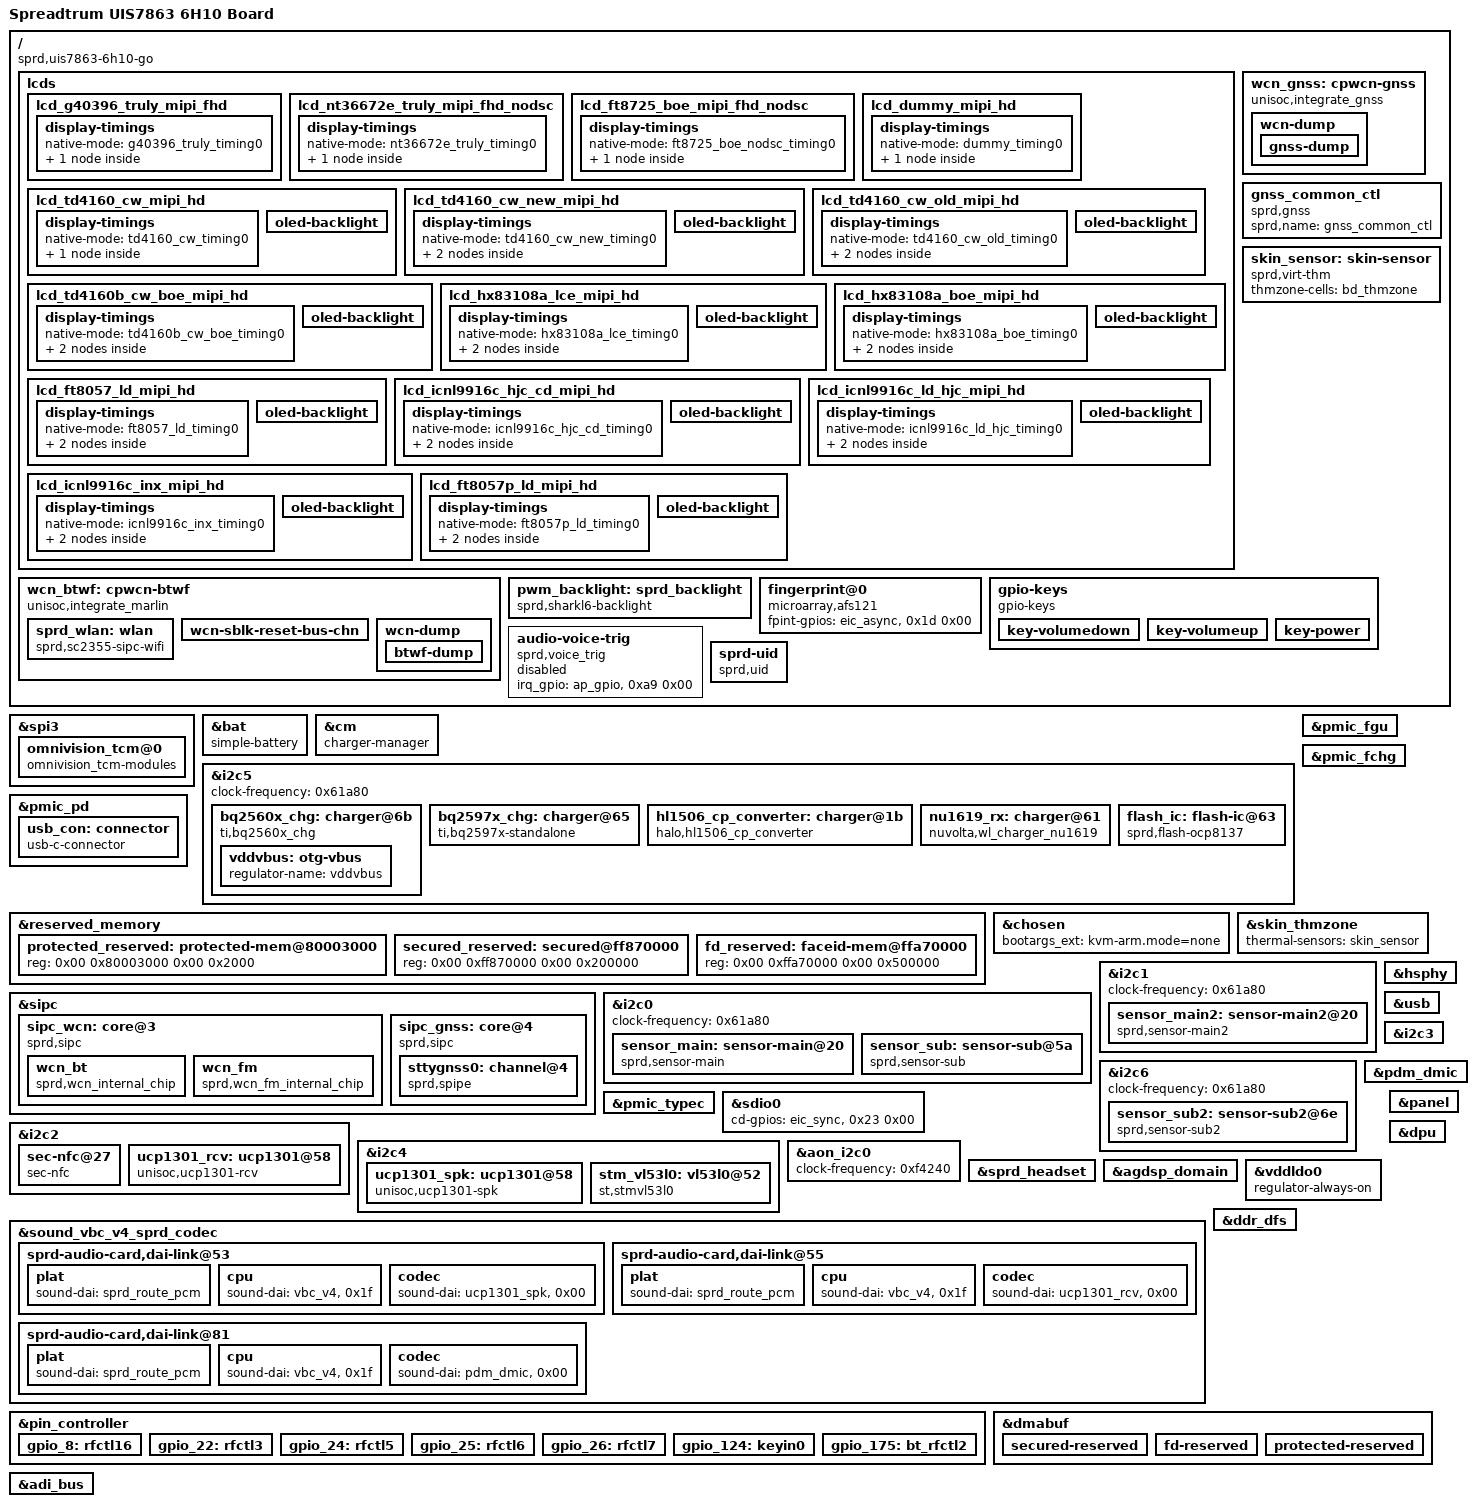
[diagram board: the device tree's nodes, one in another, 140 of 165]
/dts-v1/;
/plugin/;

/ {
	model = "Spreadtrum UIS7863 6H10 Board";
	compatible = "sprd,uis7863-6h10-go";
	sprd,sc-id = "uis7863 6h10 go";
	sprd,board_id = <0x690200>;

	fragment {
		target-path = "/";

		__overlay__ {
			#address-cells = <0x02>;
			#size-cells = <0x02>;

			lcds {

				lcd_g40396_truly_mipi_fhd: lcd_g40396_truly_mipi_fhd {
					sprd,dsi-work-mode = <0x01>;
					sprd,dsi-lane-number = <0x04>;
					sprd,dsi-color-format = "rgb888";
					sprd,phy-bit-clock = <0x104be0>;
					sprd,phy-escape-clock = <0x4e20>;
					sprd,power-gpio-delay = <0x14>;
					sprd,dpi-clk-div = <0x06>;
					sprd,video-lp-cmd-enable = <0x01>;
					sprd,hporch-lp-disable = <0x01>;
					sprd,width-mm = <0x44>;
					sprd,height-mm = <0x98>;
					sprd,slice-width = <0x21c>;
					sprd,slice-height = <0x960>;
					sprd,output-bpc = <0x08>;
					sprd,dsc-enable = <0x00>;
					sprd,dual-dsi-enable = <0x00>;
					sprd,esd-check-enable = <0x01>;
					sprd,esd-check-mode = <0x00>;
					sprd,esd-check-period = <0x7d0>;
					sprd,esd-check-regs = <0x0a>;
					sprd,esd-return-code = <0x9c>;
					sprd,reset-on-sequence = <0x01 0x05 0x00 0x05 0x01 0x14>;
					sprd,reset-off-sequence = <0x00 0x05>;
					sprd,use-dcs-write;
					sprd,initial-command = [29 00 00 02 00 00 29 00 00 04 ff 87 56 01 29 00 00 02 00 80 29 00 00 03 ff 87 56 29 00 00 02 00 a1 29 00 00 07 b3 04 38 09 60 00 fc 29 00 00 02 00 80 29 00 00 07 c0 00 8c 00 20 00 08 29 00 00 02 00 90 29 00 00 07 c0 00 8c 00 20 00 08 29 00 00 02 00 a0 29 00 00 07 c0 01 19 00 20 00 08 29 00 00 02 00 b0 29 00 00 06 c0 00 8c 00 20 08 29 00 00 02 00 c1 29 00 00 09 c0 00 d0 00 9f 00 8b 00 ee 29 00 00 02 00 d7 29 00 00 07 c0 00 8b 00 20 00 08 29 00 00 02 00 a3 29 00 00 07 c1 00 3e 00 3e 00 02 29 00 00 02 00 80 29 00 00 11 ce 01 81 09 13 00 d0 00 e8 00 82 00 9a 00 68 00 74 29 00 00 02 00 90 29 00 00 10 ce 00 8e 0c df 00 8e 80 09 13 00 04 00 08 08 08 29 00 00 02 00 a0 29 00 00 04 ce 00 00 00 29 00 00 02 00 b0 29 00 00 04 ce 22 00 00 29 00 00 02 00 d1 29 00 00 08 ce 00 00 01 00 00 00 00 29 00 00 02 00 e1 29 00 00 0c ce 08 02 4d 02 4d 02 4d 00 00 00 00 29 00 00 02 00 f1 29 00 00 0a ce 13 09 0d 00 f6 01 96 00 c2 29 00 00 02 00 b0 29 00 00 05 cf 00 00 68 6c 29 00 00 02 00 b5 29 00 00 05 cf 04 04 e4 e8 29 00 00 02 00 c0 29 00 00 05 cf 09 09 2c 30 29 00 00 02 00 c5 29 00 00 05 cf 00 00 08 0c 29 00 00 02 00 e8 29 00 00 02 c0 40 29 00 00 02 00 80 29 00 00 05 c2 84 01 3f 3f 29 00 00 02 00 90 29 00 00 05 c2 02 01 00 00 29 00 00 02 00 a0 29 00 00 10 c2 84 04 00 00 8a 83 04 00 00 8a 82 04 00 00 8a 29 00 00 02 00 b0 29 00 00 06 c2 81 04 00 00 8a 29 00 00 02 00 e0 29 00 00 0f c2 33 33 33 33 33 33 00 00 12 00 05 02 00 00 29 00 00 02 00 c0 29 00 00 05 c3 99 99 99 99 29 00 00 02 00 d0 29 00 00 0d c3 45 00 00 05 45 00 00 05 45 00 00 05 29 00 00 02 00 80 29 00 00 11 cb c1 c1 00 c1 c1 00 00 c1 fe 01 c1 00 fd c1 00 c0 29 00 00 02 00 90 29 00 00 11 cb c0 00 00 00 00 00 00 00 ff 00 00 00 00 00 00 00 29 00 00 02 00 a0 29 00 00 05 cb 00 00 00 00 29 00 00 02 00 b0 29 00 00 05 cb 55 55 95 55 29 00 00 02 00 c0 29 00 00 05 cb 10 51 94 50 29 00 00 02 00 80 29 00 00 11 cc 00 00 00 25 25 29 16 17 18 19 1a 1b 22 24 06 06 29 00 00 02 00 90 29 00 00 09 cc 08 08 24 02 12 01 29 29 29 00 00 02 00 80 29 00 00 11 cd 00 00 00 25 25 29 16 17 18 19 1a 1b 22 24 07 07 29 00 00 02 00 90 29 00 00 09 cd 09 09 24 02 12 01 29 29 29 00 00 02 00 a0 29 00 00 11 cc 00 00 00 25 25 29 16 17 18 19 1a 1b 24 23 09 09 29 00 00 02 00 b0 29 00 00 09 cc 07 07 24 12 02 01 29 29 29 00 00 02 00 a0 29 00 00 11 cd 00 00 00 25 25 29 16 17 18 19 1a 1b 24 23 08 08 29 00 00 02 00 b0 29 00 00 09 cd 06 06 24 12 02 01 29 29 29 00 00 02 00 80 29 00 00 02 a7 10 29 00 00 02 00 82 29 00 00 03 a7 33 02 29 00 00 02 00 85 29 00 00 02 a7 10 29 00 00 02 00 85 29 00 00 02 c4 1c 29 00 00 02 00 97 29 00 00 02 c4 01 29 00 00 02 00 a0 29 00 00 04 c4 2d d2 2d 29 00 00 02 00 93 29 00 00 02 c5 29 29 00 00 02 00 97 29 00 00 02 c5 29 29 00 00 02 00 9a 29 00 00 02 c5 23 29 00 00 02 00 9c 29 00 00 02 c5 23 29 00 00 02 00 b6 29 00 00 03 c5 1f 1f 29 00 00 02 00 b8 29 00 00 03 c5 19 19 29 00 00 02 00 9b 29 00 00 02 f5 4b 29 00 00 02 00 93 29 00 00 03 f5 00 00 29 00 00 02 00 9d 29 00 00 02 f5 49 29 00 00 02 00 82 29 00 00 03 f5 00 00 29 00 00 02 00 8c 29 00 00 04 c3 00 00 00 29 00 00 02 00 84 29 00 00 03 c5 28 28 29 00 00 02 00 a4 29 00 00 02 d7 00 29 00 00 02 00 80 29 00 00 03 f5 59 59 29 00 00 02 00 84 29 00 00 04 f5 59 59 59 29 00 00 02 00 96 29 00 00 02 f5 59 29 00 00 02 00 a6 29 00 00 02 f5 59 29 00 00 02 00 ca 29 00 00 02 c0 80 29 00 00 02 00 b1 29 00 00 02 f5 1f 29 00 00 02 00 00 29 00 00 03 d8 2f 2f 29 00 00 02 00 00 29 00 00 03 d9 23 23 29 00 00 02 00 86 29 00 00 07 c0 01 04 01 04 0e 03 29 00 00 02 00 96 29 00 00 07 c0 01 04 01 04 0d 03 29 00 00 02 00 a6 29 00 00 07 c0 01 04 01 04 18 03 29 00 00 02 00 e9 29 00 00 07 c0 01 04 01 04 0d 03 29 00 00 02 00 a3 29 00 00 07 ce 01 04 01 04 0d 03 29 00 00 02 00 b3 29 00 00 07 ce 01 04 01 04 0d 03 29 00 00 02 00 a0 29 00 00 02 d7 04 29 00 00 02 00 00 29 00 00 29 e1 00 04 08 0f 1a 1a 22 28 33 5c 3b 42 48 4d 1b 53 5b 63 6a 2b 72 79 81 8a 3a 95 9b a1 a9 0a b2 bd cb d4 6b e0 ee fa ff 17 29 00 00 02 00 00 29 00 00 29 e2 00 04 08 0f 1a 1a 22 28 33 5c 3b 42 48 4e 18 53 5b 63 6b 28 72 79 81 8a 2a 94 9b a1 a9 ca b2 bd cb d5 68 e0 ee fa ff 67 29 00 00 02 00 00 29 00 00 29 e3 00 03 07 0e 3f 19 21 27 31 46 39 40 47 4c b2 51 5a 61 69 8d 70 77 7f 88 68 92 97 9d a5 2c ad b7 c3 cb 58 d4 df e6 ea 7b 29 00 00 02 00 00 29 00 00 29 e4 00 03 07 0e 3f 19 21 27 31 45 39 40 47 4c b1 51 59 61 69 bd 70 77 7f 87 67 91 97 9d a5 ec ad b7 c3 cb 49 d4 e0 e6 ea 4b 29 00 00 02 00 00 29 00 00 29 e5 00 03 08 0e 33 19 20 27 31 31 39 41 47 4c 87 51 5a 62 69 d6 70 77 7f 88 b8 92 97 9e a5 32 ae b8 c5 ce 2c d8 e6 f0 f5 f6 29 00 00 02 00 00 29 00 00 29 e6 00 03 08 0e 33 19 20 27 31 31 39 41 47 4c 87 51 5a 62 69 d2 70 77 7f 88 b8 92 97 9e a5 32 ae b8 c5 ce 2d d9 e7 f0 f5 06 29 00 00 02 00 cc 29 00 00 02 c0 10 29 00 00 02 00 00 29 00 00 04 ff ff ff ff 15 00 00 02 35 00 15 00 00 02 51 ff 15 00 00 02 53 24 15 00 00 02 55 00 05 b4 00 01 11 05 64 00 01 29];
					sprd,sleep-in-command = <0x15000002 0x3900 0x4ff87 0x56011500 0x20080 0x39000003 0xff875605 0x128 0x5780001 0x10150000 0x2000039 0x5f7 0x5aa59527>;
					sprd,sleep-out-command = [05 78 00 01 11 05 00 00 01 29];
					sprd,sr-width = <0x2d0>;
					sprd,sr-height = <0x640>;
					phandle = <0x2a>;

					display-timings {
						native-mode = <&g40396_truly_timing0>;

						g40396_truly_timing0: timing0 {
							clock-frequency = <0xa9c1080>;
							hactive = <0x438>;
							vactive = <0x960>;
							hback-porch = <0x20>;
							hfront-porch = <0x30>;
							vback-porch = <0x20>;
							vfront-porch = <0x5b>;
							hsync-len = <0x10>;
							vsync-len = <0x04>;
							phandle = <0x01>;
						};
					};
				};

				lcd_nt36672e_truly_mipi_fhd_nodsc: lcd_nt36672e_truly_mipi_fhd_nodsc {
					sprd,dsi-work-mode = <0x01>;
					sprd,dsi-lane-number = <0x04>;
					sprd,dsi-color-format = "rgb888";
					sprd,phy-bit-clock = <0x104be0>;
					sprd,phy-escape-clock = <0x4e20>;
					sprd,dpi-clk-div = <0x06>;
					sprd,video-lp-cmd-enable = <0x01>;
					sprd,hporch-lp-disable = <0x01>;
					sprd,width-mm = <0x44>;
					sprd,height-mm = <0x98>;
					sprd,slice-width = <0x21c>;
					sprd,slice-height = <0x08>;
					sprd,output-bpc = <0x08>;
					sprd,dsc-enable = <0x00>;
					sprd,dual-dsi-enable = <0x00>;
					sprd,esd-check-enable = <0x00>;
					sprd,esd-check-mode = <0x00>;
					sprd,esd-check-period = <0x3e8>;
					sprd,esd-check-register = <0x0a>;
					sprd,esd-check-value = <0x9c>;
					sprd,reset-on-sequence = <0x01 0x0f 0x00 0x0f 0x01 0x0f>;
					sprd,reset-off-sequence = <0x00 0x05>;
					sprd,use-gen-write;
					sprd,initial-command = [15 00 00 02 ff 10 15 00 00 02 fb 01 15 00 00 02 b0 00 15 00 00 02 c0 00 29 00 00 11 c1 89 28 00 08 00 aa 02 0e 00 2b 00 07 0d b7 0c b7 29 00 00 03 c2 1b a0 15 00 00 02 ff 20 15 00 00 02 fb 01 15 00 00 02 01 66 15 00 00 02 06 40 15 00 00 02 07 38 15 00 00 02 2f 83 15 00 00 02 69 91 15 00 00 02 95 d1 15 00 00 02 96 d1 15 00 00 02 f2 64 15 00 00 02 f3 54 15 00 00 02 f4 64 15 00 00 02 f5 54 15 00 00 02 f6 64 15 00 00 02 f7 54 15 00 00 02 f8 64 15 00 00 02 f9 54 15 00 00 02 ff 24 15 00 00 02 fb 01 15 00 00 02 01 0f 15 00 00 02 03 0c 15 00 00 02 05 1d 15 00 00 02 08 2f 15 00 00 02 09 2e 15 00 00 02 0a 2d 15 00 00 02 0b 2c 15 00 00 02 11 17 15 00 00 02 12 13 15 00 00 02 13 15 15 00 00 02 15 14 15 00 00 02 16 16 15 00 00 02 17 18 15 00 00 02 1b 01 15 00 00 02 1d 1d 15 00 00 02 20 2f 15 00 00 02 21 2e 15 00 00 02 22 2d 15 00 00 02 23 2c 15 00 00 02 29 17 15 00 00 02 2a 13 15 00 00 02 2b 15 15 00 00 02 2f 14 15 00 00 02 30 16 15 00 00 02 31 18 15 00 00 02 32 04 15 00 00 02 34 10 15 00 00 02 35 1f 15 00 00 02 36 1f 15 00 00 02 4d 14 15 00 00 02 4e 36 15 00 00 02 4f 36 15 00 00 02 53 36 15 00 00 02 71 30 15 00 00 02 79 11 15 00 00 02 7a 82 15 00 00 02 7b 8f 15 00 00 02 7d 04 15 00 00 02 80 04 15 00 00 02 81 04 15 00 00 02 82 13 15 00 00 02 84 31 15 00 00 02 85 00 15 00 00 02 86 00 15 00 00 02 87 00 15 00 00 02 90 13 15 00 00 02 92 31 15 00 00 02 93 00 15 00 00 02 94 00 15 00 00 02 95 00 15 00 00 02 9c f4 15 00 00 02 9d 01 15 00 00 02 a0 0f 15 00 00 02 a2 0f 15 00 00 02 a3 02 15 00 00 02 a4 04 15 00 00 02 a5 04 15 00 00 02 c6 c0 15 00 00 02 c9 00 15 00 00 02 d9 80 15 00 00 02 e9 02 15 00 00 02 ff 25 15 00 00 02 fb 01 15 00 00 02 18 22 15 00 00 02 19 e4 15 00 00 02 21 40 15 00 00 02 66 d8 15 00 00 02 68 50 15 00 00 02 69 10 15 00 00 02 6b 00 15 00 00 02 6d 0d 15 00 00 02 6e 48 15 00 00 02 72 41 15 00 00 02 73 4a 15 00 00 02 74 d0 15 00 00 02 77 62 15 00 00 02 79 7e 15 00 00 02 7d 03 15 00 00 02 84 4d 15 00 00 02 cf 80 15 00 00 02 d6 80 15 00 00 02 d7 80 15 00 00 02 ef 20 15 00 00 02 f0 84 15 00 00 02 ff 26 15 00 00 02 fb 01 15 00 00 02 81 0f 15 00 00 02 83 01 15 00 00 02 84 03 15 00 00 02 85 01 15 00 00 02 86 03 15 00 00 02 87 01 15 00 00 02 88 05 15 00 00 02 8a 1a 15 00 00 02 8b 11 15 00 00 02 8c 24 15 00 00 02 8e 42 15 00 00 02 8f 11 15 00 00 02 90 11 15 00 00 02 91 11 15 00 00 02 9a 80 15 00 00 02 9b 04 15 00 00 02 9c 00 15 00 00 02 9d 00 15 00 00 02 9e 00 15 00 00 02 ff 27 15 00 00 02 fb 01 15 00 00 02 01 68 15 00 00 02 20 81 15 00 00 02 21 6a 15 00 00 02 25 81 15 00 00 02 26 94 15 00 00 02 6e 00 15 00 00 02 6f 00 15 00 00 02 70 00 15 00 00 02 71 00 15 00 00 02 72 00 15 00 00 02 75 00 15 00 00 02 76 00 15 00 00 02 77 00 15 00 00 02 7d 09 15 00 00 02 7e 67 15 00 00 02 80 23 15 00 00 02 82 09 15 00 00 02 83 67 15 00 00 02 88 01 15 00 00 02 89 10 15 00 00 02 a5 10 15 00 00 02 a6 23 15 00 00 02 a7 01 15 00 00 02 b6 40 15 00 00 02 e5 02 15 00 00 02 e6 d3 15 00 00 02 eb 03 15 00 00 02 ec 28 15 00 00 02 ff 2a 15 00 00 02 fb 01 15 00 00 02 00 91 15 00 00 02 03 20 15 00 00 02 07 50 15 00 00 02 0a 70 15 00 00 02 0c 04 15 00 00 02 0d 40 15 00 00 02 0f 01 15 00 00 02 11 e0 15 00 00 02 15 0f 15 00 00 02 16 a4 15 00 00 02 19 0f 15 00 00 02 1a 78 15 00 00 02 1b 23 15 00 00 02 1d 36 15 00 00 02 1e 3e 15 00 00 02 1f 3e 15 00 00 02 20 3e 15 00 00 02 28 fd 15 00 00 02 29 12 15 00 00 02 2a e1 15 00 00 02 2d 0a 15 00 00 02 30 49 15 00 00 02 33 96 15 00 00 02 34 ff 15 00 00 02 35 40 15 00 00 02 36 de 15 00 00 02 37 f9 15 00 00 02 38 45 15 00 00 02 39 d9 15 00 00 02 3a 49 15 00 00 02 4a f0 15 00 00 02 7a 09 15 00 00 02 7b 40 15 00 00 02 7f f0 15 00 00 02 83 0f 15 00 00 02 84 a4 15 00 00 02 87 0f 15 00 00 02 88 78 15 00 00 02 89 23 15 00 00 02 8b 36 15 00 00 02 8c 7d 15 00 00 02 8d 7d 15 00 00 02 8e 7d 15 00 00 02 ff 2c 15 00 00 02 fb 01 15 00 00 02 61 1f 15 00 00 02 62 1f 15 00 00 02 7e 03 15 00 00 02 6a 14 15 00 00 02 6b 36 15 00 00 02 6c 36 15 00 00 02 6d 36 15 00 00 02 53 04 15 00 00 02 54 04 15 00 00 02 55 04 15 00 00 02 56 0f 15 00 00 02 58 0f 15 00 00 02 59 0f 15 00 00 02 ff 20 15 00 00 02 fb 01 39 00 00 11 b0 00 e2 00 e9 00 f6 01 01 01 0c 01 15 01 20 01 28 39 00 00 11 b1 01 33 01 51 01 6e 01 9a 01 c0 01 fd 02 34 02 35 39 00 00 11 b2 02 6b 02 a9 02 d1 03 04 03 25 03 51 03 5f 03 6d 39 00 00 0f b3 03 7d 03 90 03 a7 03 bb 03 d4 03 d8 00 00 39 00 00 11 b4 00 aa 00 b3 00 c4 00 d4 00 e2 00 f0 00 fc 01 08 39 00 00 11 b5 01 12 01 39 01 58 01 8c 01 b5 01 f7 02 30 02 31 39 00 00 11 b6 02 68 02 a6 02 ce 03 01 03 23 03 4e 03 5c 03 6a 39 00 00 0f b7 03 7b 03 8e 03 a5 03 bb 03 d4 03 d8 00 00 39 00 00 11 b8 00 00 00 20 00 47 00 65 00 85 00 99 00 ad 00 c0 39 00 00 11 b9 00 d2 01 06 01 30 01 70 01 9f 01 e8 02 25 02 26 39 00 00 11 ba 02 5f 02 9f 02 c7 03 fd 03 20 03 52 03 63 03 67 39 00 00 0f bb 03 78 03 8b 03 a3 03 b9 03 d4 03 d8 00 00 15 00 00 02 ff 21 15 00 00 02 fb 01 39 00 00 11 b0 00 e2 00 e9 00 f6 01 01 01 0c 01 15 01 20 01 28 39 00 00 11 b1 01 33 01 51 01 6e 01 9a 01 c0 01 fd 02 34 02 35 39 00 00 11 b2 02 6b 02 a9 02 d1 03 04 03 25 03 51 03 5f 03 6d 39 00 00 0f b3 03 7d 03 90 03 a7 03 bb 03 d4 03 d8 00 00 39 00 00 11 b4 00 aa 00 b3 00 c4 00 d4 00 e2 00 f0 00 fc 01 08 39 00 00 11 b5 01 12 01 39 01 58 01 8c 01 b5 01 f7 02 30 02 31 39 00 00 11 b6 02 68 02 a6 02 ce 03 01 03 23 03 4e 03 5c 03 6a 39 00 00 0f b7 03 7b 03 8e 03 a5 03 bb 03 d4 03 d8 00 00 39 00 00 11 b8 00 00 00 20 00 47 00 65 00 85 00 99 00 ad 00 c0 39 00 00 11 b9 00 d2 01 06 01 30 01 70 01 9f 01 e8 02 25 02 26 39 00 00 11 ba 02 5f 02 9f 02 c7 02 fd 03 20 03 52 03 63 03 67 39 00 00 0f bb 03 78 03 8b 03 a3 03 b9 03 d4 03 d8 00 00 15 00 00 02 ff f0 15 00 00 02 fb 01 15 00 00 02 5a 00 15 00 00 02 ff 10 05 c8 00 01 11 05 32 00 01 29];
					sprd,sleep-in-command = [13 0a 00 01 28 13 78 00 01 10];
					sprd,sleep-out-command = [13 78 00 01 11 13 32 00 01 29];
					sprd,sr-width = <0x2d0>;
					sprd,sr-height = <0x640>;
					phandle = <0x2b>;

					display-timings {
						native-mode = <&nt36672e_truly_timing0>;

						nt36672e_truly_timing0: timing0 {
							clock-frequency = <0xa9c1080>;
							hactive = <0x438>;
							vactive = <0x968>;
							hback-porch = <0x23>;
							hfront-porch = <0x46>;
							vback-porch = <0x20>;
							vfront-porch = <0x20>;
							hsync-len = <0x0a>;
							vsync-len = <0x02>;
							phandle = <0x02>;
						};
					};
				};

				lcd_ft8725_boe_mipi_fhd_nodsc: lcd_ft8725_boe_mipi_fhd_nodsc {
					sprd,dsi-work-mode = <0x01>;
					sprd,dsi-lane-number = <0x04>;
					sprd,dsi-color-format = "rgb888";
					sprd,phy-bit-clock = <0xf9060>;
					sprd,phy-escape-clock = <0x4e20>;
					sprd,dpi-clk-div = <0x06>;
					sprd,video-lp-cmd-enable = <0x01>;
					sprd,hporch-lp-disable = <0x01>;
					sprd,width-mm = <0x44>;
					sprd,height-mm = <0x98>;
					sprd,esd-check-enable = <0x01>;
					sprd,esd-check-mode = <0x00>;
					sprd,esd-check-period = <0x3e8>;
					sprd,esd-check-register = <0x0a>;
					sprd,esd-check-value = <0x9c>;
					sprd,reset-on-sequence = <0x01 0x0f 0x00 0x0f 0x01 0x0f>;
					sprd,reset-off-sequence = <0x01 0x05>;
					sprd,use-gen-write;
					sprd,initial-command = [15 00 00 02 00 00 39 00 00 04 ff 87 25 01 15 00 00 02 00 80 39 00 00 03 ff 87 25 15 00 00 02 00 a3 39 00 00 05 b3 09 60 00 18 15 00 00 02 00 80 39 00 00 07 c0 00 4a 00 32 00 14 15 00 00 02 00 90 39 00 00 07 c0 00 4a 00 32 00 14 15 00 00 02 00 a0 39 00 00 07 c0 00 96 00 32 00 14 15 00 00 02 00 b0 39 00 00 06 c0 00 bb 00 32 14 15 00 00 02 00 c1 39 00 00 09 c0 00 94 00 75 00 63 00 b0 15 00 00 02 00 70 39 00 00 07 c0 00 9e 00 32 00 14 15 00 00 02 00 a3 39 00 00 07 c1 00 5c 00 3a 00 02 15 00 00 02 00 b7 39 00 00 03 c1 00 48 15 00 00 02 00 7b 39 00 00 03 ce ff ff 15 00 00 02 00 80 39 00 00 11 ce 01 81 ff ff 00 c0 00 c8 00 c0 00 c8 00 d0 00 d0 15 00 00 02 00 90 39 00 00 10 ce 00 a7 10 43 00 a7 80 ff ff 00 09 c4 10 0f 11 15 00 00 02 00 a0 39 00 00 04 ce 10 00 00 15 00 00 02 00 b0 39 00 00 04 ce 22 00 00 15 00 00 02 00 d1 39 00 00 08 ce 00 00 01 00 00 00 00 15 00 00 02 00 e1 39 00 00 0c ce 05 01 a1 02 b6 02 b6 00 00 00 00 15 00 00 02 00 f1 39 00 00 0a ce 2a 16 15 00 e8 00 ea 00 ec 15 00 00 02 00 b0 39 00 00 05 cf 00 00 b8 bc 15 00 00 02 00 b5 39 00 00 05 cf 05 05 68 6c 15 00 00 02 00 c0 39 00 00 05 cf 09 09 5b 5f 15 00 00 02 00 c5 39 00 00 05 cf 09 09 61 65 15 00 00 02 00 60 39 00 00 09 cf 00 00 cc d0 05 05 44 48 15 00 00 02 00 70 39 00 00 09 cf 00 00 bc c0 05 05 6c 70 15 00 00 02 00 d1 39 00 00 0d c1 0b 60 0f dc 1b 15 05 af 07 e5 0d 81 15 00 00 02 00 e1 39 00 00 03 c1 0f dc 15 00 00 02 00 e4 39 00 00 0d cf 09 f6 09 f5 09 f5 09 f5 09 f5 09 f5 15 00 00 02 00 80 39 00 00 03 c1 00 00 15 00 00 02 00 90 15 00 00 02 c1 03 15 00 00 02 00 f5 15 00 00 02 cf 00 15 00 00 02 00 f6 15 00 00 02 cf 78 15 00 00 02 00 f1 15 00 00 02 cf 78 15 00 00 02 00 93 15 00 00 02 c1 82 15 00 00 02 00 cc 15 00 00 02 c1 18 15 00 00 02 00 91 15 00 00 02 c4 08 15 00 00 02 00 80 39 00 00 03 c5 87 59 15 00 00 02 00 9e 15 00 00 02 c5 87 15 00 00 02 00 87 39 00 00 03 c4 08 08 15 00 00 02 00 80 39 00 00 09 c2 83 01 06 88 82 01 06 88 15 00 00 02 00 a0 39 00 00 10 c2 8a 07 00 06 88 89 08 00 06 88 88 09 00 06 88 15 00 00 02 00 b0 39 00 00 06 c2 87 0a 00 06 88 15 00 00 02 00 e0 39 00 00 05 c2 33 33 00 00 15 00 00 02 00 e8 39 00 00 09 c2 12 00 0a 0a 03 88 00 00 15 00 00 02 00 d0 39 00 00 11 c3 35 0a 00 00 35 0a 00 00 35 0a 00 00 35 0a 00 00 15 00 00 02 00 e0 39 00 00 11 c3 35 0a 00 00 35 0a 00 00 35 0a 00 00 35 0a 00 00 15 00 00 02 00 80 39 00 00 11 cb cd cd cc 00 cd cc 00 cd ce fe cd 00 cc cc 00 00 15 00 00 02 00 90 39 00 00 11 cb 0c 00 00 00 0c 0c 00 00 0c 00 00 00 00 00 00 00 15 00 00 02 00 a0 39 00 00 09 cb 00 00 00 00 00 00 00 00 15 00 00 02 00 b0 39 00 00 05 cb 50 41 a4 00 15 00 00 02 00 c0 39 00 00 05 cb 50 41 a4 00 15 00 00 02 00 d5 39 00 00 0c cb 83 00 83 83 00 83 83 00 83 83 00 15 00 00 02 00 e0 39 00 00 0e cb 83 83 00 83 83 00 83 83 00 83 83 00 83 15 00 00 02 00 80 39 00 00 11 cc 18 17 16 2c 07 06 09 08 2c 25 25 26 26 2c 24 2c 15 00 00 02 00 90 39 00 00 09 cc 22 23 23 01 03 02 26 26 15 00 00 02 00 a0 39 00 00 11 cc 18 17 16 2c 08 09 06 07 2c 25 25 22 22 2c 24 2c 15 00 00 02 00 b0 39 00 00 09 cc 26 23 23 01 02 03 26 26 15 00 00 02 00 80 39 00 00 11 cd 18 17 16 2c 07 06 09 08 2c 25 25 26 26 2c 24 2c 15 00 00 02 00 90 39 00 00 09 cd 22 23 23 01 03 02 26 26 15 00 00 02 00 a0 39 00 00 11 cd 18 17 16 2c 08 09 06 07 2c 25 25 22 22 2c 24 2c 15 00 00 02 00 b0 39 00 00 09 cd 26 23 23 01 02 03 26 26 15 00 00 02 00 86 39 00 00 09 c0 01 02 01 02 13 13 13 03 15 00 00 02 00 96 39 00 00 09 c0 01 02 01 01 13 13 13 04 15 00 00 02 00 a6 39 00 00 09 c0 01 02 01 01 28 28 28 04 15 00 00 02 00 a3 39 00 00 07 ce 01 02 01 05 28 02 15 00 00 02 00 b3 39 00 00 07 ce 01 02 01 05 28 02 15 00 00 02 00 76 39 00 00 09 c0 01 02 01 05 28 28 28 02 15 00 00 02 00 82 39 00 00 03 a7 20 00 15 00 00 02 00 8d 15 00 00 02 a7 02 15 00 00 02 00 8f 15 00 00 02 a7 01 15 00 00 02 00 93 15 00 00 02 c5 37 15 00 00 02 00 97 15 00 00 02 c5 37 15 00 00 02 00 9a 15 00 00 02 c5 23 15 00 00 02 00 9c 15 00 00 02 c5 23 15 00 00 02 00 b6 39 00 00 05 c5 2d 2d 19 19 15 00 00 02 00 00 39 00 00 03 d8 2f 27 15 00 00 02 00 00 39 00 00 05 d9 23 23 23 23 15 00 00 02 00 06 39 00 00 04 d9 23 23 23 15 00 00 02 00 88 15 00 00 02 c4 08 15 00 00 02 00 80 15 00 00 02 a7 10 15 00 00 02 00 a0 39 00 00 11 c3 00 01 23 45 21 03 45 00 00 00 21 03 45 01 23 45 15 00 00 02 00 b1 15 00 00 02 f5 1f 15 00 00 02 00 cb 15 00 00 02 c0 01 15 00 00 02 00 88 15 00 00 02 c4 08 15 00 00 02 00 94 15 00 00 02 e9 00 15 00 00 02 00 9a 15 00 00 02 c4 11 15 00 00 02 00 95 15 00 00 02 e9 10 15 00 00 02 00 82 15 00 00 02 f5 00 15 00 00 02 00 93 15 00 00 02 f5 00 15 00 00 02 00 99 15 00 00 02 cf 50 15 00 00 02 00 9c 15 00 00 02 f5 00 15 00 00 02 00 9e 15 00 00 02 f5 00 15 00 00 02 00 b0 39 00 00 07 c5 10 4a 01 1f 4a 00 15 00 00 02 00 a0 39 00 00 08 b0 00 00 00 00 00 1d 01 15 00 00 02 00 93 39 00 00 04 e9 ff ff b0 15 00 00 02 00 9b 15 00 00 02 c4 08 15 00 00 02 00 87 15 00 00 02 f5 00 15 00 00 02 00 80 15 00 00 02 a4 c9 15 00 00 02 00 87 39 00 00 03 c5 08 08 15 00 00 02 00 be 39 00 00 03 c5 c0 c0 15 00 00 02 00 e8 15 00 00 02 c0 40 15 00 00 02 00 00 39 00 00 29 e1 00 02 07 0f 3f 1b 24 2a 35 ce 3e 45 4b 50 06 55 5d 65 6c 7b 74 7b 83 8c 14 96 9c a2 aa 49 b3 bd cb d4 34 df ee f8 ff dc 15 00 00 02 00 30 39 00 00 29 e1 00 02 07 0f 3f 1b 24 2a 35 ce 3e 45 4b 50 06 55 5d 65 6c 7b 74 7b 83 8c 14 96 9c a2 aa 49 b3 bd cb d4 34 df ee f8 ff dc 15 00 00 02 00 60 39 00 00 29 e1 00 02 07 0f 3f 1b 24 2a 35 ce 3e 45 4b 50 06 55 5d 65 6c 7b 74 7b 83 8c 14 96 9c a2 aa 49 b3 bd cb d4 34 df ee f8 ff dc 15 00 00 02 00 90 39 00 00 29 e1 00 02 07 0f 3f 1b 24 2a 35 ce 3e 45 4b 50 06 55 5d 65 6c 7b 74 7b 83 8c 14 96 9c a2 aa 49 b3 bd cb d4 34 df ee f8 ff dc 15 00 00 02 00 c0 39 00 00 29 e1 00 02 07 0f 3f 1b 24 2a 35 ce 3e 45 4b 50 06 55 5d 65 6c 7b 74 7b 83 8c 14 96 9c a2 aa 49 b3 bd cb d4 34 df ee f8 ff dc 15 00 00 02 00 f0 39 00 00 11 e1 00 02 07 0f 3f 1b 24 2a 35 ce 3e 45 4b 50 06 55 15 00 00 02 00 00 39 00 00 19 e2 5d 65 6c 7b 74 7b 83 8c 14 96 9c a2 aa 49 b3 bd cb d4 34 df ee f8 ff dc 15 00 00 02 00 e0 15 00 00 02 cf 34 15 00 00 02 00 85 15 00 00 02 a7 00 15 00 00 02 00 80 15 00 00 02 b3 22 15 00 00 02 00 b0 15 00 00 02 b3 00 15 00 00 02 00 81 39 00 00 03 a4 23 23 15 00 00 02 00 90 15 00 00 02 e9 50 15 00 00 02 1c 02 05 78 00 01 11 05 14 00 01 29];
					sprd,sleep-in-command = [13 32 00 01 28 13 78 00 01 10];
					sprd,sleep-out-command = [13 78 00 01 11 13 32 00 01 29];
					phandle = <0x2c>;

					display-timings {
						native-mode = <&ft8725_boe_nodsc_timing0>;

						ft8725_boe_nodsc_timing0: timing0 {
							clock-frequency = <0xa21fe80>;
							hactive = <0x438>;
							vactive = <0x960>;
							hback-porch = <0x18>;
							hfront-porch = <0x18>;
							vback-porch = <0x1e>;
							vfront-porch = <0x2e>;
							hsync-len = <0x0c>;
							vsync-len = <0x0a>;
							phandle = <0x03>;
						};
					};
				};

				lcd_dummy_mipi_hd: lcd_dummy_mipi_hd {
					sprd,dsi-work-mode = <0x01>;
					sprd,dsi-lane-number = <0x04>;
					sprd,dsi-color-format = "rgb888";
					sprd,initial-command = [13 78 00 01 11 13 64 00 01 29];
					sprd,sleep-in-command = [13 0a 00 01 28 13 78 00 01 10];
					sprd,sleep-out-command = [13 78 00 01 11 13 64 00 01 29];
					phandle = <0x2d>;

					display-timings {
						native-mode = <&dummy_timing0>;

						dummy_timing0: timing0 {
							clock-frequency = <0x493e000>;
							hactive = <0x2d0>;
							vactive = <0x500>;
							hback-porch = <0x3c>;
							hfront-porch = <0x50>;
							vback-porch = <0x0c>;
							vfront-porch = <0x26>;
							hsync-len = <0x3c>;
							vsync-len = <0x04>;
							phandle = <0x04>;
						};
					};
				};

				lcd_td4160_cw_mipi_hd: lcd_td4160_cw_mipi_hd {
					sprd,dsi-work-mode = <0x01>;
					sprd,dsi-lane-number = <0x04>;
					sprd,dsi-color-format = "rgb888";
					sprd,phy-bit-clock = <0xa8b38>;
					sprd,phy-escape-clock = <0x4e20>;
					sprd,width-mm = <0x44>;
					sprd,height-mm = <0x97>;
					sprd,esd-check-enable = <0x00>;
					sprd,esd-check-mode = <0x01>;
					sprd,esd-check-period = <0x7d0>;
					sprd,reset-on-sequence = <0x00 0x05 0x01 0x1e>;
					sprd,reset-off-sequence = <0x00 0x05>;
					sprd,use-dcs-write;
					sprd,initial-command = [29 00 00 02 b0 00 29 00 00 02 d6 00 29 00 00 07 b6 30 62 00 86 c3 03 29 00 00 05 b7 31 00 00 00 29 00 00 07 b8 02 4a 06 00 04 5a 29 00 00 07 b9 02 4a 18 00 09 b4 29 00 00 07 ba 20 00 00 00 00 00 29 00 00 04 bb 00 b4 a0 29 00 00 04 bc 00 b4 a0 29 00 00 04 bd 00 b4 a0 29 00 00 0e be 07 00 00 00 00 00 00 00 00 00 00 00 00 29 00 00 19 c0 00 80 18 06 4c 00 16 08 68 00 70 00 00 00 00 00 00 00 00 00 00 00 00 00 29 00 00 28 c1 30 41 50 fa 01 00 00 10 00 00 00 00 40 0f 00 00 00 00 00 00 00 00 00 00 00 00 00 00 00 00 00 00 00 00 00 00 00 00 00 29 00 00 f5 c2 00 00 50 14 06 10 0e 00 00 00 00 50 12 06 10 0a 00 00 00 00 50 12 06 06 69 00 00 00 00 00 00 00 00 00 00 00 00 00 00 00 00 00 05 d0 56 0c 0c 06 00 c1 00 b0 01 03 00 41 00 00 00 00 00 11 00 00 00 00 00 00 00 00 00 00 00 00 00 00 00 00 00 00 00 00 00 00 00 00 00 00 00 00 00 00 00 11 00 00 00 00 00 00 00 00 00 00 00 00 00 00 00 00 00 00 00 00 00 00 00 00 00 00 00 00 00 00 00 11 00 00 00 00 00 00 00 00 00 00 00 00 00 00 00 00 00 00 00 00 00 00 00 00 00 00 00 00 00 00 00 11 00 00 00 00 00 00 00 00 00 00 00 00 00 00 00 00 00 00 00 00 00 00 00 00 00 00 00 00 00 00 00 00 00 00 00 00 00 00 00 10 00 00 00 00 00 00 00 00 00 00 00 00 00 00 00 02 00 00 00 00 00 00 00 00 00 00 02 00 00 00 00 00 00 00 00 00 00 00 00 00 00 00 00 00 00 00 29 00 00 6a c3 00 00 50 01 67 10 05 00 00 00 20 00 04 e0 00 41 64 c0 02 00 00 00 20 00 00 00 00 00 00 00 00 00 00 00 20 00 00 00 00 00 00 00 00 00 00 00 20 00 00 00 00 08 00 00 00 00 00 00 00 00 00 00 00 00 00 00 00 00 00 00 00 00 00 00 00 00 00 00 00 00 00 00 00 00 00 00 00 00 00 00 00 00 00 00 00 00 00 00 00 00 00 00 00 00 00 29 00 00 55 c4 00 5f 5f 0c 5d 04 06 08 01 14 14 16 16 18 18 1a 1a 1c 1c 1e 1e 5f 00 00 5f 1d 1d 1b 1b 19 19 17 17 15 15 13 13 01 07 05 03 5d 0b 5f 5f 00 00 00 00 00 00 00 ff 0f ff 0f 00 00 00 00 00 00 00 00 00 00 00 00 00 33 33 00 00 55 55 55 55 55 41 55 55 55 55 55 29 00 00 06 c5 08 00 00 00 00 29 00 00 4d c6 00 00 00 00 01 22 04 22 01 00 53 00 00 00 01 00 53 00 01 05 01 0b 01 35 ff 8f 06 15 01 c0 07 00 00 00 00 00 00 00 00 00 00 00 00 00 00 00 00 00 00 00 00 00 00 20 20 00 00 00 c0 11 00 00 00 10 10 00 00 00 01 00 50 00 33 03 00 00 29 00 00 1f cb 02 d0 01 80 00 00 00 00 00 00 00 00 00 00 00 00 00 00 00 00 00 00 40 70 00 00 00 00 00 ff 29 00 00 19 ce 16 40 60 78 87 94 9e ab b8 c4 cd d6 de e5 ec f3 ff 07 0f 00 00 00 04 8c 29 00 00 02 cf 00 29 00 00 15 d0 c1 50 81 66 09 90 00 cc 92 9f 11 1e 06 7e 09 08 cc 1b f0 06 29 00 00 26 d1 d0 d0 1b 33 33 17 07 bb 22 52 22 52 00 3b 77 07 3b 30 06 72 33 13 00 d7 0c 22 02 00 18 70 18 77 11 11 11 20 20 29 00 00 04 d2 00 00 00 29 00 00 9a d3 00 00 00 00 00 00 00 00 00 ff f7 ff ff f7 ff ff f7 ff ff f7 ff ff f7 ff ff f7 ff ff f7 ff ff f7 ff ff f7 ff ff f7 ff ff f7 ff ff f7 ff ff f7 ff ff f7 ff ff f7 ff ff f7 ff ff f7 ff ff f7 ff ff f7 ff ff f7 ff ff f7 ff ff f7 ff ff f7 ff ff f7 ff ff f7 ff ff f7 ff ff f7 ff ff f7 ff ff f7 ff ff f7 ff ff f7 ff ff f7 ff ff f7 ff ff f7 ff ff f7 ff ff f7 ff ff f7 ff ff f7 ff ff f7 ff ff f7 ff ff f7 ff ff f7 ff ff f7 ff ff f7 ff ff f7 ff ff f7 ff ff f7 ff ff f7 ff 29 00 00 18 d4 00 00 00 00 00 00 00 00 00 20 00 00 00 00 20 00 00 00 00 00 00 00 00 29 00 00 2f d7 01 00 12 12 00 54 01 04 00 54 01 04 03 83 80 85 85 85 87 84 45 86 87 80 88 86 89 83 83 87 84 88 8a 0c 0b 0a 0a 0a 07 07 06 06 00 08 0a 0a 29 00 00 17 d8 40 99 26 ed 16 6c 16 6c 16 6c 00 14 00 14 00 14 01 0c 00 00 01 00 29 00 00 29 d9 00 02 7f 00 00 00 00 00 00 00 00 00 00 00 00 c0 00 00 00 00 00 00 00 00 00 00 00 00 00 00 00 00 00 00 00 00 00 00 00 00 29 00 00 05 dd 30 06 23 65 29 00 00 0f de 00 00 00 0f ff 00 00 00 00 10 00 00 00 00 29 00 00 09 e6 00 00 00 00 00 00 00 00 29 00 00 24 ea 02 0e 0e 06 80 07 40 74 00 00 00 03 33 07 07 00 54 00 54 00 54 01 28 01 28 00 54 00 54 00 54 00 08 02 00 29 00 00 09 eb 08 30 83 0b 41 01 08 00 29 00 00 18 ec 05 f0 01 70 6b 07 40 74 00 00 00 02 2a 00 00 00 00 00 00 00 00 00 00 29 00 00 22 ed 01 02 00 00 00 00 00 00 67 c6 fe 00 00 00 00 00 00 00 00 00 00 00 02 b0 00 00 00 00 00 00 c0 10 00 29 00 00 7a ee 05 00 01 00 c0 57 00 c0 57 00 c0 57 00 00 03 00 c0 57 00 00 00 00 00 00 03 00 00 00 00 00 00 03 00 00 00 00 00 00 03 00 00 00 00 00 00 03 00 c0 57 00 00 00 00 00 c0 0f 00 00 00 00 00 00 57 00 00 00 00 00 00 03 00 00 00 00 00 00 03 00 00 03 00 00 03 00 00 03 00 00 03 00 00 03 00 00 03 00 00 00 00 00 00 00 00 00 00 00 00 00 00 00 00 00 00 00 00 00 00 00 00 00 02 29 00 00 0c f9 20 3f e0 00 00 07 ff 00 00 07 ff 29 00 00 4d c7 00 00 00 55 00 c2 01 0f 01 82 01 b5 01 b5 01 ba 01 b2 01 b1 01 ad 01 a7 01 a3 01 8c 01 99 02 2c 02 6f 02 9d 02 ff 00 00 00 55 00 c2 01 0f 01 82 01 b5 01 b5 01 ba 01 b2 01 b1 01 ad 01 a7 01 a3 01 8c 01 99 02 2c 02 6f 02 9d 02 ff 29 00 00 03 51 03 ff 29 00 00 02 53 2c 29 00 00 02 55 00 29 00 00 02 b0 03 05 60 00 01 11 05 20 00 01 29];
					sprd,sleep-in-command = [05 14 00 01 28 05 78 00 01 10];
					sprd,sleep-out-command = [05 14 00 01 11 05 78 00 01 29];
					sprd,cabc-off-command = [23 00 00 02 55 00];
					sprd,cabc-ui-command = [23 00 00 02 55 01];
					sprd,cabc-still-command = [23 00 00 02 55 02];
					sprd,cabc-moving-command = [23 00 00 02 55 03];
					phandle = <0x12>;

					display-timings {
						native-mode = <&td4160_cw_timing0>;

						td4160_cw_timing0: timing0 {
							clock-frequency = <0x5b8d800>;
							hactive = <0x2d0>;
							vactive = <0x64c>;
							hback-porch = <0x18>;
							hfront-porch = <0x38>;
							vback-porch = <0x1e>;
							vfront-porch = <0xac>;
							hsync-len = <0x04>;
							vsync-len = <0x04>;
							phandle = <0x05>;
						};
					};

					oled-backlight {
						default-brightness = <0x51a>;
						sprd,max-level = <0xfff>;
						brightness-levels = [39 00 00 03 51 00 04];
					};
				};

				lcd_td4160_cw_new_mipi_hd: lcd_td4160_cw_new_mipi_hd {
					sprd,dsi-work-mode = <0x01>;
					sprd,dsi-lane-number = <0x04>;
					sprd,dsi-color-format = "rgb888";
					sprd,phy-bit-clock = <0xf6180>;
					sprd,phy-escape-clock = <0x4e20>;
					sprd,dpi-clk-div = <0x06>;
					sprd,video-lp-cmd-enable = <0x01>;
					sprd,hporch-lp-disable = <0x01>;
					sprd,width-mm = <0x47>;
					sprd,height-mm = <0x9c>;
					sprd,esd-check-enable = <0x01>;
					sprd,esd-check-mode = <0x00>;
					sprd,esd-check-period = <0x7d0>;
					sprd,esd-check-register = <0x0a>;
					sprd,esd-check-value = <0x9c>;
					sprd,fixed-brightness = <0x01>;
					sprd,power-i2c-bus = <0x04>;
					sprd,power-i2c-addr = <0x3e>;
					sprd,power-i2c-reg = [00 01 03];
					sprd,power-i2c-val = [14 14 43];
					sprd,reset-on-sequence = <0x01 0x05 0x00 0x05 0x01 0x1e>;
					sprd,reset-off-sequence = <0x00 0x05>;
					sprd,video-lp-en-mode = <0x02>;
					sprd,use-dcs-write;
					sprd,initial-command = [39 00 00 02 b0 04 39 00 00 02 d6 00 39 00 00 07 b6 30 6a 00 86 c3 03 39 00 00 05 b7 31 00 00 00 39 00 00 07 b8 02 50 09 00 04 40 39 00 00 07 b9 02 09 18 00 09 46 39 00 00 07 ba 02 90 00 00 00 00 39 00 00 04 bb 00 b4 a0 39 00 00 04 bc 00 b4 a0 39 00 00 04 bd 00 b4 a0 39 00 00 0e be 07 00 00 00 00 00 00 00 00 00 00 00 00 39 00 00 19 c0 00 60 24 06 40 00 16 06 98 00 70 00 00 00 00 00 00 00 00 00 00 00 00 00 39 00 00 28 c1 30 81 50 fa 01 00 00 10 00 00 00 00 40 0f 00 00 00 00 00 00 00 00 00 00 00 00 00 00 00 00 00 00 f0 07 08 07 d0 0a be 39 00 00 65 c2 01 20 50 14 04 10 0b 10 00 00 00 00 00 00 00 00 00 00 00 00 00 00 00 00 00 00 00 00 00 00 00 00 00 00 00 00 00 00 00 00 00 00 05 f0 54 08 08 05 05 c5 00 80 00 00 00 00 08 00 00 00 00 11 00 80 00 08 00 00 00 00 00 00 00 00 00 00 00 00 00 00 00 00 00 00 00 00 00 00 00 00 00 00 00 11 00 00 00 00 00 00 39 00 00 65 c3 01 00 55 01 01 86 68 00 00 00 20 01 01 00 55 01 01 86 68 00 00 00 20 02 01 00 55 01 01 86 68 00 00 00 20 00 01 00 55 01 01 86 68 00 00 00 20 00 00 00 00 08 00 00 00 00 00 00 00 00 00 00 00 00 00 00 00 00 00 00 00 00 00 00 00 00 00 00 00 00 00 00 00 00 00 00 00 00 00 00 00 00 00 00 00 00 00 00 00 00 39 00 00 55 c4 00 00 5e 64 00 03 05 13 15 17 19 5d 5f 00 00 00 00 00 00 00 00 00 00 00 00 00 00 00 00 00 00 00 00 5f 5d 1a 18 16 14 06 04 00 64 5e 00 00 00 00 00 00 00 c0 03 00 00 3c 00 00 00 00 00 00 00 00 00 00 00 00 00 57 57 00 00 57 55 55 ff ff ff ff ff 55 55 d5 39 00 00 06 c5 08 00 00 00 00 39 00 00 4d c6 00 00 00 00 01 22 04 22 01 00 61 00 00 00 01 00 61 00 01 05 01 0b 01 35 ff 8f 06 c5 02 c0 0f 00 00 00 00 00 00 00 00 00 00 00 00 00 00 00 00 00 00 00 00 00 00 20 20 00 00 00 c0 11 00 00 00 10 10 00 00 00 01 00 50 00 33 03 00 00 39 00 00 1f cb 02 d0 01 80 00 00 00 00 00 00 00 00 00 00 00 00 00 00 00 00 00 00 40 70 00 00 00 00 00 ff 39 00 00 19 ce 16 56 66 88 9b aa bb c0 c8 cd d2 d8 e1 e7 ec f0 f3 07 0f 00 00 00 04 8c 39 00 00 02 cf 00 39 00 00 15 d0 c1 46 81 66 09 90 00 cc f2 ff 11 46 06 7e 09 08 cc 1b f0 06 39 00 00 26 d1 ce d8 1b 33 33 17 07 bb 22 52 22 52 00 3b 77 07 3b 30 06 72 33 13 00 d7 0c 22 02 00 18 70 18 77 11 11 11 20 20 39 00 00 04 d2 00 00 00 39 00 00 65 d3 00 00 00 00 00 00 00 00 00 ff f7 ff ff f7 ff ff f7 ff ff f7 ff ff f7 ff ff f7 ff ff f7 ff ff f7 ff ff f7 ff ff f7 ff ff f7 ff ff f7 ff ff f7 ff ff f7 ff ff f7 ff ff f7 ff ff f7 ff ff f7 ff ff f7 ff ff f7 ff ff f7 ff ff f7 ff ff f7 ff ff f7 ff ff f7 ff ff f7 ff ff f7 ff ff f7 ff ff f7 ff ff f7 ff ff 39 00 00 18 d4 00 00 00 00 00 00 00 00 00 20 00 00 00 00 20 00 00 00 00 00 00 00 00 39 00 00 02 d6 00 39 00 00 2f d7 01 00 12 12 00 62 00 16 00 62 00 16 03 83 80 85 85 85 87 84 45 86 87 80 88 86 89 83 83 87 84 88 8a 0c 0b 0a 0a 0a 07 07 06 06 00 08 0a 0a 39 00 00 17 d8 40 99 26 ed 16 6c 16 6c 16 6c 00 14 00 14 00 14 01 0c 00 00 01 00 39 00 00 29 d9 00 02 7f 00 00 00 00 00 00 00 00 00 00 00 00 c0 00 00 00 00 00 00 00 00 00 00 00 00 00 00 00 00 00 00 00 00 00 00 00 00 39 00 00 05 dd 30 06 23 65 39 00 00 0f de 00 00 00 0f ff 00 00 00 00 10 00 00 00 00 39 00 00 05 e5 03 00 00 00 39 00 00 09 e6 00 00 00 00 00 0e 00 00 39 00 00 24 ea 02 07 07 04 80 10 01 00 00 00 00 03 23 00 07 00 ed 00 ed 00 ed 01 28 01 28 00 62 00 62 00 62 01 0f 01 00 39 00 00 09 eb 06 e0 6e 07 61 01 01 00 39 00 00 18 ec 02 d0 01 70 73 10 01 00 00 00 00 02 2a 00 00 00 00 00 00 00 00 00 00 39 00 00 22 ed 01 02 00 00 00 00 00 00 67 a6 f0 00 00 00 00 00 00 00 00 00 00 00 00 f0 01 00 00 00 00 00 41 10 01 39 00 00 65 ee 05 00 05 00 c0 0b 00 00 03 00 00 03 00 00 03 00 c0 03 00 00 00 00 00 00 03 00 00 00 00 00 00 03 00 00 00 00 00 00 03 00 00 00 00 00 00 03 00 40 03 04 65 40 00 00 55 17 04 65 40 00 00 55 03 04 65 40 00 00 40 17 04 65 40 00 00 00 03 00 00 03 00 00 03 00 00 03 00 00 03 00 00 03 00 00 03 00 40 15 00 00 39 00 00 0c f9 20 3f e0 00 00 07 ff 00 00 07 ff 39 00 00 02 35 00 39 00 00 4d c7 00 00 00 77 00 ca 00 e7 01 00 01 0b 01 1a 01 1d 01 3d 01 0f 01 67 01 2d 01 78 01 2b 01 9b 01 a6 02 2f 02 96 02 a0 00 00 00 77 00 ca 00 e7 01 00 01 0b 01 1a 01 1d 01 3d 01 0f 01 67 01 2d 01 78 01 2b 01 9b 01 a6 02 2f 02 96 02 a0 39 00 00 02 53 24 39 00 00 02 55 00 39 00 00 02 b0 03 05 60 00 01 11 05 20 00 01 29];
					sprd,sleep-in-command = [05 14 00 01 28 05 78 00 01 10];
					sprd,sleep-out-command = [05 14 00 01 11 05 78 00 01 29];
					sprd,cabc-off-command = [39 00 00 02 55 03];
					sprd,cabc-ui-command = [39 00 00 02 55 01];
					sprd,cabc-still-command = [39 00 00 02 55 02];
					sprd,cabc-moving-command = [39 00 00 02 55 03];
					phandle = <0x11>;

					display-timings {
						native-mode = <&td4160_cw_new_timing0>;

						td4160_cw_new_timing0: timing0 {
							clock-frequency = <0xa037a00>;
							hactive = <0x2d0>;
							vactive = <0x640>;
							hback-porch = <0x68>;
							hfront-porch = <0xe0>;
							vback-porch = <0x20>;
							vfront-porch = <0x3fe>;
							hsync-len = <0x04>;
							vsync-len = <0x04>;
							phandle = <0x06>;
						};

						td4160_cw_new_timing1: timing1 {
							clock-frequency = <0xa037a00>;
							hactive = <0x2d0>;
							vactive = <0x640>;
							hback-porch = <0x64>;
							hfront-porch = <0xe0>;
							vback-porch = <0x20>;
							vfront-porch = <0x90>;
							hsync-len = <0x04>;
							vsync-len = <0x04>;
							phandle = <0x2e>;
						};
					};

					oled-backlight {
						default-brightness = <0x51a>;
						sprd,max-level = <0xfff>;
						brightness-levels = [39 00 00 03 51 00 00];
					};
				};

				lcd_td4160_cw_old_mipi_hd: lcd_td4160_cw_old_mipi_hd {
					sprd,dsi-work-mode = <0x01>;
					sprd,dsi-lane-number = <0x04>;
					sprd,dsi-color-format = "rgb888";
					sprd,phy-bit-clock = <0xf6180>;
					sprd,phy-escape-clock = <0x4e20>;
					sprd,dpi-clk-div = <0x06>;
					sprd,video-lp-cmd-enable = <0x01>;
					sprd,hporch-lp-disable = <0x01>;
					sprd,width-mm = <0x47>;
					sprd,height-mm = <0x9c>;
					sprd,esd-check-enable = <0x01>;
					sprd,esd-check-mode = <0x00>;
					sprd,esd-check-period = <0x7d0>;
					sprd,esd-check-register = <0x0a>;
					sprd,esd-check-value = <0x9c>;
					sprd,fixed-brightness = <0x01>;
					sprd,power-i2c-bus = <0x04>;
					sprd,power-i2c-addr = <0x3e>;
					sprd,power-i2c-reg = [00 01 03];
					sprd,power-i2c-val = [14 14 43];
					sprd,reset-on-sequence = <0x01 0x05 0x00 0x05 0x01 0x1e>;
					sprd,reset-off-sequence = <0x00 0x05>;
					sprd,video-lp-en-mode = <0x02>;
					sprd,use-dcs-write;
					sprd,initial-command = [39 00 00 02 b0 04 39 00 00 02 d6 00 39 00 00 07 b6 30 6a 00 86 c3 03 39 00 00 05 b7 31 00 00 00 39 00 00 07 b8 02 50 09 00 04 40 39 00 00 07 b9 02 09 18 00 09 46 39 00 00 07 ba 02 90 00 00 00 00 39 00 00 04 bb 00 b4 a0 39 00 00 04 bc 00 b4 a0 39 00 00 04 bd 00 b4 a0 39 00 00 0e be 07 00 00 00 00 00 00 00 00 00 00 00 00 39 00 00 19 c0 00 60 24 06 40 00 16 06 98 00 70 00 00 00 00 00 00 00 00 00 00 00 00 00 39 00 00 28 c1 30 81 50 fa 01 00 00 10 00 00 00 00 40 0f 00 00 00 00 00 00 00 00 00 00 00 00 00 00 00 00 00 00 f0 07 08 07 d0 0a be 39 00 00 65 c2 01 20 50 14 04 10 0b 10 00 00 00 00 00 00 00 00 00 00 00 00 00 00 00 00 00 00 00 00 00 00 00 00 00 00 00 00 00 00 00 00 00 00 05 f0 54 08 08 05 05 c5 00 80 00 00 00 00 08 00 00 00 00 11 00 80 00 08 00 00 00 00 00 00 00 00 00 00 00 00 00 00 00 00 00 00 00 00 00 00 00 00 00 00 00 11 00 00 00 00 00 00 39 00 00 65 c3 01 00 55 01 01 86 68 00 00 00 20 01 01 00 55 01 01 86 68 00 00 00 20 02 01 00 55 01 01 86 68 00 00 00 20 00 01 00 55 01 01 86 68 00 00 00 20 00 00 00 00 08 00 00 00 00 00 00 00 00 00 00 00 00 00 00 00 00 00 00 00 00 00 00 00 00 00 00 00 00 00 00 00 00 00 00 00 00 00 00 00 00 00 00 00 00 00 00 00 00 39 00 00 55 c4 00 00 5e 64 00 03 05 13 15 17 19 5d 5f 00 00 00 00 00 00 00 00 00 00 00 00 00 00 00 00 00 00 00 00 5f 5d 1a 18 16 14 06 04 00 64 5e 00 00 00 00 00 00 00 c0 03 00 00 3c 00 00 00 00 00 00 00 00 00 00 00 00 00 57 57 00 00 57 55 55 ff ff ff ff ff 55 55 d5 39 00 00 06 c5 08 00 00 00 00 39 00 00 4d c6 00 00 00 00 01 22 04 22 01 00 61 00 00 00 01 00 61 00 01 05 01 0b 01 35 ff 8f 06 c5 02 c0 0f 00 00 00 00 00 00 00 00 00 00 00 00 00 00 00 00 00 00 00 00 00 00 20 20 00 00 00 c0 11 00 00 00 10 10 00 00 00 01 00 50 00 33 03 00 00 39 00 00 1f cb 02 d0 01 80 00 00 00 00 00 00 00 00 00 00 00 00 00 00 00 00 00 00 40 70 00 00 00 00 00 ff 39 00 00 19 ce 16 56 66 88 9b aa bb c0 c8 cd d2 d8 e1 e7 ec f0 f3 07 0f 00 00 00 04 8c 39 00 00 02 cf 00 39 00 00 15 d0 c1 46 81 66 09 90 00 cc f2 ff 11 46 06 7e 09 08 cc 1b f0 06 39 00 00 26 d1 ce d8 1b 33 33 17 07 bb 22 52 22 52 00 3b 77 07 3b 30 06 72 33 13 00 d7 0c 22 02 00 18 70 18 77 11 11 11 20 20 39 00 00 04 d2 00 00 00 39 00 00 65 d3 00 00 00 00 00 00 00 00 00 ff f7 ff ff f7 ff ff f7 ff ff f7 ff ff f7 ff ff f7 ff ff f7 ff ff f7 ff ff f7 ff ff f7 ff ff f7 ff ff f7 ff ff f7 ff ff f7 ff ff f7 ff ff f7 ff ff f7 ff ff f7 ff ff f7 ff ff f7 ff ff f7 ff ff f7 ff ff f7 ff ff f7 ff ff f7 ff ff f7 ff ff f7 ff ff f7 ff ff f7 ff ff f7 ff ff 39 00 00 18 d4 00 00 00 00 00 00 00 00 00 20 00 00 00 00 20 00 00 00 00 00 00 00 00 39 00 00 02 d6 00 39 00 00 2f d7 01 00 12 12 00 62 00 16 00 62 00 16 03 83 80 85 85 85 87 84 45 86 87 80 88 86 89 83 83 87 84 88 8a 0c 0b 0a 0a 0a 07 07 06 06 00 08 0a 0a 39 00 00 17 d8 40 99 26 ed 16 6c 16 6c 16 6c 00 14 00 14 00 14 01 0c 00 00 01 00 39 00 00 29 d9 00 02 7f 00 00 00 00 00 00 00 00 00 00 00 00 c0 00 00 00 00 00 00 00 00 00 00 00 00 00 00 00 00 00 00 00 00 00 00 00 00 39 00 00 05 dd 30 06 23 65 39 00 00 0f de 00 00 00 0f ff 00 00 00 00 10 00 00 00 00 39 00 00 05 e5 03 00 00 00 39 00 00 09 e6 00 00 00 00 00 0e 00 00 39 00 00 24 ea 02 07 07 04 80 10 01 00 00 00 00 03 23 00 07 00 ed 00 ed 00 ed 01 28 01 28 00 62 00 62 00 62 01 0f 01 00 39 00 00 09 eb 06 e0 6e 07 61 01 01 00 39 00 00 18 ec 02 d0 01 70 73 10 01 00 00 00 00 02 2a 00 00 00 00 00 00 00 00 00 00 39 00 00 22 ed 01 02 00 00 00 00 00 00 67 a6 f0 00 00 00 00 00 00 00 00 00 00 00 00 f0 01 00 00 00 00 00 41 10 01 39 00 00 65 ee 05 00 05 00 c0 0b 00 00 03 00 00 03 00 00 03 00 c0 03 00 00 00 00 00 00 03 00 00 00 00 00 00 03 00 00 00 00 00 00 03 00 00 00 00 00 00 03 00 40 03 04 65 40 00 00 55 17 04 65 40 00 00 55 03 04 65 40 00 00 40 17 04 65 40 00 00 00 03 00 00 03 00 00 03 00 00 03 00 00 03 00 00 03 00 00 03 00 40 15 00 00 39 00 00 0c f9 20 3f e0 00 00 07 ff 00 00 07 ff 39 00 00 02 35 00 39 00 00 4d c7 00 00 00 72 00 b9 00 d4 00 ed 00 f8 01 08 01 0c 01 2c 00 fe 01 57 01 1d 01 63 01 22 01 92 01 9e 02 27 02 92 02 a0 00 00 00 72 00 b9 00 d4 00 ed 00 f8 01 08 01 0c 01 2c 00 fe 01 57 01 1d 01 63 01 22 01 92 01 9e 02 27 02 92 02 a0 39 00 00 02 53 24 39 00 00 02 55 00 39 00 00 02 b0 03 05 60 00 01 11 05 20 00 01 29];
					sprd,sleep-in-command = [05 14 00 01 28 05 78 00 01 10];
					sprd,sleep-out-command = [05 14 00 01 11 05 78 00 01 29];
					sprd,cabc-off-command = [39 00 00 02 55 03];
					sprd,cabc-ui-command = [39 00 00 02 55 01];
					sprd,cabc-still-command = [39 00 00 02 55 02];
					sprd,cabc-moving-command = [39 00 00 02 55 03];
					phandle = <0x10>;

					display-timings {
						native-mode = <&td4160_cw_old_timing0>;

						td4160_cw_old_timing0: timing0 {
							clock-frequency = <0xa037a00>;
							hactive = <0x2d0>;
							vactive = <0x640>;
							hback-porch = <0x68>;
							hfront-porch = <0xe0>;
							vback-porch = <0x20>;
							vfront-porch = <0x3fe>;
							hsync-len = <0x04>;
							vsync-len = <0x04>;
							phandle = <0x07>;
						};

						td4160_cw_old_timing1: timing1 {
							clock-frequency = <0xa037a00>;
							hactive = <0x2d0>;
							vactive = <0x640>;
							hback-porch = <0x64>;
							hfront-porch = <0xe0>;
							vback-porch = <0x20>;
							vfront-porch = <0x90>;
							hsync-len = <0x04>;
							vsync-len = <0x04>;
							phandle = <0x2f>;
						};
					};

					oled-backlight {
						default-brightness = <0x51a>;
						sprd,max-level = <0xfff>;
						brightness-levels = [39 00 00 03 51 00 00];
					};
				};

				lcd_td4160b_cw_boe_mipi_hd: lcd_td4160b_cw_boe_mipi_hd {
					sprd,dsi-work-mode = <0x01>;
					sprd,dsi-lane-number = <0x04>;
					sprd,dsi-color-format = "rgb888";
					sprd,phy-bit-clock = <0xdbba0>;
					sprd,phy-escape-clock = <0x4e20>;
					sprd,dpi-clk-div = <0x06>;
					sprd,video-lp-cmd-enable = <0x01>;
					sprd,hporch-lp-disable = <0x01>;
					sprd,width-mm = <0x47>;
					sprd,height-mm = <0x9c>;
					sprd,esd-check-enable = <0x01>;
					sprd,esd-check-mode = <0x00>;
					sprd,esd-check-period = <0x7d0>;
					sprd,esd-check-register = <0x0a>;
					sprd,esd-check-value = <0x9c>;
					sprd,reset-on-sequence = <0x01 0x05 0x00 0x05 0x01 0x1e>;
					sprd,reset-off-sequence = <0x00 0x05>;
					sprd,use-dcs-write;
					sprd,initial-command = [39 00 00 02 b0 04 39 00 00 02 d6 00 39 00 00 07 b6 30 6a 00 86 c3 03 39 00 00 05 b7 31 00 00 00 39 00 00 07 b8 02 50 09 00 04 40 39 00 00 07 b9 02 09 18 00 09 46 39 00 00 07 ba 06 90 00 00 00 00 39 00 00 04 bb 00 b4 a0 39 00 00 04 bc 00 b4 a0 39 00 00 04 bd 00 b4 a0 39 00 00 0e be 07 00 00 00 00 00 00 00 00 00 00 00 00 39 00 00 19 c0 00 60 24 06 40 00 16 06 98 00 70 00 00 00 00 00 00 00 00 00 00 00 00 00 39 00 00 28 c1 30 81 50 fa 01 00 00 10 00 00 00 00 40 0f 00 00 00 00 00 00 00 00 00 00 00 00 00 00 00 00 00 00 f0 07 08 07 d0 0a be 39 00 00 65 c2 01 20 50 14 04 10 0b 10 00 00 00 00 00 00 00 00 00 00 00 00 00 00 00 00 00 00 00 00 00 00 00 00 00 00 00 00 00 00 00 00 00 00 05 f0 54 08 08 05 05 c5 00 80 00 00 00 00 08 00 00 00 00 11 00 80 00 08 00 00 00 00 00 00 00 00 00 00 00 00 00 00 00 00 00 00 00 00 00 00 00 00 00 00 00 11 00 00 00 00 00 00 39 00 00 65 c3 01 00 55 01 01 86 68 00 00 00 20 01 01 00 55 01 01 86 68 00 00 00 20 02 01 00 55 01 01 86 68 00 00 00 20 00 01 00 55 01 01 86 68 00 00 00 20 00 00 00 00 08 00 00 00 00 00 00 00 00 00 00 00 00 00 00 00 00 00 00 00 00 00 00 00 00 00 00 00 00 00 00 00 00 00 00 00 00 00 00 00 00 00 00 00 00 00 00 00 00 39 00 00 55 c4 00 00 5e 64 00 03 05 13 15 17 19 5d 5f 00 00 00 00 00 00 00 00 00 00 00 00 00 00 00 00 00 00 00 00 5f 5d 1a 18 16 14 06 04 00 64 5e 00 00 00 00 00 00 00 c0 03 00 00 3c 00 00 00 00 00 00 00 00 00 00 00 00 00 57 57 00 00 57 55 55 ff ff ff ff ff 55 55 d5 39 00 00 06 c5 08 00 00 00 00 39 00 00 4d c6 00 00 00 00 01 22 04 22 01 00 61 00 00 00 01 00 61 00 01 05 01 0b 01 35 ff 8f 06 c5 02 c0 0f 00 00 00 00 00 00 00 00 00 00 00 00 00 00 00 00 00 00 00 00 00 00 20 20 00 00 00 c0 11 00 00 00 10 10 00 00 00 01 00 50 00 33 03 00 00 39 00 00 1f cb 02 d0 01 80 00 00 00 00 00 00 00 00 00 00 00 00 00 00 00 00 00 00 40 70 00 00 00 00 00 ff 39 00 00 19 ce 16 56 66 88 9b aa bb c0 c8 cd d2 d8 e1 e7 ec f0 f3 07 0f 00 00 00 04 8c 39 00 00 02 cf 00 39 00 00 15 d0 c1 46 81 66 09 90 00 cc f2 ff 11 46 06 7e 09 08 cc 1b f0 06 39 00 00 26 d1 ce d8 1b 33 33 17 07 bb 22 52 22 52 00 3b 77 07 3b 30 06 72 33 13 00 d7 0c 22 02 00 18 70 18 77 11 11 11 20 20 39 00 00 04 d2 00 00 00 39 00 00 65 d3 00 00 00 00 00 00 00 00 00 ff f7 ff ff f7 ff ff f7 ff ff f7 ff ff f7 ff ff f7 ff ff f7 ff ff f7 ff ff f7 ff ff f7 ff ff f7 ff ff f7 ff ff f7 ff ff f7 ff ff f7 ff ff f7 ff ff f7 ff ff f7 ff ff f7 ff ff f7 ff ff f7 ff ff f7 ff ff f7 ff ff f7 ff ff f7 ff ff f7 ff ff f7 ff ff f7 ff ff f7 ff ff f7 ff ff 39 00 00 18 d4 00 00 00 00 00 00 00 00 00 20 00 00 00 00 20 00 00 00 00 00 00 00 00 39 00 00 02 d6 00 39 00 00 2f d7 01 00 12 12 00 62 00 16 00 62 00 16 03 83 80 85 85 85 87 84 45 86 87 80 88 86 89 83 83 87 84 88 8a 0c 0b 0a 0a 0a 07 07 06 06 00 08 0a 0a 39 00 00 17 d8 40 99 26 ed 16 6c 16 6c 16 6c 00 14 00 14 00 14 01 0c 00 00 01 00 39 00 00 29 d9 00 02 7f 00 00 00 00 00 00 00 00 00 00 00 00 c0 00 00 00 00 00 00 00 00 00 00 00 00 00 00 00 00 00 00 00 00 00 00 00 00 39 00 00 05 dd 30 06 23 65 39 00 00 0f de 00 00 00 0f ff 00 00 00 00 10 00 00 00 00 39 00 00 05 e5 03 00 00 00 39 00 00 09 e6 00 00 00 00 00 0e 00 00 39 00 00 24 ea 02 07 07 04 80 10 01 00 00 00 00 03 23 00 07 00 ed 00 ed 00 ed 01 28 01 28 00 62 00 62 00 62 01 0f 01 00 39 00 00 09 eb 06 e0 6e 07 61 01 01 00 39 00 00 18 ec 02 d0 01 70 73 10 01 00 00 00 00 02 2a 00 00 00 00 00 00 00 00 00 00 39 00 00 22 ed 01 02 00 00 00 00 00 00 67 a6 f0 00 00 00 00 00 00 00 00 00 00 00 00 f0 01 00 00 00 00 00 41 10 01 39 00 00 65 ee 05 00 05 00 c0 0b 00 00 03 00 00 03 00 00 03 00 c0 03 00 00 00 00 00 00 03 00 00 00 00 00 00 03 00 00 00 00 00 00 03 00 00 00 00 00 00 03 00 40 03 04 65 40 00 00 55 17 04 65 40 00 00 55 03 04 65 40 00 00 40 17 04 65 40 00 00 00 03 00 00 03 00 00 03 00 00 03 00 00 03 00 00 03 00 00 03 00 40 15 00 00 39 00 00 0c f9 20 3f e0 00 00 07 ff 00 00 07 ff 39 00 00 02 35 00 39 00 00 4d c7 00 00 00 6d 00 af 00 cc 00 e1 00 ee 00 ff 01 00 01 1e 00 f1 01 4b 01 12 01 59 01 17 01 85 01 97 02 1e 02 94 02 a0 00 00 00 6d 00 af 00 cc 00 e1 00 ee 00 ff 01 00 01 1e 00 f1 01 4b 01 12 01 59 01 17 01 85 01 97 02 1e 02 94 02 a0 39 00 00 02 53 24 39 00 00 02 55 00 39 00 00 02 b0 03 05 60 00 01 11 05 20 00 01 29];
					sprd,sleep-in-command = [05 14 00 01 28 05 78 00 01 10];
					sprd,sleep-out-command = [05 14 00 01 11 05 78 00 01 29];
					sprd,cabc-off-command = [39 00 00 02 55 00];
					sprd,cabc-ui-command = [39 00 00 02 55 01];
					sprd,cabc-still-command = [39 00 00 02 55 02];
					sprd,cabc-moving-command = [39 00 00 02 55 03];
					phandle = <0x19>;

					display-timings {
						native-mode = <&td4160b_cw_boe_timing0>;

						td4160b_cw_boe_timing0: timing0 {
							clock-frequency = <0x8f0d180>;
							hactive = <0x2d0>;
							vactive = <0x640>;
							hback-porch = <0x68>;
							hfront-porch = <0x70>;
							vback-porch = <0x20>;
							vfront-porch = <0x3fc>;
							hsync-len = <0x04>;
							vsync-len = <0x04>;
							phandle = <0x08>;
						};

						td4160b_cw_boe_timing1: timing1 {
							clock-frequency = <0x8f0d180>;
							hactive = <0x2d0>;
							vactive = <0x640>;
							hback-porch = <0x68>;
							hfront-porch = <0x70>;
							vback-porch = <0x20>;
							vfront-porch = <0x87>;
							hsync-len = <0x04>;
							vsync-len = <0x04>;
							phandle = <0x30>;
						};
					};

					oled-backlight {
						default-brightness = <0x51a>;
						sprd,max-level = <0xfff>;
						brightness-levels = [39 00 00 03 51 00 00];
					};
				};

				lcd_hx83108a_lce_mipi_hd: lcd_hx83108a_lce_mipi_hd {
					sprd,dsi-work-mode = <0x01>;
					sprd,dsi-lane-number = <0x04>;
					sprd,dsi-color-format = "rgb888";
					sprd,phy-bit-clock = <0xf6180>;
					sprd,phy-escape-clock = <0x4e20>;
					sprd,dpi-clk-div = <0x06>;
					sprd,video-lp-cmd-enable = <0x01>;
					sprd,hporch-lp-disable = <0x01>;
					sprd,width-mm = <0x47>;
					sprd,height-mm = <0x9c>;
					sprd,esd-check-enable = <0x01>;
					sprd,esd-check-mode = <0x00>;
					sprd,esd-check-period = <0x7d0>;
					sprd,esd-check-register = <0x0a>;
					sprd,esd-check-value = <0x9d>;
					sprd,power-i2c-bus = <0x04>;
					sprd,power-i2c-addr = <0x3e>;
					sprd,power-i2c-reg = [00 01 03];
					sprd,power-i2c-val = [12 12 43];
					sprd,reset-on-sequence = <0x01 0x05 0x00 0x03 0x01 0x32 0x00 0x03 0x01 0x14>;
					sprd,reset-off-sequence = <0x01 0x05>;
					sprd,himax-sequence = <0x01>;
					sprd,reset-off-avdd-sequence = <0x00 0x14>;
					sprd,use-dcs-write;
					sprd,initial-command = [39 00 00 04 b9 83 10 8a 39 00 00 02 bd 00 39 00 00 13 b1 2c 32 32 2f 2f 20 61 39 18 18 0c 98 21 11 46 77 0c 04 39 00 00 11 b2 00 26 d0 40 00 e2 3a 20 62 11 00 00 00 14 22 df 39 00 00 0f b4 5a 5a 5a 5a 5a 5a 5a 49 5a 49 02 4e 01 02 39 00 00 05 ba 73 03 a8 96 39 00 00 03 bf fc 40 39 00 00 07 c0 62 62 11 22 b3 df 39 00 00 02 e9 cd 39 00 00 02 c0 85 39 00 00 02 e9 3f 39 00 00 02 e9 c5 39 00 00 09 c7 88 ca 08 14 02 04 04 00 39 00 00 02 e9 3f 39 00 00 02 e9 c6 39 00 00 04 c8 87 13 ff 39 00 00 02 e9 3f 39 00 00 02 cc 02 39 00 00 06 cb 13 08 e0 09 57 39 00 00 03 d1 27 02 39 00 00 05 d2 07 0f 07 0f 39 00 00 20 d3 c0 00 0c 0c 00 00 5b 5b 66 6b da da da da 32 10 d6 00 d6 32 10 da 00 da 32 10 0f 00 0f 00 00 39 00 00 2d d5 18 18 18 18 3e 3e 3e 3e 18 18 18 18 be be 18 18 18 18 18 18 be be 01 00 03 02 05 04 07 06 09 08 0b 0a 25 24 23 22 21 20 18 18 18 18 39 00 00 2d d6 18 18 18 18 3e 3e 3e 3e 18 18 18 18 be be 18 18 18 18 18 18 be be 01 00 03 02 05 04 07 06 09 08 0b 0a 25 24 23 22 21 20 18 18 18 18 39 00 00 25 d8 aa ae ae aa aa a0 aa ae ae aa aa a0 00 00 00 00 00 00 00 00 00 00 00 00 00 00 00 00 00 00 00 00 00 00 00 00 39 00 00 14 e7 d3 14 14 01 0f 84 00 3c 3c 32 32 00 00 00 00 e9 10 01 02 39 00 00 02 e9 dd 39 00 00 02 e7 32 39 00 00 02 e9 3f 39 00 00 02 e9 e0 39 00 00 02 e7 08 39 00 00 02 e9 3f 39 00 00 2f e0 00 02 0b 10 17 23 38 40 47 43 5e 66 6e 80 80 8a 94 a7 a5 51 59 64 73 00 02 0b 10 17 23 38 40 47 43 5e 66 6e 80 80 8a 94 a7 a5 51 59 64 73 39 00 00 02 bd 01 39 00 00 03 b1 01 1b 39 00 00 02 bf 0e 39 00 00 02 e9 c6 39 00 00 03 d2 d4 ec 39 00 00 02 e9 3f 39 00 00 02 e9 c8 39 00 00 02 d3 81 39 00 00 02 e9 3f 39 00 00 05 cb 00 34 02 01 39 00 00 25 d8 aa aa aa aa aa a0 aa aa aa aa aa a0 00 00 00 00 00 00 00 00 00 00 00 00 00 00 00 00 00 00 00 00 00 00 00 00 39 00 00 0e e7 01 00 20 01 00 00 2d 02 33 06 1b 00 00 39 00 00 02 bd 02 39 00 00 0d d8 ff ff ff ff ff f0 ff ff ff ff ff f0 39 00 00 02 e9 e0 39 00 00 02 e7 d1 39 00 00 02 e9 3f 39 00 00 02 bd 03 39 00 00 19 d8 aa ae ae aa aa a0 aa ae ae aa aa a0 aa ae ae aa aa a0 aa ae ae aa aa a0 39 00 00 02 bd 00 39 00 00 02 35 00 05 7a 00 01 11 39 00 00 02 e9 ff 39 00 00 02 bf 02 39 00 00 02 e9 3f 39 00 00 06 c9 00 1e 07 18 01 39 00 00 04 b9 00 00 00 39 00 00 02 53 24 05 01 00 01 29];
					sprd,sleep-in-command = [05 14 00 01 28 05 78 00 01 10];
					sprd,sleep-in-command-gesture-off = [05 14 00 01 28 05 78 00 01 10 39 00 00 04 b9 83 10 8a 15 00 00 02 bd 00 15 14 00 02 b1 2d];
					sprd,sleep-out-command = [05 14 00 01 11 05 78 00 01 29];
					sprd,cabc-off-command = [23 00 00 02 55 00];
					sprd,cabc-ui-command = [23 00 00 02 55 01];
					sprd,cabc-still-command = [23 00 00 02 55 02];
					sprd,cabc-moving-command = [23 00 00 02 55 03];
					phandle = <0x13>;

					display-timings {
						native-mode = <&hx83108a_lce_timing0>;

						hx83108a_lce_timing0: timing0 {
							clock-frequency = <0xa037a00>;
							hactive = <0x2d0>;
							vactive = <0x640>;
							hback-porch = <0x78>;
							hfront-porch = <0x78>;
							vback-porch = <0xdc>;
							vfront-porch = <0x3ec>;
							hsync-len = <0x1c>;
							vsync-len = <0x08>;
							phandle = <0x09>;
						};

						hx83108a_lce_timing1: timing1 {
							clock-frequency = <0xa037a00>;
							hactive = <0x2d0>;
							vactive = <0x640>;
							hback-porch = <0x78>;
							hfront-porch = <0x78>;
							vback-porch = <0xdc>;
							vfront-porch = <0x3c>;
							hsync-len = <0x1c>;
							vsync-len = <0x08>;
							phandle = <0x31>;
						};
					};

					oled-backlight {
						default-brightness = <0x51a>;
						sprd,max-level = <0xfff>;
						brightness-levels = [39 00 00 03 51 00 00];
					};
				};

				lcd_hx83108a_boe_mipi_hd: lcd_hx83108a_boe_mipi_hd {
					sprd,dsi-work-mode = <0x01>;
					sprd,dsi-lane-number = <0x04>;
					sprd,dsi-color-format = "rgb888";
					sprd,phy-bit-clock = <0xf6180>;
					sprd,phy-escape-clock = <0x4e20>;
					sprd,dpi-clk-div = <0x06>;
					sprd,video-lp-cmd-enable = <0x01>;
					sprd,hporch-lp-disable = <0x01>;
					sprd,width-mm = <0x47>;
					sprd,height-mm = <0x9c>;
					sprd,esd-check-enable = <0x01>;
					sprd,esd-check-mode = <0x00>;
					sprd,esd-check-period = <0x7d0>;
					sprd,esd-check-register = <0x0a>;
					sprd,esd-check-value = <0x9d>;
					sprd,fixed-brightness = <0x01>;
					sprd,power-i2c-bus = <0x04>;
					sprd,power-i2c-addr = <0x3e>;
					sprd,power-i2c-reg = [00 01 03];
					sprd,power-i2c-val = [14 14 43];
					sprd,reset-on-sequence = <0x01 0x05 0x00 0x03 0x01 0x32 0x00 0x03 0x01 0x14>;
					sprd,reset-off-sequence = <0x01 0x05>;
					sprd,himax-sequence = <0x01>;
					sprd,reset-off-avdd-sequence = <0x00 0x14>;
					sprd,himax-vsn-recovery = <0x01>;
					sprd,video-lp-en-mode = <0x02>;
					sprd,use-dcs-write;
					sprd,initial-command = [39 00 00 04 b9 83 10 8a 39 00 00 02 bd 00 39 00 00 12 b1 2c 37 37 35 35 22 43 57 18 18 0c 98 21 11 46 34 ff 39 00 00 11 b2 00 26 d0 40 00 e2 3a 20 5e 11 00 00 00 55 22 df 39 00 00 0f b4 14 14 14 14 14 14 14 50 14 50 02 52 01 02 39 00 00 05 ba 73 03 a8 96 39 00 00 03 bf fc 40 39 00 00 07 c0 62 62 11 22 b3 cf 39 00 00 02 e9 c5 39 00 00 09 c7 88 ca 08 14 02 04 04 00 39 00 00 02 e9 3f 39 00 00 02 e9 c6 39 00 00 04 c8 87 13 ff 39 00 00 02 e9 3f 39 00 00 02 cc 02 39 00 00 06 cb 13 08 e0 09 57 39 00 00 03 d1 27 02 39 00 00 05 d2 07 0f 07 0f 39 00 00 20 d3 c0 00 08 08 00 00 37 37 44 43 dd dd dd dd 32 10 d9 00 d9 32 10 08 00 08 32 10 08 00 08 00 00 39 00 00 2d d5 18 18 18 18 be be 18 18 20 21 22 23 04 05 06 07 00 01 02 03 3e 3e 3e 3e 18 18 18 18 18 18 18 18 18 18 18 18 18 18 18 18 18 18 18 18 39 00 00 2d d6 18 18 3e 3e be be 18 18 23 22 21 20 03 02 01 00 07 06 05 04 18 18 3e 3e 18 18 18 18 18 18 18 18 18 18 18 18 18 18 18 18 18 18 18 18 39 00 00 25 d8 2e aa ab 00 00 00 2e aa ab 00 00 00 00 00 00 00 00 00 00 00 00 00 00 00 00 00 00 00 00 00 00 00 00 00 00 00 39 00 00 14 e7 d2 14 14 01 0f 84 00 3c 3c 32 32 00 00 00 00 e9 10 01 02 39 00 00 02 e9 dd 39 00 00 02 e7 32 39 00 00 02 e9 3f 39 00 00 02 e9 e0 39 00 00 02 e7 08 39 00 00 02 e9 3f 39 00 00 2f e0 0d 09 10 14 1a 29 3e 43 4a 46 61 68 70 81 80 8a 93 a6 a6 52 5a 65 73 00 09 10 14 1a 29 3e 43 4a 46 61 68 70 81 80 8a 93 a6 a6 52 5a 65 73 39 00 00 02 bd 01 39 00 00 03 b1 01 1b 39 00 00 02 bf 0e 39 00 00 02 e9 c6 39 00 00 03 d2 d4 ec 39 00 00 02 e9 3f 39 00 00 02 e9 c8 39 00 00 02 d3 81 39 00 00 02 e9 3f 39 00 00 05 cb 00 34 02 01 39 00 00 25 d8 ff ff ff 00 00 00 ff ff ff 00 00 00 00 00 00 00 00 00 00 00 00 00 00 00 00 00 00 00 00 00 00 00 00 00 00 00 39 00 00 0e e7 01 00 20 01 00 00 29 02 33 04 1b 00 00 39 00 00 02 bd 02 39 00 00 0d d8 ff ff ff ff ff f0 ff ff ff ff ff f0 39 00 00 02 e9 e0 39 00 00 02 e7 d1 39 00 00 02 e9 3f 39 00 00 02 bd 03 39 00 00 19 d8 ae aa aa aa aa a0 ae aa aa aa aa a0 ae aa aa aa aa a0 ae aa aa aa aa a0 39 00 00 25 e4 13 3c 46 51 84 85 86 87 e5 ff ff 03 65 7f a3 ad b7 c1 c6 7a 7c aa ea 03 65 7f a3 ad b7 c1 c6 7a 7c aa ea 03 39 00 00 02 bd 01 39 00 00 28 e4 e1 e1 e1 e1 e1 e1 e1 e1 c5 b0 9e 8e 7f 73 67 5b 4f 45 39 34 2b 25 22 1d 17 13 0e 0a 08 05 01 54 55 55 55 55 55 55 55 39 00 00 02 bd 00 39 00 00 02 35 00 05 7a 00 01 11 39 00 00 02 e9 ff 39 00 00 02 bf 02 39 00 00 02 e9 3f 39 00 00 06 c9 00 1e 07 18 01 39 00 00 04 b9 00 00 00 39 00 00 02 53 24 05 01 00 01 29];
					sprd,sleep-in-command = [05 14 00 01 28 05 78 00 01 10];
					sprd,sleep-in-command-gesture-off = [05 14 00 01 28 05 78 00 01 10 39 00 00 04 b9 83 10 8a 15 00 00 02 bd 00 15 14 00 02 b1 2d];
					sprd,sleep-out-command = [05 64 00 01 11 05 14 00 01 29];
					sprd,cabc-off-command = [23 00 00 02 55 00];
					sprd,cabc-ui-command = [23 00 00 02 55 01];
					sprd,cabc-still-command = [23 00 00 02 55 02];
					sprd,cabc-moving-command = [23 00 00 02 55 03];
					phandle = <0x14>;

					display-timings {
						native-mode = <&hx83108a_boe_timing0>;

						hx83108a_boe_timing0: timing0 {
							clock-frequency = <0xa037a00>;
							hactive = <0x2d0>;
							vactive = <0x640>;
							hback-porch = <0x78>;
							hfront-porch = <0x78>;
							vback-porch = <0xdc>;
							vfront-porch = <0x3ec>;
							hsync-len = <0x1c>;
							vsync-len = <0x08>;
							phandle = <0x0a>;
						};

						hx83108a_boe_timing1: timing1 {
							clock-frequency = <0xa037a00>;
							hactive = <0x2d0>;
							vactive = <0x640>;
							hback-porch = <0x78>;
							hfront-porch = <0x78>;
							vback-porch = <0xdc>;
							vfront-porch = <0x3c>;
							hsync-len = <0x1c>;
							vsync-len = <0x08>;
							phandle = <0x32>;
						};
					};

					oled-backlight {
						default-brightness = <0x51a>;
						sprd,max-level = <0xfff>;
						brightness-levels = [39 00 00 03 51 00 00];
					};
				};

				lcd_ft8057_ld_mipi_hd: lcd_ft8057_ld_mipi_hd {
					sprd,dsi-work-mode = <0x01>;
					sprd,dsi-lane-number = <0x04>;
					sprd,dsi-color-format = "rgb888";
					sprd,phy-bit-clock = <0x10dc68>;
					sprd,phy-escape-clock = <0x4e20>;
					sprd,width-mm = <0x47>;
					sprd,height-mm = <0x9c>;
					sprd,esd-check-enable = <0x00>;
					sprd,esd-check-mode = <0x01>;
					sprd,esd-check-period = <0x7d0>;
					sprd,reset-on-sequence = <0x01 0x05 0x00 0x05 0x01 0x1e>;
					sprd,reset-off-sequence = <0x00 0x05>;
					sprd,initial-command = [29 00 00 02 00 00 29 00 00 04 ff 80 57 01 29 00 00 02 00 80 29 00 00 03 ff 80 57 29 00 00 02 00 86 29 00 00 02 a4 b6 29 00 00 02 00 a3 29 00 00 02 a5 04 29 00 00 02 00 a5 29 00 00 02 b0 1d 29 00 00 02 00 a3 29 00 00 05 b3 06 40 00 18 29 00 00 02 00 86 29 00 00 02 b7 80 29 00 00 02 00 70 29 00 00 07 c0 00 9f 01 14 00 1c 29 00 00 02 00 ca 29 00 00 03 c0 90 00 29 00 00 02 00 a1 29 00 00 07 c1 cc 3c 00 3b 00 ec 29 00 00 02 00 68 29 00 00 25 c2 8a 09 68 b6 89 09 68 b6 86 09 68 b6 85 09 68 b6 06 04 68 b6 07 04 68 b6 08 04 68 b6 09 04 68 b6 0d 09 68 b6 29 00 00 02 00 8c 29 00 00 59 c2 82 02 03 68 b6 81 03 03 68 b6 80 04 03 68 b6 01 05 03 68 b6 02 06 03 68 b6 03 07 03 68 b6 04 08 03 68 b6 05 09 03 68 b6 06 86 03 68 b6 07 85 03 68 b6 08 84 03 68 b6 09 83 03 68 b6 0a 82 03 68 b6 0b 81 03 68 b6 0c 00 03 68 b6 0d 01 03 68 b6 ff ff ff ff ff ff ff ff 29 00 00 02 00 e4 29 00 00 05 c2 0e 09 68 b6 29 00 00 02 00 90 29 00 00 02 c3 00 29 00 00 02 00 85 29 00 00 15 c4 80 00 00 00 00 00 00 00 00 00 00 88 02 00 00 ff 80 cc 00 08 29 00 00 02 00 82 29 00 00 03 c5 55 07 29 00 00 02 00 90 29 00 00 11 c5 84 03 01 6b 15 04 41 6b 25 01 41 51 41 25 55 56 29 00 00 02 00 b0 29 00 00 11 c5 00 0a 0d 00 0a 02 57 57 37 37 f0 f0 00 00 00 00 29 00 00 02 00 b0 29 00 00 07 ca 00 00 0c 00 00 06 29 00 00 02 00 80 29 00 00 45 cb c1 c1 c1 c1 c1 c1 c1 c1 c1 c1 c1 c1 c1 c1 c1 c1 00 00 00 00 00 00 00 00 00 00 00 00 00 00 00 00 00 00 00 00 00 00 00 00 00 00 00 00 00 00 00 00 00 00 00 00 00 00 00 00 00 00 00 00 00 00 00 00 00 00 00 00 29 00 00 02 00 d2 29 00 00 1f cb 83 00 83 83 00 83 83 00 83 83 00 00 00 00 83 83 00 83 83 00 83 83 00 83 83 00 83 c1 00 00 29 00 00 02 00 fa 29 00 00 03 cb 83 00 29 00 00 02 00 80 29 00 00 19 cc 00 16 18 00 00 00 00 00 1f 1e 26 1a 14 12 10 0e 0c 0a 08 06 04 02 00 00 29 00 00 02 00 80 29 00 00 19 cd 00 17 19 00 00 00 00 00 1f 1e 26 1b 15 13 11 0f 0d 0b 09 07 05 03 00 00 29 00 00 02 00 80 29 00 00 02 ce 00 29 00 00 02 00 d0 29 00 00 1d ce 01 00 1e 01 01 00 f1 01 00 00 0f ff 00 00 0f 00 00 08 03 39 04 4c 03 39 00 f1 00 f1 29 00 00 02 00 99 29 00 00 02 cf 56 29 00 00 02 00 00 29 00 00 03 d8 2b 2b 29 00 00 02 00 00 29 00 00 19 e1 2d 31 3c 48 50 58 65 71 6f 7a 7a 8b 7b 6a 6d 61 5a 4f 3f 35 2d 1c 10 0f 29 00 00 02 00 00 29 00 00 19 e2 2d 31 3c 48 50 58 65 71 6f 7a 7a 8b 7b 6a 6d 61 5a 4f 3f 35 2d 1c 10 0f 29 00 00 02 00 91 29 00 00 05 e9 ff ff ff 00 29 00 00 02 00 83 29 00 00 15 f5 11 19 19 0d 46 0c 0f c0 00 00 00 00 00 0a ac 4b 01 11 49 0d 29 00 00 02 00 b1 29 00 00 13 f5 1b 16 16 16 c8 18 1d c1 d9 c1 00 00 00 00 00 00 00 42 29 00 00 02 00 00 29 00 00 04 ff 00 00 00 29 00 00 02 00 80 29 00 00 03 ff 00 00 29 00 00 03 51 ff 0f 29 00 00 02 53 2c 29 00 00 02 55 00 05 78 00 01 11 05 00 00 01 29 29 1e 00 02 35 00];
					sprd,sleep-in-command = [05 14 00 01 28 05 78 00 01 10];
					sprd,sleep-out-command = [05 14 00 01 11 05 78 00 01 29];
					sprd,cabc-off-command = [23 00 00 02 55 00];
					sprd,cabc-ui-command = [23 00 00 02 55 01];
					sprd,cabc-still-command = [23 00 00 02 55 02];
					sprd,cabc-moving-command = [23 00 00 02 55 03];
					phandle = <0x15>;

					display-timings {
						native-mode = <&ft8057_ld_timing0>;

						ft8057_ld_timing0: timing0 {
							clock-frequency = <0x927c000>;
							hactive = <0x2d0>;
							vactive = <0x640>;
							hback-porch = <0x26>;
							hfront-porch = <0x80>;
							vback-porch = <0xf0>;
							vfront-porch = <0x3f3>;
							hsync-len = <0x08>;
							vsync-len = <0x08>;
							phandle = <0x0b>;
						};

						ft8057_ld_timing1: timing1 {
							clock-frequency = <0x927c000>;
							hactive = <0x2d0>;
							vactive = <0x640>;
							hback-porch = <0x26>;
							hfront-porch = <0x80>;
							vback-porch = <0xf0>;
							vfront-porch = <0x39>;
							hsync-len = <0x08>;
							vsync-len = <0x08>;
							phandle = <0x33>;
						};
					};

					oled-backlight {
						default-brightness = <0x51a>;
						sprd,max-level = <0xfff>;
						brightness-levels = [39 00 00 03 51 00 ff];
					};
				};

				lcd_icnl9916c_hjc_cd_mipi_hd: lcd_icnl9916c_hjc_cd_mipi_hd {
					sprd,dsi-work-mode = <0x01>;
					sprd,dsi-lane-number = <0x04>;
					sprd,dsi-color-format = "rgb888";
					sprd,phy-bit-clock = <0xf6180>;
					sprd,phy-escape-clock = <0x4e20>;
					sprd,dpi-clk-div = <0x06>;
					sprd,video-lp-cmd-enable = <0x01>;
					sprd,hporch-lp-disable = <0x01>;
					sprd,width-mm = <0x47>;
					sprd,height-mm = <0x9c>;
					sprd,esd-check-enable = <0x01>;
					sprd,esd-check-mode = <0x01>;
					sprd,esd-check-period = <0x7d0>;
					sprd,power-i2c-bus = <0x04>;
					sprd,power-i2c-addr = <0x3e>;
					sprd,power-i2c-reg = [00 01 03];
					sprd,power-i2c-val = [0f 0f 43];
					sprd,reset-on-sequence = <0x01 0x0f 0x00 0x05 0x01 0x1e>;
					sprd,reset-off-sequence = <0x01 0x05>;
					sprd,video-lp-en-mode = <0x02>;
					sprd,use-dcs-write;
					sprd,initial-command = [39 00 00 04 f0 99 16 0c 39 00 00 15 c1 00 f8 20 44 04 b0 48 04 40 06 22 70 35 30 07 11 84 4c 00 93 39 00 00 07 c3 06 00 ff 00 ff 5c 39 00 00 0d c4 04 31 b8 40 00 bc 00 00 00 00 00 f0 39 00 00 18 c5 03 21 96 c8 3e 00 04 01 14 04 19 0b c6 03 64 ff 01 04 18 22 45 14 38 39 00 00 0e c6 89 24 17 2b 2b 28 3f 03 16 a5 00 00 00 39 00 00 1e b2 03 02 97 98 99 99 8b 01 49 78 7e 78 7e 78 7e 78 7e 78 7e 78 7e 00 00 00 55 55 00 00 00 39 00 00 1a b3 f3 01 02 09 81 78 12 03 73 08 80 00 73 78 73 f3 01 01 01 01 00 00 00 00 00 39 00 00 21 b5 00 04 06 00 00 00 00 00 00 c1 00 2a 1a 18 16 14 12 10 0e 0c 0a 28 60 ff fc 00 00 00 00 00 00 00 39 00 00 21 b6 00 05 07 00 00 00 00 00 00 c1 00 2b 1b 19 17 15 13 11 0f 0d 0b 29 60 ff fc 00 00 00 00 00 00 00 39 00 00 17 b7 0a 0a 0a 0a 0a 0a 0a 0a 0a 0a 0a 0a 0a 0a 0a 0a 0a 0a 0a 0a 0a 0a 39 00 00 14 bc 00 00 00 00 04 00 ff f0 0b 13 5c 5b 33 33 00 50 3c 4a 36 39 00 00 0a bf 0c 19 0c 19 00 11 04 18 50 39 00 00 15 c0 40 93 ff ff ff 3f ff 00 ff 00 cc b1 23 45 67 89 ad ff ff f0 39 00 00 21 c7 76 54 32 22 34 56 77 77 30 76 54 32 22 34 56 77 77 30 31 00 01 ff ff 40 6e 6e 40 00 00 00 00 00 39 00 00 21 80 ff f8 ee e6 e0 da d6 d2 ce c2 b9 b2 ab a5 9f 94 8b 81 77 76 6d 63 59 4e 40 31 27 1a 17 12 0e 0c 39 00 00 21 81 ff f8 ee e6 e0 da d6 d2 ce c2 b9 b2 ab a5 9f 94 8b 81 77 76 6d 63 59 4e 40 31 27 1a 17 12 0e 0c 39 00 00 21 82 ff f8 ee e6 e0 da d6 d2 ce c2 b9 b2 ab a5 9f 94 8b 81 77 76 6d 63 59 4e 40 31 27 1a 17 12 0e 0c 39 00 00 1a 83 01 08 05 00 00 08 05 00 00 08 05 00 00 0a 06 02 00 0a 06 02 00 0a 06 02 00 39 00 00 1c 84 16 75 bf c3 07 78 3f 2c cc 16 75 bf c3 07 78 3f 2c cc 16 75 bf c3 07 78 3f 2c cc 15 00 00 02 c2 00 39 00 00 1f ca 25 40 00 19 46 94 41 8f 44 44 4a 54 40 40 50 5a 40 40 33 00 01 01 0f 0b 02 02 05 00 00 04 39 00 00 21 e0 0c 00 b0 10 00 07 b7 29 00 21 02 00 00 00 00 24 12 08 11 48 47 00 00 ff 00 00 00 00 00 00 00 00 39 00 00 05 bd a1 0a 52 a6 39 00 00 03 35 00 00 39 00 00 03 51 00 00 39 00 00 03 53 24 00 39 00 00 03 55 00 00 39 78 00 03 11 00 00 39 14 00 03 29 00 00 39 02 00 03 6d 02 00 39 02 00 05 bd a1 0a 52 ae 39 05 00 04 f0 00 00 00];
					sprd,sleep-in-command = [39 00 00 03 6d 25 00 39 14 00 03 28 00 00 39 78 00 03 10 00 00];
					sprd,sleep-out-command = [05 14 00 01 11 05 78 00 01 29];
					sprd,cabc-off-command = [39 00 00 03 55 00 00];
					sprd,cabc-ui-command = <0x39000004 0xf099160c 0x39000003 0x55010039 0x20e1 0xf1f2f3f 0x4f5f6f7f 0x90a0b0c0 0xd0e0eaf6 0xf6f6f6f6 0xf2f7f7f5 0xf6f6f3f4 0xf6f6ff39 0x21e2 0x32f8396b 0x396b396b 0x3b803b80 0x396b396f 0x396b396b 0x396b3851 0x396b396b 0x396b3e70 0x39000004 0xf0000000>;
					sprd,cabc-still-command = <0x39000004 0xf099160c 0x39000003 0x55020039 0x20e1 0xf1f2f3f 0x4f5f6f7f 0x90a0b0c0 0xd0e0f2d0 0xd0d0dde1 0xe0e1e1e0 0xe0e1e3e3 0xe3e3e339 0x21e2 0x26f82d00 0x2d002d00 0x2e802d00 0x2d002d00 0x2d002d00 0x2d003100 0x2e903200 0x36003970 0x39000004 0xf0000000>;
					sprd,cabc-moving-command = [39 00 00 03 55 00 00];
					phandle = <0x18>;

					display-timings {
						native-mode = <&icnl9916c_hjc_cd_timing0>;

						icnl9916c_hjc_cd_timing0: timing0 {
							clock-frequency = <0xa037a00>;
							hactive = <0x2d0>;
							vactive = <0x640>;
							hback-porch = <0xb0>;
							hfront-porch = <0x48>;
							vback-porch = <0xf8>;
							vfront-porch = <0x3fc>;
							hsync-len = <0x04>;
							vsync-len = <0x04>;
							phandle = <0x0c>;
						};

						icnl9916c_hjc_cd_timing1: timing1 {
							clock-frequency = <0xa037a00>;
							hactive = <0x2d0>;
							vactive = <0x640>;
							hback-porch = <0xb0>;
							hfront-porch = <0x48>;
							vback-porch = <0xf8>;
							vfront-porch = <0x44>;
							hsync-len = <0x04>;
							vsync-len = <0x04>;
							phandle = <0x34>;
						};
					};

					oled-backlight {
						default-brightness = <0x51a>;
						sprd,max-level = <0xfff>;
						brightness-levels = [39 00 00 03 51 00 00];
					};
				};

				lcd_icnl9916c_ld_hjc_mipi_hd: lcd_icnl9916c_ld_hjc_mipi_hd {
					sprd,dsi-work-mode = <0x01>;
					sprd,dsi-lane-number = <0x04>;
					sprd,dsi-color-format = "rgb888";
					sprd,phy-bit-clock = <0xf6180>;
					sprd,phy-escape-clock = <0x4e20>;
					sprd,dpi-clk-div = <0x06>;
					sprd,video-lp-cmd-enable = <0x01>;
					sprd,hporch-lp-disable = <0x01>;
					sprd,width-mm = <0x47>;
					sprd,height-mm = <0x9c>;
					sprd,esd-check-enable = <0x01>;
					sprd,esd-check-mode = <0x01>;
					sprd,esd-check-period = <0x7d0>;
					sprd,fixed-brightness = <0x01>;
					sprd,power-i2c-bus = <0x04>;
					sprd,power-i2c-addr = <0x3e>;
					sprd,power-i2c-reg = [00 01 03];
					sprd,power-i2c-val = [0f 0f 43];
					sprd,reset-on-sequence = <0x01 0x0f 0x00 0x05 0x01 0x1e>;
					sprd,reset-off-sequence = <0x01 0x05>;
					sprd,video-lp-en-mode = <0x02>;
					sprd,use-dcs-write;
					sprd,initial-command = [39 00 00 04 f0 99 16 0c 39 00 00 15 c1 00 f8 20 44 04 b0 48 04 40 06 22 70 35 30 07 11 84 4c 00 93 39 00 00 07 c3 06 00 ff 00 ff 5c 39 00 00 0d c4 04 31 b8 40 00 bc 00 00 00 00 00 f0 39 00 00 18 c5 03 21 96 c8 3e 00 04 01 14 04 19 0b c6 03 64 ff 01 04 18 22 45 14 38 39 00 00 0e c6 89 24 17 2b 2b 28 3f 03 16 a5 00 00 00 39 00 00 1e b2 03 02 97 98 99 99 8b 01 49 78 7e 78 7e 78 7e 78 7e 78 7e 78 7e 00 00 00 55 55 00 00 00 39 00 00 1a b3 f3 01 02 09 81 78 12 03 73 08 80 00 73 78 73 f3 01 01 01 01 00 00 00 00 00 39 00 00 21 b5 00 04 06 00 00 00 00 00 00 c1 00 2a 1a 18 16 14 12 10 0e 0c 0a 28 60 ff fc 00 00 00 00 00 00 00 39 00 00 21 b6 00 05 07 00 00 00 00 00 00 c1 00 2b 1b 19 17 15 13 11 0f 0d 0b 29 60 ff fc 00 00 00 00 00 00 00 39 00 00 17 b7 0a 0a 0a 0a 0a 0a 0a 0a 0a 0a 0a 0a 0a 0a 0a 0a 0a 0a 0a 0a 0a 0a 39 00 00 14 bc 00 00 00 00 04 00 ff f0 0b 13 5c 5b 33 33 00 50 3c 4a 36 39 00 00 0a bf 0c 19 0c 19 00 11 04 18 50 39 00 00 15 c0 40 93 ff ff ff 3f ff 00 ff 00 cc b1 23 45 67 89 ad ff ff f0 39 00 00 21 c7 76 54 32 22 34 56 77 77 30 76 54 32 22 34 56 77 77 30 31 00 01 ff ff 40 6e 6e 40 00 00 00 00 00 39 00 00 21 80 ff f8 ee e6 e0 da d6 d2 ce c2 b9 b2 ab a5 9f 94 8b 81 77 76 6d 63 59 4e 40 31 27 1a 17 12 0e 0c 39 00 00 21 81 ff f8 ee e6 e0 da d6 d2 ce c2 b9 b2 ab a5 9f 94 8b 81 77 76 6d 63 59 4e 40 31 27 1a 17 12 0e 0c 39 00 00 21 82 ff f8 ee e6 e0 da d6 d2 ce c2 b9 b2 ab a5 9f 94 8b 81 77 76 6d 63 59 4e 40 31 27 1a 17 12 0e 0c 39 00 00 1a 83 01 08 05 00 00 08 05 00 00 08 05 00 00 0a 06 02 00 0a 06 02 00 0a 06 02 00 39 00 00 1c 84 16 75 bf c3 07 78 3f 2c cc 16 75 bf c3 07 78 3f 2c cc 16 75 bf c3 07 78 3f 2c cc 15 00 00 02 c2 00 39 00 00 1f ca 25 40 00 19 46 94 41 8f 44 44 4a 54 40 40 50 5a 40 40 33 00 01 01 0f 0b 02 02 05 00 00 04 39 00 00 21 e0 0c 00 b0 10 00 07 b7 29 00 21 02 00 00 00 00 24 12 08 11 48 47 00 00 ff 00 00 00 00 00 00 00 00 39 00 00 05 bd a1 0a 52 a6 39 00 00 03 35 00 00 39 00 00 03 51 00 00 39 00 00 03 53 24 00 39 00 00 03 55 00 00 39 78 00 03 11 00 00 39 14 00 03 29 00 00 39 02 00 03 6d 02 00 39 02 00 05 bd a1 0a 52 ae 39 05 00 04 f0 00 00 00];
					sprd,sleep-in-command = [39 00 00 03 6d 25 00 39 14 00 03 28 00 00 39 78 00 03 10 00 00];
					sprd,sleep-out-command = [05 14 00 01 11 05 78 00 01 29];
					sprd,cabc-off-command = [39 00 00 03 55 00 00];
					sprd,cabc-ui-command = <0x39000004 0xf099160c 0x39000003 0x55010039 0x20e1 0xf1f2f3f 0x4f5f6f7f 0x90a0b0c0 0xd0e0eaf6 0xf6f6f6f6 0xf2f7f7f5 0xf6f6f3f4 0xf6f6ff39 0x21e2 0x32f8396b 0x396b396b 0x3b803b80 0x396b396f 0x396b396b 0x396b3851 0x396b396b 0x396b3e70 0x39000004 0xf0000000>;
					sprd,cabc-still-command = <0x39000004 0xf099160c 0x39000003 0x55020039 0x20e1 0xf1f2f3f 0x4f5f6f7f 0x90a0b0c0 0xd0e0f2d0 0xd0d0dde1 0xe0e1e1e0 0xe0e1e3e3 0xe3e3e339 0x21e2 0x26f82d00 0x2d002d00 0x2e802d00 0x2d002d00 0x2d002d00 0x2d003100 0x2e903200 0x36003970 0x39000004 0xf0000000>;
					sprd,cabc-moving-command = [39 00 00 03 55 00 00];
					phandle = <0x16>;

					display-timings {
						native-mode = <&icnl9916c_ld_hjc_timing0>;

						icnl9916c_ld_hjc_timing0: timing0 {
							clock-frequency = <0xa037a00>;
							hactive = <0x2d0>;
							vactive = <0x640>;
							hback-porch = <0xb0>;
							hfront-porch = <0x48>;
							vback-porch = <0xf8>;
							vfront-porch = <0x3fc>;
							hsync-len = <0x04>;
							vsync-len = <0x04>;
							phandle = <0x0d>;
						};

						icnl9916c_ld_hjc_timing1: timing1 {
							clock-frequency = <0xa037a00>;
							hactive = <0x2d0>;
							vactive = <0x640>;
							hback-porch = <0xb0>;
							hfront-porch = <0x48>;
							vback-porch = <0xf8>;
							vfront-porch = <0x44>;
							hsync-len = <0x04>;
							vsync-len = <0x04>;
							phandle = <0x35>;
						};
					};

					oled-backlight {
						default-brightness = <0x51a>;
						sprd,max-level = <0xfff>;
						brightness-levels = [39 00 00 03 51 00 00];
					};
				};

				lcd_icnl9916c_inx_mipi_hd: lcd_icnl9916c_inx_mipi_hd {
					sprd,dsi-work-mode = <0x01>;
					sprd,dsi-lane-number = <0x04>;
					sprd,dsi-color-format = "rgb888";
					sprd,phy-bit-clock = <0xf6180>;
					sprd,phy-escape-clock = <0x4e20>;
					sprd,dpi-clk-div = <0x06>;
					sprd,video-lp-cmd-enable = <0x01>;
					sprd,hporch-lp-disable = <0x01>;
					sprd,width-mm = <0x47>;
					sprd,height-mm = <0x9c>;
					sprd,esd-check-enable = <0x01>;
					sprd,esd-check-mode = <0x01>;
					sprd,esd-check-period = <0x7d0>;
					sprd,fixed-brightness = <0x01>;
					sprd,power-i2c-bus = <0x04>;
					sprd,power-i2c-addr = <0x3e>;
					sprd,power-i2c-reg = [00 01 03];
					sprd,power-i2c-val = [14 14 43];
					sprd,reset-on-sequence = <0x01 0x0f 0x00 0x05 0x01 0x1e>;
					sprd,reset-off-sequence = <0x01 0x05>;
					sprd,video-lp-en-mode = <0x02>;
					sprd,use-dcs-write;
					sprd,initial-command = [39 00 00 04 f0 99 16 0c 39 00 00 15 c0 40 93 ff ff ff 3f ff 00 ff 00 cc b1 23 45 67 89 ad ff ff f0 39 00 00 21 c1 00 f8 20 54 04 ac 48 04 40 06 22 70 30 30 07 11 84 4c 00 93 13 63 00 00 00 00 00 00 00 00 00 00 39 00 00 06 c2 11 05 01 10 80 39 00 00 09 c3 06 00 ff 00 ff 5c 10 01 39 00 00 0d c4 04 31 b8 40 00 bc 00 00 00 00 00 f0 39 00 00 18 c5 03 21 96 c8 3e 00 09 01 14 04 0f 18 c6 03 64 ff 01 04 18 22 45 14 38 39 00 00 0d c6 72 24 13 2b 2b 28 3f 02 16 96 00 01 15 00 00 02 ca 00 39 00 00 19 b2 70 11 09 10 96 36 0b 07 44 10 10 10 10 10 10 10 10 52 6e 52 6e 00 00 00 39 00 00 0c b3 b4 07 02 0f 81 65 00 00 64 08 00 39 00 00 16 b4 00 10 15 10 15 26 26 91 a2 33 44 00 26 00 55 3c 02 08 20 30 00 39 00 00 21 b5 00 00 32 32 00 00 33 00 00 00 33 0d 0f 11 13 15 17 09 07 05 00 00 ff ff fc 32 20 00 00 00 00 00 39 00 00 21 b6 00 00 32 32 00 00 33 00 00 00 33 0c 0e 10 12 14 16 08 06 04 00 00 ff ff fc 32 20 00 00 00 00 00 39 00 00 17 b7 5a 5a 5a 5a 5a 5a 5a 5a 5a 5a 5a 5a 5a 5a 5a 5a 5a 5a 5a 5a 5a 5a 39 00 00 09 bb 01 02 03 0a 04 13 14 00 39 00 00 14 bc 00 00 00 00 04 00 ff f0 0b 33 54 5b 33 33 00 5a 46 52 3e 39 00 00 1f ca 25 40 04 19 46 94 41 8f 22 33 52 64 3e 34 5a 6e 46 3c 11 00 01 01 08 01 06 00 05 00 00 04 39 00 00 0e bd a1 0a 52 ae 8f 04 c7 c1 06 03 2e 15 01 39 00 00 0a bf 0c 19 0c 19 00 11 04 18 50 39 00 00 1c c7 76 54 32 22 34 56 77 77 30 76 54 32 22 34 56 77 77 10 31 00 01 ff ff 00 82 91 40 39 00 00 21 80 ff fb f4 ed e8 e4 e0 dc d8 cd c4 bc b6 b0 a9 9e 94 8a 7e 7d 72 68 5d 50 40 2e 29 1a 16 13 0e 0b 39 00 00 21 81 ff fb f4 ed e8 e4 e0 dc d8 cd c4 bc b6 b0 a9 9e 94 8a 7e 7d 72 68 5d 50 40 2e 29 1a 16 13 0e 0b 39 00 00 21 82 ff fb f4 ed e8 e4 e0 dc d8 cd c4 bc b6 b0 a9 9e 94 8a 7e 7d 72 68 5d 50 40 2e 29 1a 16 13 0e 0b 39 00 00 1a 83 03 08 05 02 02 08 05 02 02 08 05 02 02 06 03 01 00 06 03 01 01 06 03 01 01 39 00 00 1c 84 11 d2 e2 59 2e 44 24 cd ee 11 d2 e2 59 2e 44 24 cd ee 11 d2 e2 59 2e 44 24 cd ee 39 00 00 21 85 fb f7 ef e8 e4 df db d7 d4 c8 bf b7 b0 a9 a2 97 8b 80 74 73 67 5d 52 44 37 2b 1b 10 0f 0d 0b 08 39 00 00 21 86 fb f7 ef e8 e4 df db d7 d4 c8 bf b7 b0 a9 a2 97 8b 80 74 73 67 5d 52 44 37 2b 1b 10 0f 0d 0b 08 39 00 00 21 87 fb f7 ef e8 e4 df db d7 d4 c8 bf b7 b0 a9 a2 97 8b 80 74 73 67 5d 52 44 37 2b 1b 10 0f 0d 0b 08 39 00 00 1c 8b 1f 7b 21 e8 55 d7 67 06 64 1f 7b 21 e8 55 d7 67 06 64 1f 7b 21 e8 55 d7 67 06 64 39 00 00 05 c8 46 00 88 98 39 00 00 21 e0 0c 00 b0 10 00 07 b7 29 00 21 02 00 00 00 00 24 12 08 11 48 47 00 00 ff 00 00 00 00 00 00 00 00 39 00 00 05 bd a1 0a 52 a6 39 00 00 03 35 00 00 39 00 00 03 51 00 00 39 00 00 03 53 24 00 39 00 00 03 55 00 00 39 78 00 03 11 00 00 39 0a 00 03 29 00 00 39 00 00 03 6d 02 00 39 00 00 05 bd a1 0a 52 ae 39 05 00 04 f0 00 00 00];
					sprd,sleep-in-command = [39 00 00 03 6d 25 00 39 14 00 03 28 00 00 39 78 00 03 10 00 00];
					sprd,sleep-out-command = [05 14 00 01 11 05 78 00 01 29];
					sprd,cabc-off-command = [39 00 00 03 55 00 00];
					sprd,cabc-ui-command = <0x39000004 0xf099160c 0x39000003 0x55010039 0x20e1 0xf1f2f3f 0x4f5f6f7f 0x90a0b0c0 0xd0e0eaf6 0xf6f6f6f6 0xf2f7f7f5 0xf6f6f3f4 0xf6f6ff39 0x21e2 0x32f8396b 0x396b396b 0x3b803b80 0x396b396f 0x396b396b 0x396b3851 0x396b396b 0x396b3e70 0x39000004 0xf0000000>;
					sprd,cabc-still-command = <0x39000004 0xf099160c 0x39000003 0x55020039 0x20e1 0xf1f2f3f 0x4f5f6f7f 0x9099b7c0 0xd0e0f2d0 0xd0d0dde1 0xdfe1e1e0 0xe0e3ebe3 0xe3e3e339 0x21e2 0x26f82d00 0x2d002d00 0x2e802d00 0x2d002d00 0x2d002d00 0x2dd02e80 0x2d003200 0x36003970 0x39000004 0xf0000000>;
					sprd,cabc-moving-command = [39 00 00 03 55 00 00];
					phandle = <0x17>;

					display-timings {
						native-mode = <&icnl9916c_inx_timing0>;

						icnl9916c_inx_timing0: timing0 {
							clock-frequency = <0xa037a00>;
							hactive = <0x2d0>;
							vactive = <0x640>;
							hback-porch = <0xb0>;
							hfront-porch = <0x48>;
							vback-porch = <0xf8>;
							vfront-porch = <0x3fc>;
							hsync-len = <0x04>;
							vsync-len = <0x04>;
							phandle = <0x0e>;
						};

						icnl9916c_inx_timing1: timing1 {
							clock-frequency = <0xa037a00>;
							hactive = <0x2d0>;
							vactive = <0x640>;
							hback-porch = <0xac>;
							hfront-porch = <0x48>;
							vback-porch = <0xf8>;
							vfront-porch = <0x54>;
							hsync-len = <0x04>;
							vsync-len = <0x04>;
							phandle = <0x36>;
						};
					};

					oled-backlight {
						default-brightness = <0x51a>;
						sprd,max-level = <0xfff>;
						brightness-levels = [39 00 00 03 51 00 00];
					};
				};

				lcd_ft8057p_ld_mipi_hd: lcd_ft8057p_ld_mipi_hd {
					sprd,dsi-work-mode = <0x01>;
					sprd,dsi-lane-number = <0x04>;
					sprd,dsi-color-format = "rgb888";
					sprd,phy-bit-clock = <0xf6180>;
					sprd,phy-escape-clock = <0x4e20>;
					sprd,dpi-clk-div = <0x06>;
					sprd,video-lp-cmd-enable = <0x01>;
					sprd,hporch-lp-disable = <0x01>;
					sprd,power-i2c-val = [12 12 43];
					sprd,width-mm = <0x47>;
					sprd,height-mm = <0x9c>;
					sprd,esd-check-enable = <0x01>;
					sprd,esd-check-mode = <0x01>;
					sprd,esd-check-period = <0x7d0>;
					sprd,ft8057-sequence = <0x01>;
					sprd,reset-on-sequence = <0x01 0x05 0x00 0x05 0x01 0x1e>;
					sprd,reset-off-sequence = <0x01 0x05>;
					sprd,use-high-bit-mode = <0x01>;
					sprd,video-lp-en-mode = <0x02>;
					sprd,initial-command = <0x29000002 0x2900 0x4ff80 0x57012900 0x20080 0x29000003 0xff805729 0x200 0x290000 0x52a0000 0x2cf2900 0x20000 0x29000005 0x2b000006 0x3f290000 0x200a329 0x5b3 0x6400018 0x29000002 0x932900 0x2c557 0x29000002 0x972900 0x2c557 0x29000002 0x9a2900 0x2c5cb 0x29000002 0x9c2900 0x2c5cb 0x29000002 0xb62900 0x3c543 0x43290000 0x200b829 0x3c5 0x41412900 0x20000 0x29000003 0xd8333329 0x200 0x82290000 0x2c55529 0x200 0x83290000 0x2c50729 0x200 0x96290000 0x2f51929 0x200 0x86290000 0x2f51929 0x200 0x94290000 0x2c51529 0x200 0x9b290000 0x2c55129 0x200 0xa3290000 0x2a50429 0x200 0x99290000 0x2cf5629 0x200 0x86290000 0x2b78029 0x200 0xa5290000 0x2b01d29 0x200 0x90290000 0x2ff0029 0x200 0x290000 0x11e10d1a 0x1c2c3640 0x5160616f 0x73897864 0x645a2900 0x20010 0x29000009 0xe1514638 0x2e261814 0xf290000 0x2000029 0x11e2 0xd1a1c2c 0x36405160 0x616f7389 0x7864645a 0x29000002 0x102900 0x9e251 0x46382e26 0x18140f29 0x200 0x80290000 0x7c000d2 0x3a0010 0x29000002 0x902900 0x7c000 0x9f003a00 0x10290000 0x200a029 0x7c0 0xd2003a 0x102900 0x200b0 0x29000006 0xc0011100 0x3a102900 0x200c1 0x29000009 0xc0013301 0xa00cd01 0x90290000 0x2007029 0x7c0 0x9f003a 0x102900 0x200a3 0x29000007 0xc1003300 0x3c000229 0x200 0xb7290000 0x3c10033 0x29000002 0x732900 0x3ce09 0x9290000 0x2008029 0x11ce 0x1810909 0x780096 0x780096 0x780096 0x29000002 0x902900 0x10ce00 0xa5168f00 0xa5800909 0x7d016 0x16272900 0x200a0 0x29000004 0xce200000 0x29000002 0xb02900 0x4ce87 0x2900 0x200d1 0x29000008 0xce000001 0x00 0x29000002 0xe12900 0xcce08 0x3c303c3 0x2b00000 0x2900 0x200f1 0x2900000a 0xce14141e 0x1450145 0x12b2900 0x200b0 0x29000005 0xcf00006d 0x71290000 0x200b529 0x5cf 0x3035b5f 0x29000002 0xc02900 0x5cf06 0x63b3f29 0x200 0xc5290000 0x5cf0607 0x494a2900 0x20060 0x29000009 0xcf00006d 0x7103035b 0x5f290000 0x2007029 0x9cf 0x696d 0x303575b 0x29000002 0xaa2900 0x5cf80 0x80100c29 0x200 0xd1290000 0xdc103aa 0x5220959 0x5870823 0xfac2900 0x200e1 0x29000003 0xc1052229 0x200 0xe2290000 0xdcf06de 0x6dd06dd 0x6dd06dd 0x6dd2900 0x20080 0x29000003 0xc1000029 0x200 0x90290000 0x2c10129 0x200 0xf5290000 0x2cf0129 0x200 0xf6290000 0x2cf5a29 0x200 0xf1290000 0x2cf5a29 0x200 0xf7290000 0x2cf1129 0x200 0x290000 0x31f5a5a 0x29000002 0xd12900 0x8ce00 0x15010100 0xfd012900 0x200e8 0x29000005 0xce00fd00 0xfd290000 0x2008029 0x11cc 0x26261c1c 0x26261d26 0x26260107 0x90b0d0f 0x29000002 0x902900 0x9cc11 0x23050300 0x29 0x200 0x80290000 0x11cd2626 0x1c1c2626 0x1d262626 0x106080a 0xc0e2900 0x20090 0x29000009 0xcd102204 0x2000000 0x290000 0x200a029 0x11cc 0x26262626 0x1c1c1d26 0x2626010c 0xa080610 0x29000002 0xb02900 0x9cc0e 0x22020400 0x29 0x200 0xa0290000 0x11cd2626 0x26261c1c 0x1d262626 0x10d0b09 0x7112900 0x200b0 0x29000009 0xcd0f2303 0x5000000 0x290000 0x2008029 0x11cb 0xc1c1c1c1 0xc1c1c1c1 0xc1c1c1c1 0xc1c1c1c1 0x29000002 0xed2900 0x2cbc1 0x29000002 0x902900 0x11cbff 0x00 0x00 0xff00 0x29 0x200 0xee290000 0x2cb0029 0x200 0x90290000 0x2c30029 0x200 0xa0290000 0x9cb0000 0xc000 0x3002900 0x200b0 0x29000005 0xcb555555 0x55290000 0x200c029 0x5cb 0x55555555 0x29000002 0xd22900 0xccb01 0x10100 0x1010001 0x1002900 0x200e0 0x2900000e 0xcb010100 0x1010001 0x1000101 0x12900 0x200fa 0x29000003 0xcb010029 0x200 0xef290000 0x2cb0029 0x200 0x68290000 0x5c28c03 0x2900 0x2006c 0x29000005 0xc28b0300 0x290000 0x2007029 0x5c2 0x8a030000 0x29000002 0x742900 0x5c289 0x3000029 0x200 0xea290000 0x9c21200 0xc140000 0x2900 0x2008c 0x29000006 0xc28a0515 0x7aab2900 0x20091 0x29000006 0xc2890615 0x7aab2900 0x20096 0x29000006 0xc2880715 0x7aab2900 0x2009b 0x29000006 0xc2870815 0x7aab2900 0x200a0 0x29000006 0xc2860915 0x7aab2900 0x200a5 0x29000006 0xc2850a15 0x7aab2900 0x200aa 0x29000006 0xc2840b15 0x7aab2900 0x200af 0x29000006 0xc2830c15 0x7aab2900 0x200b4 0x29000006 0xc2820d15 0x7aab2900 0x200b9 0x29000006 0xc2810e15 0x7aab2900 0x200be 0x29000006 0xc2800f15 0x7aab2900 0x200c3 0x29000006 0xc2011015 0x7aab2900 0x200dc 0x29000009 0xc2bbbbbb 0xbbbbbb00 0x290000 0x200e829 0x5c3 0x00 0x29000002 0xec2900 0x5c300 0x29 0x200 0xf9290000 0x2cb2029 0x200 0xfe290000 0x2cb0829 0x200 0xf8290000 0x4cd8833 0x87290000 0x200fc29 0x3cb 0x8402900 0x200fb 0x29000005 0xc38d138d 0x13290000 0x2009829 0x2c4 0x8290000 0x2009029 0x6e9 0x10ffffff 0x290000 0x2008529 0x2c4 0x80290000 0x2008129 0x2a4 0x73290000 0x2008629 0x2a4 0xb6290000 0x2009529 0x2c4 0x80290000 0x2009329 0x2c4 0x8f290000 0x2008029 0x2b3 0x17290000 0x200a529 0x2b0 0x1d290000 0x200ca29 0x3c0 0x90112900 0x200b7 0x29000002 0xf51d2900 0x20090 0x29000002 0xc3002900 0x200b1 0x29000002 0xf5112900 0x200b0 0x29000002 0xc5002900 0x200b3 0x29000002 0xc5002900 0x200b2 0x29000002 0xc50d2900 0x200b5 0x29000002 0xc5022900 0x200c2 0x29000002 0xf5422900 0x20080 0x29000002 0xce002900 0x200d0 0x29000002 0xce012900 0x200e0 0x29000002 0xce002900 0x200a1 0x29000002 0xc1cc2900 0x200a6 0x29000002 0xc1102900 0x20071 0x29000006 0xc0970165 0x222900 0x200ad 0x29000003 0xc1a0a029 0x200 0x84290000 0x2c56629 0x200 0x80290000 0x2a41629 0x200 0x8a290000 0x2c50629 0x200 0x94290000 0x2c51329 0x200 0x9b290000 0x2c53129 0x200 0xa8290000 0x2c10129 0x200 0xbc290000 0x2c00129 0x21c 0x3290000 0x200b029 0x7ca 0xc00 0x32900 0x200c5 0x29000005 0xcf060640 0x44290000 0x2008029 0xdca 0xd2d2c1b4 0xaaa19a93 0x8e898480 0x29000002 0x902900 0xacafe 0xff66e93c 0xc1e73c09 0x29000002 0xa02900 0x4ca06 0x6062900 0x20096 0x29000002 0xf5002900 0x20000 0x29000004 0xff000000 0x29000002 0x802900 0x3ff00 0x290000 0x3510000 0x29000002 0x532c2900 0x25500 0x29000002 0x3500055a 0x11105 0x1000129>;
					sprd,sleep-in-command = [05 14 00 01 28 05 78 00 01 10 29 00 00 02 00 00 29 03 00 05 f7 5a a5 95 27];
					sprd,sleep-out-command = [05 5a 00 01 11 05 01 00 01 29];
					sprd,cabc-off-command = [23 00 00 02 55 00];
					sprd,cabc-ui-command = [23 00 00 02 55 01];
					sprd,cabc-still-command = [23 00 00 02 55 02];
					sprd,cabc-moving-command = [23 00 00 02 55 03];
					phandle = <0x1a>;

					display-timings {
						native-mode = <&ft8057p_ld_timing0>;

						ft8057p_ld_timing0: timing0 {
							clock-frequency = <0xa037a00>;
							hactive = <0x2d0>;
							vactive = <0x640>;
							hback-porch = <0x20>;
							hfront-porch = <0xac>;
							vback-porch = <0x22>;
							vfront-porch = <0x550>;
							hsync-len = <0x08>;
							vsync-len = <0x0a>;
							phandle = <0x0f>;
						};

						ft8057p_ld_timing1: timing1 {
							clock-frequency = <0xa037a00>;
							hactive = <0x2d0>;
							vactive = <0x640>;
							hback-porch = <0x20>;
							hfront-porch = <0xac>;
							vback-porch = <0x22>;
							vfront-porch = <0x166>;
							hsync-len = <0x08>;
							vsync-len = <0x0a>;
							phandle = <0x37>;
						};
					};

					oled-backlight {
						default-brightness = <0x51a>;
						sprd,max-level = <0xfff>;
						brightness-levels = [39 00 00 03 51 00 ff];
					};
				};
			};

			wcn_btwf: cpwcn-btwf {
				compatible = "unisoc,integrate_marlin";
				sprd,name = "wcn_btwf";
				sprd,syscon-ap-apb = <&aon_apb_regs>;
				sprd,syscon-ap-pmu = <&pmu_apb_regs>;
				sprd,syscon-wcn-aon-apb = <&wcncp_aon_apb_regs>;
				sprd,syscon-wcn-aon-ahb = <&wcncp_aon_ahb_regs>;
				sprd,syscon-ap-pub-apb = <&pub_apb_regs>;
				sprd,syscon-wcn-btwf-ahb = <&wcncp_btwf_ahb_regs>;
				sprd,ctrl-probe-num = <0x01>;
				sprd,ctrl-reg = <0x9018 0x23a8 0x2818 0x23a8 0x90 0x98 0x0c 0x1410 0x4c 0x0c>;
				sprd,ctrl-mask = <0x3fff 0x2000000 0x80 0x1000000 0x40000000 0x100f 0x55 0x3000000 0xffffffff 0x55>;
				sprd,ctrl-value = <0x70 0x2000000 0x80 0x1000000 0x40000000 0x00 0x55 0x3000000 0x7fdc00 0x00>;
				sprd,ctrl-rw-offset = <0x1000 0x2000 0x2000 0x2000 0x00 0x00 0x00 0x1000 0x00 0x00>;
				sprd,ctrl-us-delay = <0x3e8 0x3e8 0x3e8 0x7d0 0x3e8 0x3e8 0x3e8 0x3e8 0x3e8 0x3e8>;
				sprd,ctrl-type = <0x02 0x01 0x01 0x01 0x0a 0x0a 0x09 0x07 0x09 0x09>;
				sprd,ctrl-shutdown-reg = <0x98>;
				sprd,ctrl-shutdown-mask = <0x1000>;
				sprd,ctrl-shutdown-value = <0x1000>;
				sprd,ctrl-shutdown-rw-offset = <0x00>;
				sprd,ctrl-shutdown-us-delay = <0x0a>;
				sprd,ctrl-shutdown-type = <0x0a>;
				reg = <0x00 0x87000000 0x00 0x200000 0x00 0x7c00a000 0x00 0x74>;
				sprd,debugbus-to-ddr-disable;
				sprd,file-name = "/dev/block/platform/soc/soc:ap-apb/201d0000.sdio/by-name/wcnmodem";
				sprd,file-name-ufs = "/dev/block/platform/soc/soc:ap-apb/20200000.ufs/by-name/wcnmodem";
				sprd,firmware-path = "/vendor/firmware/";
				sprd,file-length = <0x200000>;
				sprd,rstpad-setting = <0x01>;
				sprd,apcp-sync-addr = <0x7fdc00>;
				sprd,wcn-sipc-ver = <0x01>;
				vddwcn-supply = <&vddwcn>;
				dcxo1v8-supply = <&vddsim2>;
				vddwifipa-supply = <&vddwifipa>;
				merlion-chip-en-gpios = <&ap_gpio>, <0x76 0x00>;
				merlion-rst-gpios = <&ap_gpio>, <0x75 0x00>;
				xtal-26m-type-sel-gpios = <&ap_gpio>, <0xad 0x00>;
				nvmem-cells = <&wcn_alpha>;
				nvmem-cell-names = "wcn_efuse_blk0";
				#address-cells = <0x02>;
				#size-cells = <0x02>;
				phandle = <0x38>;

				sprd_wlan: wlan {
					compatible = "sprd,sc2355-sipc-wifi";
					reg = <0x00 0x87380000 0x00 0x280000>;
					sprd,enable-chr;
					phandle = <0x39>;
				};

				wcn-sblk-reset-bus-chn {
					sprd,wcn-wifi-data0-tx = <0x12 0x40 0x200 0x380 0x200>;
					sprd,wcn-wifi-data0-rx = <0x13 0x40 0x200 0x380 0x200>;
				};

				wcn-dump {

					btwf-dump {
						sprd,bt-iram = <0x10004000 0x10000 0x41500000 0x00>;
						sprd,btwf-share-mem = <0x00 0x800000 0x87000000 0x00>;
					};
				};
			};

			wcn_gnss: cpwcn-gnss {
				compatible = "unisoc,integrate_gnss";
				sprd,name = "wcn_gnss";
				sprd,syscon-ap-apb = <&aon_apb_regs>;
				sprd,syscon-ap-pmu = <&pmu_apb_regs>;
				sprd,syscon-wcn-aon-apb = <&wcncp_aon_apb_regs>;
				sprd,syscon-wcn-aon-ahb = <&wcncp_aon_ahb_regs>;
				sprd,syscon-ap-pub-apb = <&pub_apb_regs>;
				sprd,syscon-wcn-gnss-ahb = <&wcncp_gnss_ahb_regs>;
				sprd,ctrl-probe-num = <0x01>;
				sprd,ctrl-reg = <0x9018 0x23a8 0x2818 0x23a8 0x90 0xc8 0x0c 0x1404 0x50 0x0c>;
				sprd,ctrl-mask = <0x3fff 0x2000000 0x80 0x1000000 0x40000000 0x100f 0x22 0x1ffffff 0xffffffff 0x22>;
				sprd,ctrl-value = <0x70 0x2000000 0x80 0x1000000 0x40000000 0x00 0x22 0x1600000 0x1ffc00 0x00>;
				sprd,ctrl-rw-offset = <0x1000 0x2000 0x2000 0x2000 0x00 0x00 0x00 0x1000 0x00 0x00>;
				sprd,ctrl-us-delay = <0x3e8 0x3e8 0x3e8 0x7d0 0x3e8 0x3e8 0x3e8 0x3e8 0x3e8 0x3e8>;
				sprd,ctrl-type = <0x02 0x01 0x01 0x01 0x0a 0x0a 0x09 0x08 0x09 0x09>;
				sprd,ctrl-shutdown-reg = <0xc8>;
				sprd,ctrl-shutdown-mask = <0x1000>;
				sprd,ctrl-shutdown-value = <0x1000>;
				sprd,ctrl-shutdown-rw-offset = <0x00>;
				sprd,ctrl-shutdown-us-delay = <0x0a>;
				sprd,ctrl-shutdown-type = <0x0a>;
				reg = <0x00 0x87600000 0x00 0x180000>;
				sprd,file-name = "/dev/block/platform/soc/soc:ap-apb/201d0000.sdio/by-name/gnssmodem";
				sprd,file-name-ext = "/dev/block/platform/soc/soc:ap-apb/201d0000.sdio/by-name/gnssmodem";
				sprd,file-name-ufs = "/dev/block/platform/soc/soc:ap-apb/20200000.ufs/by-name/gnssmodem";
				sprd,file-name-ext-ufs = "/dev/block/platform/soc/soc:ap-apb/20200000.ufs/by-name/gnssmodem";
				sprd,file-length = <0x180000>;
				sprd,rstpad-setting = <0x01>;
				sprd,apcp-sync-addr = <0x1ffc00>;
				sprd,wcn-sipc-ver = <0x01>;
				vddwcn-supply = <&vddwcn>;
				dcxo1v8-supply = <&vddsim2>;
				merlion-chip-en-gpios = <&ap_gpio>, <0x76 0x00>;
				merlion-rst-gpios = <&ap_gpio>, <0x75 0x00>;
				#address-cells = <0x01>;
				#size-cells = <0x01>;
				nvmem-cells = <&wcn_alpha>;
				nvmem-cell-names = "gnss_efuse_blk0";
				phandle = <0x3a>;

				wcn-dump {

					gnss-dump {
						sprd,aon-control = <0x40c00000 0x64 0x11000000 0x00>;
						sprd,aon-ahb-sys = <0x40b18000 0x42c 0x11000000 0x00>;
						sprd,aon-apb-peri = <0x40bc8000 0x2e4 0x11000000 0x00>;
						sprd,aon-wcn-gnss-clk = <0x40bd8000 0x54 0x11000000 0x00>;
						sprd,gnss-iram-pchannel = <0x40e40000 0x20000 0x11000000 0x00>;
						sprd,gnss-iram = <0x40a50000 0x8000 0x11000000 0x00>;
						sprd,gnss-sipc-buff = <0x88240000 0x40000 0x00 0x00>;
						sprd,gnss-share-mem = <0x00 0x200000 0x87600000 0x00>;
					};
				};
			};

			gnss_common_ctl {
				compatible = "sprd,gnss";
				sprd,name = "gnss_common_ctl";
			};

			pwm_backlight: sprd_backlight {
				compatible = "sprd,sharkl6-backlight";
				pwms = <&pwms>, <0x02 0x9c40>;
				pwm-names = "backlight";
				sprd,max-brightness-level = <0x39c>;
				default-brightness-level = <0x106>;
				sprd,brightness-scale = <0x3ff>;
				brightness-levels = <0x00 0x03 0x04 0x05 0x06 0x07 0x08 0x09 0x0a 0x0b 0x0c 0x0d 0x0e 0x10 0x11 0x12 0x13 0x14 0x15 0x16 0x17 0x18 0x19 0x1a 0x1b 0x1c 0x1d 0x1f 0x21 0x23 0x25 0x27 0x29 0x2b 0x2d 0x2f 0x30 0x32 0x34 0x36 0x38 0x3a 0x3c 0x3e 0x40 0x43 0x45 0x48 0x4a 0x4c 0x4e 0x50 0x52 0x54 0x56 0x58 0x5a 0x5c 0x5e 0x60 0x62 0x64 0x66 0x68 0x6b 0x6d 0x70 0x72 0x74 0x76 0x78 0x7a 0x7c 0x7e 0x80 0x82 0x84 0x86 0x88 0x8a 0x8c 0x8e 0x90 0x93 0x95 0x97 0x9a 0x9c 0x9e 0xa0 0xa2 0xa4 0xa6 0xa8 0xaa 0xac 0xaf 0xb2 0xb5 0xb8 0xbb 0xbe 0xc1 0xc4 0xc7 0xcb 0xcd 0xd0 0xd3 0xd6 0xd9 0xdc 0xdf 0xe2 0xe5 0xea 0xed 0xf0 0xf3 0xf7 0xfa 0xfd 0x100 0x103 0x107 0x10a 0x10d 0x10e 0x112 0x115 0x118 0x11b 0x11f 0x122 0x126 0x129 0x12c 0x12f 0x133 0x136 0x13a 0x13e 0x145 0x149 0x14e 0x153 0x154 0x157 0x15b 0x15e 0x162 0x166 0x16d 0x171 0x176 0x17c 0x17e 0x181 0x185 0x188 0x18c 0x190 0x197 0x19b 0x1a0 0x1a6 0x1aa 0x1ae 0x1b2 0x1b6 0x1ba 0x1be 0x1c4 0x1c9 0x1cc 0x1d0 0x1d6 0x1da 0x1e0 0x1e6 0x1ec 0x1f2 0x1f8 0x1fc 0x200 0x204 0x20a 0x20f 0x214 0x218 0x21c 0x221 0x226 0x22b 0x231 0x238 0x23e 0x243 0x248 0x24d 0x252 0x258 0x25d 0x262 0x267 0x26c 0x271 0x276 0x27b 0x281 0x287 0x28c 0x291 0x296 0x29b 0x2a1 0x2b0 0x2b6 0x2bc 0x2c2 0x2c8 0x2cc 0x2d0 0x2d5 0x2da 0x2df 0x2e4 0x2ea 0x2f0 0x2f6 0x2fc 0x302 0x308 0x30e 0x316 0x31e 0x323 0x32a 0x331 0x339 0x340 0x348 0x34d 0x352 0x357 0x35d 0x362 0x368 0x36e 0x374 0x37a 0x380 0x387 0x38f 0x396 0x39c>;
				phandle = <0x1f>;
			};

			skin_sensor: skin-sensor {
				compatible = "sprd,virt-thm";
				#thermal-sensor-cells = <0x00>;
				thmzone-cells = <&bd_thmzone>;
				phandle = <0x1c>;
			};

			fingerprint@0 {
				compatible = "microarray,afs121";
				fpint-gpios = <&eic_async>, <0x1d 0x00>;
			};

			gpio-keys {
				compatible = "gpio-keys";

				key-volumedown {
					label = "Volume Down Key";
					linux,code = <0x72>;
					gpios = <&ap_gpio>, <0x7c 0x01>;
					debounce-interval = <0x02>;
					wakeup-source;
				};

				key-volumeup {
					label = "Volume Up Key";
					linux,code = <0x73>;
					gpios = <&pmic_eic>, <0x04 0x00>;
					debounce-interval = <0x02>;
					wakeup-source;
				};

				key-power {
					label = "Power Key";
					linux,code = <0x74>;
					gpios = <&pmic_eic>, <0x01 0x01>;
					debounce-interval = <0x02>;
					wakeup-source;
				};
			};

			audio-voice-trig {
				status = "disable";
				compatible = "sprd,voice_trig";
				irq_gpio = <&ap_gpio>, <0xa9 0x00>;
			};

			sprd-uid {
				compatible = "sprd,uid";
				nvmem-cells = <&uid_start>, <&uid_end>;
				nvmem-cell-names = "uid_start", "uid_end";
			};
		};
	};

	fragment@0 {
		target = <&spi3>;

		__overlay__ {
			status = "okay";
			#address-cells = <0x01>;
			#size-cells = <0x00>;

			omnivision_tcm@0 {
				compatible = "omnivision_tcm-modules", "chipone-tddi-modules", "himax_mmi-modules", "focaltech,fts-modules", "jadard,jdcommon-modules";
				reg = <0x00>;
				spi-max-frequency = <0x927c00>;
				panel = <&lcd_td4160_cw_old_mipi_hd>, <&lcd_td4160_cw_new_mipi_hd>, <&lcd_td4160_cw_mipi_hd>, <&lcd_hx83108a_lce_mipi_hd>, <&lcd_hx83108a_boe_mipi_hd>, <&lcd_ft8057_ld_mipi_hd>, <&lcd_icnl9916c_ld_hjc_mipi_hd>, <&lcd_icnl9916c_inx_mipi_hd>, <&lcd_icnl9916c_hjc_cd_mipi_hd>, <&lcd_td4160b_cw_boe_mipi_hd>, <&lcd_ft8057p_ld_mipi_hd>;
				omnivision,irq-gpio = <&ap_gpio>, <0x90 0x2008>;
				omnivision,irq-on-state = <0x00>;
				omnivision,reset-gpio = <&ap_gpio>, <0x92 0x00>;
				omnivision,reset-on-state = <0x00>;
				omnivision,reset-active-ms = <0x14>;
				omnivision,reset-delay-ms = <0xc8>;
				omnivision,power-delay-ms = <0xc8>;
				omnivision,spi-mode = <0x03>;
				omnivision,byte-delay-us = <0x00>;
				omnivision,block-delay-us = <0x00>;
				omnivision,ubl-max-freq = <0x2dc6c0>;
				omnivision,ubl-byte-delay-us = <0x14>;
				spi-cpha;
				himax,panel-coords = <0x00 0x2d0 0x00 0x640>;
				himax,display-coords = <0x00 0x2d0 0x00 0x640>;
				himax,irq-gpio = <&ap_gpio>, <0x90 0x2008>;
				himax,rst-gpio = <&ap_gpio>, <0x92 0x00>;
				report_type = <0x01>;
				focaltech,reset-gpio = <&ap_gpio>, <0x92 0x00>;
				focaltech,irq-gpio = <&ap_gpio>, <0x90 0x2008>;
				focaltech,max-touch-number = <0x0a>;
				focaltech,display-coords = <0x00 0x00 0x2cf 0x63f>;
				chipone,rst-gpio = <&ap_gpio>, <0x92 0x00>;
				chipone,irq-gpio = <&ap_gpio>, <0x90 0x2008>;
				chipone,x-res = <0x2d0>;
				chipone,y-res = <0x640>;
				chipone,touch-charger-detect-enable;
				chipone,touch-charger-detect-type = "notify";
				chipone,touch-charger-detect-psy-name = "charger";
				chipone,touch-charger-detect-psp = "POWER_SUPPLY_PROP_ONLINE";
				chipone,touch-charger-detect-psp-poll-interval = <0x3e8>;
				chipone,touch-earjack-detect-enable;
				chipone,touch-earjack-state-filepath = "/sys/bus/platform/drivers/Accdet_Driver/state";
				chipone,touch-earjack-poll-interval = <0x3e8>;
				chipone,test-reset-pin;
				chipone,test-int-pin;
				chipone,test-rawdata;
				chipone,test-rawdata-frames = <0x01>;
				chipone,rawdata-min = <0x44c>;
				chipone,rawdata-max = <0xb54>;
				chipone,test-noise;
				chipone,test-noise-frames = <0x32>;
				chipone,noise-max = <0x78>;
				chipone,test-open;
				chipone,open-min = <0x640>;
				chipone,test-short;
				chipone,short-min = <0x640>;
				chipone,test-compensate-cap;
				chipone,compensate-cap-min = <0x01>;
				chipone,compensate-cap-max = <0x7f>;
				chipone,test-gesture-rawdata;
				chipone,test-gesture-rawdata-frames = <0x03>;
				chipone,gesture-rawdata-min = <0x708>;
				chipone,gesture-rawdata-max = <0x1518>;
				chipone,test-gesture-lp-rawdata;
				chipone,test-gesture-lp-rawdata-frames = <0x03>;
				chipone,gesture-lp-rawdata-min = <0x708>;
				chipone,gesture-lp-rawdata-max = <0x1518>;
				chipone,test-gesture-noise;
				chipone,test-gesture-noise-frames = <0x03>;
				chipone,gesture-noise-max = <0x78>;
				chipone,test-gesture-lp-noise;
				chipone,test-gesture-lp-noise-frames = <0x03>;
				chipone,gesture-lp-noise-max = <0x78>;
				jadard,panel-sense-nums = <0x12 0x20>;
				jadard,panel-coords = <0x00 0x2d0 0x00 0x640>;
				jadard,panel-max-points = <0x0a>;
				jadard,int-is-edge = <0x01>;
				jadard,irq-gpio = <&ap_gpio>, <0x90 0x2008>;
				jadard,rst-gpio = <&ap_gpio>, <0x92 0x00>;
			};
		};
	};

	fragment@1 {
		target = <&bat>;

		__overlay__ {
			compatible = "simple-battery";
			status = "okay";
			charge-full-design-microamp-hours = <0x2d0370>;
			charge-full-microamp-hours = <0x2d0370>;
			charge-term-current-microamp = <0xea60>;
			constant-charge-voltage-max-microvolt = <0x423920>;
			factory-internal-resistance-micro-ohms = <0x3d860>;
			voltage-min-design-microvolt = <0x34a490>;
			fast-charge-threshold-microvolt = <0x3e8fa0>;
			fullbatt-voltage = <0x419ce0>;
			fullbatt-current = <0x1d4c0>;
			first-fullbatt-current = <0x249f0>;
			fullbatt-track-end-vol = <0x418958>;
			fullbatt-track-end-cur = <0x1fbd0>;
			first-calib-voltage = <0x36a060>;
			first-calib-capacity = <0x32>;
			ir-cv-offset-microvolt = <0x186a0>;
			ir-rc-micro-ohms = <0x4e20>;
			ir-us-upper-limit-microvolt = <0x44aa20>;
			ocv-capacity-celsius = <0x14>;
			ocv-capacity-table-0 = <0x41cfa8 0x64 0x40e930 0x5f 0x401a28 0x5a 0x3f56d8 0x55 0x3e9770 0x50 0x3df360 0x4b 0x3d2070 0x46 0x3c9f88 0x41 0x3bf790 0x3c 0x3b3c10 0x37 0x3ac2f8 0x32 0x3a6d08 0x2d 0x3a22d0 0x28 0x39e838 0x23 0x39b188 0x1e 0x397308 0x19 0x3928d0 0x14 0x38cb10 0x0f 0x385db0 0x0a 0x382ed0 0x05 0x33e140 0x00>;
			voltage-temp-table = <0x10f0fe 0x320 0xf4010 0x352 0xd963e 0x384 0xbfcb6 0x3b6 0xa7e0e 0x3e8 0x920cc 0x41a 0x7e630 0x44c 0x6ce94 0x47e 0x5d99e 0x4b0 0x504f6 0x4e2 0x44cf0 0x514 0x3af48 0x546 0x328b6 0x578 0x2b5ac 0x5aa 0x253aa 0x5dc 0x20058 0x60e 0x1b968 0x640 0x17dfe 0x672>;
			capacity-temp-table = <0x2d 0x64 0x19 0x64 0x0a 0x64 0x00 0x5f 0xfffffff6 0x5a>;
			resistance-temp-table = <0x2d 0x35 0x19 0x64 0x0a 0x18b 0x00 0x237 0xfffffff6 0x319>;
			temp-advance-fullcap-table = <0x32 0x64 0x19 0x64 0x0a 0x64 0x00 0x64 0xfffffff6 0x64 0xffffffec 0x64>;
			charge-sdp-current-microamp = <0x7a120 0x7a120>;
			charge-dcp-current-microamp = <0x1e8480 0x2dc6c0>;
			charge-cdp-current-microamp = <0x16e360 0x16e360>;
			charge-unknown-current-microamp = <0xf4240 0xf4240>;
			charge-fchg-current-microamp = <0x2dc6c0 0x1e8480>;
			charge-flash-current-microamp = <0x4c4b40 0x2932e0>;
			cap-calib-energy-density-ocv-table = <0x331df0 0x39fbc0 0x3f52f0 0x426030>;
			cap-track-energy-density-ocv-table = <0x33e140 0x38cb10>;
			dcp-jeita-temp-table = <0x3e8 0x406 0x00 0x423920 0x47e 0x49c 0xaae60 0x423920 0x5aa 0x58c 0x1e8480 0x423920 0x640 0x622 0xaae60 0x3e8fa0>;
			sdp-jeita-temp-table = <0x3e8 0x406 0x00 0x423920 0x47e 0x49c 0x7a120 0x423920 0x5aa 0x58c 0x7a120 0x423920 0x640 0x622 0x7a120 0x3e8fa0>;
			cdp-jeita-temp-table = <0x3e8 0x406 0x00 0x423920 0x47e 0x49c 0xaae60 0x423920 0x5aa 0x58c 0x16e360 0x423920 0x640 0x622 0xaae60 0x3e8fa0>;
			unknown-jeita-temp-table = <0x3e8 0x406 0x00 0x423920 0x47e 0x49c 0xaae60 0x423920 0x5aa 0x58c 0xf4240 0x423920 0x640 0x622 0xaae60 0x3e8fa0>;
			fchg-jeita-temp-table = <0x3e8 0x406 0x00 0x423920 0x47e 0x49c 0xaae60 0x423920 0x5aa 0x58c 0x319750 0x423920 0x640 0x622 0xaae60 0x3e8fa0>;
			flash-jeita-temp-table = <0x3e8 0x406 0x00 0x423920 0x47e 0x49c 0xf4240 0x423920 0x5aa 0x58c 0x4c4b40 0x423920 0x640 0x622 0xf4240 0x3e8fa0>;
		};
	};

	fragment@2 {
		target = <&cm>;

		__overlay__ {
			compatible = "charger-manager";
			status = "okay";
			cm-name = "battery";
			cm-poll-mode = <0x02>;
			cm-poll-interval = <0x3a98>;
			cm-battery-stat = <0x02>;
			cm-fullbatt-vchkdrop-ms = <0x7530>;
			cm-fullbatt-vchkdrop-volt = <0xea60>;
			cm-fullbatt-capacity = <0x64>;
			cm-cp-taper-current = <0xf4240>;
			cm-chargers = "bq2560x_charger";
			cm-charge-pumps = "bq2597x-standalone";
			cm-fuel-gauge = "sc27xx-fgu";
			cm-battery-cold = <0xc8>;
			cm-battery-cold-in-minus;
			cm-battery-hot = <0x320>;
			cm-battery-temp-diff = <0x64>;
			cm-charging-max = <0x1499700>;
			cm-discharging-max = <0x2932e0>;
			cm-wdt-interval = <0x3c>;
			cm-shutdown-voltage = <0x2f4d60>;
			cm-tickle-time-out = <0x5dc>;
			cm-one-cap-time = <0x1e>;
			cm-thermal-zone = "board-thmzone";
			cm-charge-voltage-max = <0x632ea0>;
			cm-fast-charge-voltage-max = <0xa037a0>;
			cm-flash-charge-voltage-max = <0xb71b00>;
			cm-charge-voltage-drop = <0xaae60>;
			cm-fast-charge-voltage-drop = <0xaae60>;
			cm-flash-charge-voltage-drop = <0xf4240>;
			sprd,support-fchg;
			sprd,support-pd-pps;
			sprd,pd-fixed-max-microwatt = <0x112a880>;
			monitored-battery-0 = <&bat>;
			cm-capacity-track;
			cm-keep-awake;
			phys = <&hsphy>;
			pd-extcon-enable;
			extcon = <&pmic_typec>, <&pmic_pd>;
			use-typec-extcon;
		};
	};

	fragment@3 {
		target = <&i2c5>;

		__overlay__ {
			#address-cells = <0x01>;
			#size-cells = <0x00>;
			status = "okay";

			bq2560x_chg: charger@6b {
				compatible = "ti,bq2560x_chg";
				reg = <0x6b>;
				monitored-battery-0 = <&bat>;
				irq-gpio = <&ap_gpio>, <0x73 0x01>;
				use-typec-extcon;
				phandle = <0x3b>;

				vddvbus: otg-vbus {
					regulator-name = "vddvbus";
					phandle = <0x1b>;
				};
			};

			bq2597x_chg: charger@65 {
				compatible = "ti,bq2597x-standalone";
				reg = <0x65>;
				irq-gpio = <&ap_gpio>, <0x7e 0x01>;
				ti,bq2597x,bus-therm-disable = <0x01>;
				ti,bq2597x,regulation-disable = <0x01>;
				ti,bq2597x,bat-ovp-threshold = <0x1130>;
				ti,bq2597x,bat-ovp-alarm-threshold = <0x10f4>;
				ti,bq2597x,bat-ocp-threshold = <0x157c>;
				ti,bq2597x,bat-ocp-alarm-threshold = <0x1388>;
				ti,bq2597x,bus-ovp-threshold = <0x2cec>;
				ti,bq2597x,bus-ovp-alarm-threshold = <0x2904>;
				ti,bq2597x,bus-ocp-threshold = <0xbb8>;
				ti,bq2597x,bus-ocp-alarm-threshold = <0xa8c>;
				ti,bq2597x,bat-ucp-alarm-threshold = <0x3e8>;
				ti,bq2597x,bat-therm-threshold = <0x15>;
				ti,bq2597x,bus-therm-threshold = <0x15>;
				ti,bq2597x,die-therm-threshold = <0xc8>;
				ti,bq2597x,ac-ovp-threshold = <0x0d>;
				ti,bq2597x,sense-resistor-mohm = <0x05>;
				ti,bq2597x,adc-sample-bits = <0x0d>;
				ti,bq2597x,ibat-regulation-threshold = <0x12c>;
				ti,bq2597x,vbat-regulation-threshold = <0x64>;
				ti,bq2597x,vdrop-threshold = <0x190>;
				ti,bq2597x,vdrop-deglitch = <0x1388>;
				ti,bq2597x,ss-timeout = <0x186a0>;
				ti,bq2597x,watchdog-timer = <0x7530>;
				phandle = <0x3c>;
			};
		};
	};

	fragment@4 {
		target = <&pmic_fgu>;

		__overlay__ {
			monitored-battery-0 = <&bat>;
			fgu-cap-remap-table = <0x01 0x02 0x03 0x02 0x03 0x02 0x62 0x63 0x02 0x63 0x64 0x03>;
			sprd,calib-resistance-micro-ohms = <0x12f2>;
			sprd,comp-resistance-mohm = <0x0b>;
			fgu-capacity-track;
			phys = <&hsphy>;
			sprd,relax-counter-threshold = <0x244>;
			sprd,relax-current-threshold = <0x1e>;
			sprd,capacity-sleep-calibration;
			sprd,capacity-boot-calibration;
			use-typec-extcon;
			extcon = <&pmic_typec>;
		};
	};

	fragment@5 {
		target = <&pmic_fchg>;

		__overlay__ {
			status = "okay";
			sprd,input-voltage-microvolt = <0x4c4b40>;
			sprd,ext-dev-comp-cur-code = <0x1e>;
		};
	};

	fragment@6 {
		target = <&pmic_pd>;

		__overlay__ {
			status = "okay";
			vbus-supply = <&vddvbus>;
			use-pdhub-c2c;
			sprd,syscon-aon-apb = <&aon_apb_regs>;

			usb_con: connector {
				compatible = "usb-c-connector";
				label = "USB-C";
				power-role = "dual";
				try-power-role = "sink";
				source-pdos = <0x26019028>;
				sink-pdos = <0x2601912c 0xc0dc213c>;
				op-sink-microwatt = <0x989680>;
				phandle = <0x3d>;
			};
		};
	};

	fragment@7 {
		target = <&reserved_memory>;

		__overlay__ {

			protected_reserved: protected-mem@80003000 {
				reg = <0x00 0x80003000 0x00 0x2000>;
				phandle = <0x29>;
			};

			secured_reserved: secured@ff870000 {
				reg = <0x00 0xff870000 0x00 0x200000>;
				phandle = <0x27>;
			};

			fd_reserved: faceid-mem@ffa70000 {
				reg = <0x00 0xffa70000 0x00 0x500000>;
				phandle = <0x28>;
			};
		};
	};

	fragment@8 {
		target = <&sipc>;

		__overlay__ {
			#address-cells = <0x01>;
			#size-cells = <0x00>;

			sipc_wcn: core@3 {
				compatible = "sprd,sipc";
				reg = <0x03>;
				label = "sipc-wcn";
				mboxes = <&mailbox>, <0x08 0x00>;
				sprd,smem-info = <0x87240000 0x240000 0x140000>;
				phandle = <0x3e>;

				wcn_bt {
					compatible = "sprd,wcn_internal_chip";
					sprd,name = "ttyBT";
					sprd,dst = <0x03>;
					sprd,channel = <0x04>;
					sprd,tx_bufid = <0x0b>;
					sprd,rx_bufid = <0x0a>;
				};

				wcn_fm {
					compatible = "sprd,wcn_fm_internal_chip";
					sprd,name = "fm";
					sprd,dst = <0x03>;
					sprd,tx_channel = <0x04>;
					sprd,rx_channel = <0x04>;
					sprd,tx_bufid = <0x0e>;
					sprd,rx_bufid = <0x0d>;
				};
			};

			sipc_gnss: core@4 {
				compatible = "sprd,sipc";
				#address-cells = <0x01>;
				#size-cells = <0x00>;
				reg = <0x04>;
				label = "sipc-gnss";
				mboxes = <&mailbox>, <0x09 0x00>;
				sprd,smem-info = <0x8749b000 0x11b000 0x32000>;
				phandle = <0x3f>;

				sttygnss0: channel@4 {
					compatible = "sprd,spipe";
					reg = <0x04>;
					label = "sttygnss0";
					sprd,ringnr = <0x01>;
					sprd,size-rxbuf = <0x19000>;
					sprd,size-txbuf = <0xc800>;
					phandle = <0x40>;
				};
			};
		};
	};

	fragment@9 {
		target = <&chosen>;

		__overlay__ {
			bootargs_ext = "kvm-arm.mode=none";
		};
	};

	fragment@10 {
		target = <&skin_thmzone>;

		__overlay__ {
			thermal-sensors = <&skin_sensor>;
		};
	};

	fragment@11 {
		target = <&i2c0>;

		__overlay__ {
			status = "okay";
			clock-frequency = <0x61a80>;
			#address-cells = <0x01>;
			#size-cells = <0x00>;

			sensor_main: sensor-main@20 {
				compatible = "sprd,sensor-main";
				reg = <0x20>;
				clock-names = "clk_src", "sensor_eb", "clk_96m", "clk_76m8", "clk_48m", "clk_26m";
				clocks = <&mm_clk>, <0x02>, <&mm_gate>, <0x0d>, <&pll1>, <0x04>, <&pll1>, <0x10>, <&pll1>, <0x05>, <&ext_26m>;
				vddio-supply = <&vddcamio>;
				vddcama-supply = <&vddcama0>;
				dvdd-gpios = <&ap_gpio>, <0x0b 0x00>;
				vddcammot-supply = <&vddcammot>;
				reset-gpios = <&ap_gpio>, <0x2d 0x00>;
				power-down-gpios = <&ap_gpio>, <0x2f 0x00>;
				sprd,phyid = <0x00>;
				csi = <&csi0>;
				power-domains = <&mm_domain>;
				phandle = <0x41>;
			};

			sensor_sub: sensor-sub@5a {
				compatible = "sprd,sensor-sub";
				reg = <0x5a>;
				clock-names = "clk_src", "sensor_eb", "clk_96m", "clk_76m8", "clk_48m", "clk_26m";
				clocks = <&mm_clk>, <0x02>, <&mm_gate>, <0x0d>, <&pll1>, <0x04>, <&pll1>, <0x10>, <&pll1>, <0x05>, <&ext_26m>;
				vddio-supply = <&vddcamio>;
				vddcama-supply = <&vddcama0>;
				dvdd-gpios = <&ap_gpio>, <0x0b 0x00>;
				vddcammot-supply = <&vddcammot>;
				reset-gpios = <&ap_gpio>, <0x2c 0x00>;
				power-down-gpios = <&ap_gpio>, <0x2e 0x00>;
				sprd,phyid = <0x02>;
				csi = <&csi0>;
				power-domains = <&mm_domain>;
				phandle = <0x42>;
			};
		};
	};

	fragment@12 {
		target = <&i2c1>;

		__overlay__ {
			status = "okay";
			clock-frequency = <0x61a80>;
			#address-cells = <0x01>;
			#size-cells = <0x00>;

			sensor_main2: sensor-main2@20 {
				compatible = "sprd,sensor-main2";
				reg = <0x20>;
				clock-names = "clk_src", "sensor_eb", "clk_96m", "clk_76m8", "clk_48m", "clk_26m";
				clocks = <&mm_clk>, <0x03>, <&mm_gate>, <0x0c>, <&pll1>, <0x04>, <&pll1>, <0x10>, <&pll1>, <0x05>, <&ext_26m>;
				vddio-supply = <&vddcamio>;
				vddcama-supply = <&vddcama1>;
				vddcamd-supply = <&vddcamd0>;
				vddcammot-supply = <&vddcammot>;
				avdd-gpios = <&ap_gpio>, <0x0a 0x00>;
				mot-gpios = <&ap_gpio>, <0x58 0x00>;
				reset-gpios = <&ap_gpio>, <0x29 0x00>;
				power-down-gpios = <&ap_gpio>, <0x28 0x00>;
				sprd,phyid = <0x04>;
				csi = <&csi1>;
				power-domains = <&mm_domain>;
				phandle = <0x43>;
			};
		};
	};

	fragment@13 {
		target = <&i2c5>;

		__overlay__ {
			status = "okay";
			clock-frequency = <0x61a80>;

			hl1506_cp_converter: charger@1b {
				compatible = "halo,hl1506_cp_converter";
				reg = <0x1b>;
				chg_pump_en_gpio = <&ap_gpio>, <0x93 0x00>;
				phandle = <0x44>;
			};

			nu1619_rx: charger@61 {
				compatible = "nuvolta,wl_charger_nu1619";
				reg = <0x61>;
				phys = <&hsphy>;
				rx,irq_gpio = <&ap_gpio>, <0x92 0x01>;
				switch_chg_en_gpio = <&ap_gpio>, <0xab 0x00>;
				switch_flag_en_gpio = <&ap_gpio>, <0xb0 0x00>;
				phandle = <0x45>;
			};

			flash_ic: flash-ic@63 {
				compatible = "sprd,flash-ocp8137";
				reg = <0x63>;
				sprd,flash-ic = <0x1fc9>;
				sprd,torch = <0x01>;
				sprd,preflash = <0x01>;
				sprd,highlight = <0x01>;
				sprd,torch-level = <0x80>;
				sprd,preflash-level = <0x80>;
				sprd,highlight-level = <0x80>;
				sprd,lvfm-enable = <0x01>;
				flash-torch-en-gpios = <&ap_gpio>, <0x20 0x00>;
				flash-chip-en-gpios = <&ap_gpio>, <0x8a 0x00>;
				flash-en-gpios = <&ap_gpio>, <0x8b 0x00>;
				flash-sync-gpios = <&ap_gpio>, <0x79 0x00>;
				phandle = <0x46>;
			};
		};
	};

	fragment@14 {
		target = <&i2c6>;

		__overlay__ {
			status = "okay";
			clock-frequency = <0x61a80>;
			#address-cells = <0x01>;
			#size-cells = <0x00>;

			sensor_sub2: sensor-sub2@6e {
				compatible = "sprd,sensor-sub2";
				reg = <0x6e>;
				clock-names = "clk_src", "sensor_eb", "clk_96m", "clk_76m8", "clk_48m", "clk_26m";
				clocks = <&mm_clk>, <0x04>, <&mm_gate>, <0x0b>, <&pll1>, <0x04>, <&pll1>, <0x10>, <&pll1>, <0x05>, <&ext_26m>;
				vddio-supply = <&vddcamio>;
				avdd-gpios = <&ap_gpio>, <0x82 0x00>;
				vddcamd-supply = <&vddcamd1>;
				vddcammot-supply = <&vddcammot>;
				mot-gpios = <&ap_gpio>, <0x70 0x00>;
				reset-gpios = <&ap_gpio>, <0x72 0x00>;
				sprd,phyid = <0x03>;
				csi = <&csi2>;
				phandle = <0x47>;
			};
		};
	};

	fragment@15 {
		target = <&hsphy>;

		__overlay__ {
			vdd-supply = <&vddusb33>;
			extcon = <&pmic_typec>;
			sprd,hsphy-device-eye-pattern = <0x613d1c0>;
			sprd,hsphy-host-eye-pattern = <0x4f3d1c0>;
			status = "okay";
		};
	};

	fragment@16 {
		target = <&usb>;

		__overlay__ {
			extcon = <&pmic_typec>, <&pmic_typec>;
			vbus-supply = <&vddvbus>;
			use_pdhub_c2c;
			status = "okay";
		};
	};

	fragment@17 {
		target = <&pmic_typec>;

		__overlay__ {
			use_pdhub_c2c;
			extcon = <&extcon_gpio>;
			status = "okay";
		};
	};

	fragment@18 {
		target = <&sdio0>;

		__overlay__ {
			cd-gpios = <&eic_sync>, <0x23 0x00>;
		};
	};

	fragment@19 {
		target = <&i2c2>;

		__overlay__ {
			status = "okay";
			#address-cells = <0x01>;
			#size-cells = <0x00>;

			sec-nfc@27 {
				compatible = "sec-nfc";
				reg = <0x27>;
				clock-names = "nfc_clk", "source", "enable";
				clocks = <&aon_clk>, <0x04>, <&ext_26m>, <&aonapb_gate>, <0x06>;
				sec-nfc,ven-gpio = <&ap_gpio>, <0x3f 0x00>;
				sec-nfc,firm-gpio = <&ap_gpio>, <0x3d 0x00>;
				sec-nfc,irq-gpio = <&ap_gpio>, <0x3e 0x00>;
				sec-nfc,clk-req = <&ap_gpio>, <0x3c 0x00>;
			};

			ucp1301_rcv: ucp1301@58 {
				compatible = "unisoc,ucp1301-rcv";
				reg = <0x58>;
				reset-gpios = <&ap_gpio>, <0xac 0x00>;
				#sound-dai-cells = <0x01>;
				phandle = <0x1e>;
			};
		};
	};

	fragment@20 {
		target = <&i2c3>;

		__overlay__ {
			status = "okay";
			#address-cells = <0x01>;
			#size-cells = <0x00>;
		};
	};

	fragment@21 {
		target = <&i2c4>;

		__overlay__ {
			status = "okay";
			#address-cells = <0x01>;
			#size-cells = <0x00>;

			ucp1301_spk: ucp1301@58 {
				compatible = "unisoc,ucp1301-spk";
				reg = <0x58>;
				reset-gpios = <&ap_gpio>, <0xa7 0x00>;
				#sound-dai-cells = <0x01>;
				phandle = <0x1d>;
			};

			stm_vl53l0: vl53l0@52 {
				compatible = "st,stmvl53l0";
				reg = <0x52>;
				reset_gpios = <0xa8>;
				irq_gpios = <0xa9>;
				interrupt-parent = <&ap_gpio>;
				interrupts = <0xa9 0x08>;
				phandle = <0x48>;
			};
		};
	};

	fragment@22 {
		target = <&aon_i2c0>;

		__overlay__ {
			status = "okay";
			clock-frequency = <0xf4240>;
		};
	};

	fragment@23 {
		target = <&sprd_headset>;

		__overlay__ {
			status = "okay";
			extcon = <&pmic_typec>;
			mic-gpios = <&ap_gpio>, <0xaf 0x00>;
			lr-gpios = <&ap_gpio>, <0xae 0x00>;
			sprd,3pole-adc-threshold = <0x70>;
		};
	};

	fragment@24 {
		target = <&pdm_dmic>;

		__overlay__ {
			status = "okay";
		};
	};

	fragment@25 {
		target = <&agdsp_domain>;

		__overlay__ {
			status = "okay";
		};
	};

	fragment@26 {
		target = <&sound_vbc_v4_sprd_codec>;

		__overlay__ {
			status = "okay";
			sprd-audio-card,routing = "HPMIC Pin", "HP Mic Jack", "MIC Pin", "Mic Jack", "MIC2 Pin", "Aux Mic Jack", "HeadPhone Jack", "HP Pin", "Ext Spk", "SPK Pin", "UCP1301 SPK ON", "SPK Pin", "Ext Spk", "UCP1301 SPK", "PDM DMIC2 ON", "SPK Pin", "Ext Spk", "PDM_DMIC2", "DMIC Pin", "DMic Jack", "DMIC1 Pin", "DMic1 Jack", "Ext Ear", "EAR Pin", "UCP1301 RCV ON", "EAR Pin", "Ext Ear", "UCP1301 RCV";

			sprd-audio-card,dai-link@53 {
				ignore-suspend = <0x01>;
				link-name = "BE_NORMAL_AP01_UCPSPK";
				stream-name = "BE_ST_NORMAL_AP01_UCPSPK";
				no-pcm = <0x01>;
				dpcm-playback = <0x01>;
				be-id = <0x00>;
				dai-format = "i2s";

				plat {
					sound-dai = <&sprd_route_pcm>;
				};

				cpu {
					sound-dai = <&vbc_v4>, <0x1f>;
				};

				codec {
					sound-dai = <&ucp1301_spk>, <0x00>;
				};
			};

			sprd-audio-card,dai-link@55 {
				ignore-suspend = <0x01>;
				link-name = "BE_NORMAL_AP01_UCPRCV";
				stream-name = "BE_ST_NORMAL_AP01_UCPRCV";
				no-pcm = <0x01>;
				dpcm-playback = <0x01>;
				be-id = <0x00>;
				dai-format = "i2s";

				plat {
					sound-dai = <&sprd_route_pcm>;
				};

				cpu {
					sound-dai = <&vbc_v4>, <0x1f>;
				};

				codec {
					sound-dai = <&ucp1301_rcv>, <0x00>;
				};
			};

			sprd-audio-card,dai-link@81 {
				ignore-suspend = <0x01>;
				link-name = "BE_PDM_DMIC";
				stream-name = "BE_ST_PDM_DMIC";
				no-pcm = <0x01>;
				dpcm-capture = <0x01>;
				be-id = <0x00>;

				plat {
					sound-dai = <&sprd_route_pcm>;
				};

				cpu {
					sound-dai = <&vbc_v4>, <0x1f>;
				};

				codec {
					sound-dai = <&pdm_dmic>, <0x00>;
				};
			};
		};
	};

	fragment@27 {
		target = <&vddldo0>;

		__overlay__ {
			regulator-always-on;
		};
	};

	fragment@28 {
		target = <&panel>;

		__overlay__ {
			sprd,backlight = <&pwm_backlight>;
			avdd-gpio = <&ap_gpio>, <0x87 0x00>;
			avee-gpio = <&ap_gpio>, <0x88 0x00>;
			reset-gpio = <&ap_gpio>, <0x32 0x00>;
		};
	};

	fragment@29 {
		target = <&dpu>;

		__overlay__ {
			sprd,logo-memory = <&logo_reserved>;
			sprd,backlight = <&pwm_backlight>;
		};
	};

	fragment@30 {
		target = <&ddr_dfs>;

		__overlay__ {
			sprd-scene = "boost", "lcdon", "lcdoff", "camlow", "camhigh", "camveryhigh", "faceid", "top", "boot-opt";
			sprd-freq = <0x535 0x300 0x100 0x535 0x535 0xbacd 0x535 0xbacd 0xbacd>;
		};
	};

	fragment@31 {
		target = <&pin_controller>;

		__overlay__ {
			pinctrl-names = "gpio_8", "gpio_22", "gpio_24", "gpio_25", "gpio_26", "gpio_124", "gpio_175";
			pinctrl-0 = <&gpio_8>;
			pinctrl-1 = <&gpio_22>;
			pinctrl-2 = <&gpio_24>;
			pinctrl-3 = <&gpio_25>;
			pinctrl-4 = <&gpio_26>;
			pinctrl-5 = <&gpio_124>;
			pinctrl-6 = <&gpio_175>;

			gpio_8: rfctl16 {
				pins = "QOGIRL6_RFCTL16";
				function = "func4";
				phandle = <0x20>;
			};

			gpio_22: rfctl3 {
				pins = "QOGIRL6_RFCTL3";
				function = "func4";
				phandle = <0x21>;
			};

			gpio_24: rfctl5 {
				pins = "QOGIRL6_RFCTL5";
				function = "func4";
				phandle = <0x22>;
			};

			gpio_25: rfctl6 {
				pins = "QOGIRL6_RFCTL6";
				function = "func4";
				phandle = <0x23>;
			};

			gpio_26: rfctl7 {
				pins = "QOGIRL6_RFCTL7";
				function = "func4";
				phandle = <0x24>;
			};

			gpio_124: keyin0 {
				pins = "QOGIRL6_KEYIN0";
				function = "func4";
				phandle = <0x25>;
			};

			gpio_175: bt_rfctl2 {
				pins = "QOGIRL6_BT_RFCTL2";
				function = "func4";
				phandle = <0x26>;
			};
		};
	};

	fragment@32 {
		target = <&dmabuf>;

		__overlay__ {

			secured-reserved {
				label = "uncached_carveout_mm";
				memory-region = <&secured_reserved>;
			};

			fd-reserved {
				label = "carveout_fd";
				memory-region = <&fd_reserved>;
			};

			protected-reserved {
				label = "protected";
				memory-region = <&protected_reserved>;
			};
		};
	};

	fragment@33 {
		target = <&adi_bus>;

		__overlay__ {
			sprd,hw-channels = <0x02 0x18cc 0x03 0x18cc 0x0d 0x1854 0x0f 0x1874 0x11 0x1844 0x13 0x1844 0x15 0x1864 0x1e 0x1820 0x20 0x197c 0x21 0x1988 0x23 0x19b8 0x27 0x19ac>;
			sprd,hw-channels0 = <0x02 0x18cc 0x03 0x18cc 0x0d 0x1874 0x0f 0x1874 0x11 0x1844 0x13 0x1854 0x15 0x1864 0x1e 0x1820 0x20 0x197c 0x21 0x1988 0x23 0x19b8 0x27 0x19ac>;
			sprd,hw-channels1 = <0x02 0x18cc 0x03 0x18cc 0x0d 0x1854 0x0f 0x1874 0x11 0x1844 0x13 0x1844 0x15 0x1864 0x1e 0x1820 0x20 0x197c 0x21 0x1988 0x23 0x19b8 0x27 0x19ac>;
		};
	};

	__symbols__ {
		lcd_g40396_truly_mipi_fhd = "/fragment/__overlay__/lcds/lcd_g40396_truly_mipi_fhd";
		g40396_truly_timing0 = "/fragment/__overlay__/lcds/lcd_g40396_truly_mipi_fhd/display-timings/timing0";
		lcd_nt36672e_truly_mipi_fhd_nodsc = "/fragment/__overlay__/lcds/lcd_nt36672e_truly_mipi_fhd_nodsc";
		nt36672e_truly_timing0 = "/fragment/__overlay__/lcds/lcd_nt36672e_truly_mipi_fhd_nodsc/display-timings/timing0";
		lcd_ft8725_boe_mipi_fhd_nodsc = "/fragment/__overlay__/lcds/lcd_ft8725_boe_mipi_fhd_nodsc";
		ft8725_boe_nodsc_timing0 = "/fragment/__overlay__/lcds/lcd_ft8725_boe_mipi_fhd_nodsc/display-timings/timing0";
		lcd_dummy_mipi_hd = "/fragment/__overlay__/lcds/lcd_dummy_mipi_hd";
		dummy_timing0 = "/fragment/__overlay__/lcds/lcd_dummy_mipi_hd/display-timings/timing0";
		lcd_td4160_cw_mipi_hd = "/fragment/__overlay__/lcds/lcd_td4160_cw_mipi_hd";
		td4160_cw_timing0 = "/fragment/__overlay__/lcds/lcd_td4160_cw_mipi_hd/display-timings/timing0";
		lcd_td4160_cw_new_mipi_hd = "/fragment/__overlay__/lcds/lcd_td4160_cw_new_mipi_hd";
		td4160_cw_new_timing0 = "/fragment/__overlay__/lcds/lcd_td4160_cw_new_mipi_hd/display-timings/timing0";
		td4160_cw_new_timing1 = "/fragment/__overlay__/lcds/lcd_td4160_cw_new_mipi_hd/display-timings/timing1";
		lcd_td4160_cw_old_mipi_hd = "/fragment/__overlay__/lcds/lcd_td4160_cw_old_mipi_hd";
		td4160_cw_old_timing0 = "/fragment/__overlay__/lcds/lcd_td4160_cw_old_mipi_hd/display-timings/timing0";
		td4160_cw_old_timing1 = "/fragment/__overlay__/lcds/lcd_td4160_cw_old_mipi_hd/display-timings/timing1";
		lcd_td4160b_cw_boe_mipi_hd = "/fragment/__overlay__/lcds/lcd_td4160b_cw_boe_mipi_hd";
		td4160b_cw_boe_timing0 = "/fragment/__overlay__/lcds/lcd_td4160b_cw_boe_mipi_hd/display-timings/timing0";
		td4160b_cw_boe_timing1 = "/fragment/__overlay__/lcds/lcd_td4160b_cw_boe_mipi_hd/display-timings/timing1";
		lcd_hx83108a_lce_mipi_hd = "/fragment/__overlay__/lcds/lcd_hx83108a_lce_mipi_hd";
		hx83108a_lce_timing0 = "/fragment/__overlay__/lcds/lcd_hx83108a_lce_mipi_hd/display-timings/timing0";
		hx83108a_lce_timing1 = "/fragment/__overlay__/lcds/lcd_hx83108a_lce_mipi_hd/display-timings/timing1";
		lcd_hx83108a_boe_mipi_hd = "/fragment/__overlay__/lcds/lcd_hx83108a_boe_mipi_hd";
		hx83108a_boe_timing0 = "/fragment/__overlay__/lcds/lcd_hx83108a_boe_mipi_hd/display-timings/timing0";
		hx83108a_boe_timing1 = "/fragment/__overlay__/lcds/lcd_hx83108a_boe_mipi_hd/display-timings/timing1";
		lcd_ft8057_ld_mipi_hd = "/fragment/__overlay__/lcds/lcd_ft8057_ld_mipi_hd";
		ft8057_ld_timing0 = "/fragment/__overlay__/lcds/lcd_ft8057_ld_mipi_hd/display-timings/timing0";
		ft8057_ld_timing1 = "/fragment/__overlay__/lcds/lcd_ft8057_ld_mipi_hd/display-timings/timing1";
		lcd_icnl9916c_hjc_cd_mipi_hd = "/fragment/__overlay__/lcds/lcd_icnl9916c_hjc_cd_mipi_hd";
		icnl9916c_hjc_cd_timing0 = "/fragment/__overlay__/lcds/lcd_icnl9916c_hjc_cd_mipi_hd/display-timings/timing0";
		icnl9916c_hjc_cd_timing1 = "/fragment/__overlay__/lcds/lcd_icnl9916c_hjc_cd_mipi_hd/display-timings/timing1";
		lcd_icnl9916c_ld_hjc_mipi_hd = "/fragment/__overlay__/lcds/lcd_icnl9916c_ld_hjc_mipi_hd";
		icnl9916c_ld_hjc_timing0 = "/fragment/__overlay__/lcds/lcd_icnl9916c_ld_hjc_mipi_hd/display-timings/timing0";
		icnl9916c_ld_hjc_timing1 = "/fragment/__overlay__/lcds/lcd_icnl9916c_ld_hjc_mipi_hd/display-timings/timing1";
		lcd_icnl9916c_inx_mipi_hd = "/fragment/__overlay__/lcds/lcd_icnl9916c_inx_mipi_hd";
		icnl9916c_inx_timing0 = "/fragment/__overlay__/lcds/lcd_icnl9916c_inx_mipi_hd/display-timings/timing0";
		icnl9916c_inx_timing1 = "/fragment/__overlay__/lcds/lcd_icnl9916c_inx_mipi_hd/display-timings/timing1";
		lcd_ft8057p_ld_mipi_hd = "/fragment/__overlay__/lcds/lcd_ft8057p_ld_mipi_hd";
		ft8057p_ld_timing0 = "/fragment/__overlay__/lcds/lcd_ft8057p_ld_mipi_hd/display-timings/timing0";
		ft8057p_ld_timing1 = "/fragment/__overlay__/lcds/lcd_ft8057p_ld_mipi_hd/display-timings/timing1";
		wcn_btwf = "/fragment/__overlay__/cpwcn-btwf";
		sprd_wlan = "/fragment/__overlay__/cpwcn-btwf/wlan";
		wcn_gnss = "/fragment/__overlay__/cpwcn-gnss";
		pwm_backlight = "/fragment/__overlay__/sprd_backlight";
		skin_sensor = "/fragment/__overlay__/skin-sensor";
		bq2560x_chg = "/fragment@3/__overlay__/charger@6b";
		vddvbus = "/fragment@3/__overlay__/charger@6b/otg-vbus";
		bq2597x_chg = "/fragment@3/__overlay__/charger@65";
		usb_con = "/fragment@6/__overlay__/connector";
		protected_reserved = "/fragment@7/__overlay__/protected-mem@80003000";
		secured_reserved = "/fragment@7/__overlay__/secured@ff870000";
		fd_reserved = "/fragment@7/__overlay__/faceid-mem@ffa70000";
		sipc_wcn = "/fragment@8/__overlay__/core@3";
		sipc_gnss = "/fragment@8/__overlay__/core@4";
		sttygnss0 = "/fragment@8/__overlay__/core@4/channel@4";
		sensor_main = "/fragment@11/__overlay__/sensor-main@20";
		sensor_sub = "/fragment@11/__overlay__/sensor-sub@5a";
		sensor_main2 = "/fragment@12/__overlay__/sensor-main2@20";
		hl1506_cp_converter = "/fragment@13/__overlay__/charger@1b";
		nu1619_rx = "/fragment@13/__overlay__/charger@61";
		flash_ic = "/fragment@13/__overlay__/flash-ic@63";
		sensor_sub2 = "/fragment@14/__overlay__/sensor-sub2@6e";
		ucp1301_rcv = "/fragment@19/__overlay__/ucp1301@58";
		ucp1301_spk = "/fragment@21/__overlay__/ucp1301@58";
		stm_vl53l0 = "/fragment@21/__overlay__/vl53l0@52";
		gpio_8 = "/fragment@31/__overlay__/rfctl16";
		gpio_22 = "/fragment@31/__overlay__/rfctl3";
		gpio_24 = "/fragment@31/__overlay__/rfctl5";
		gpio_25 = "/fragment@31/__overlay__/rfctl6";
		gpio_26 = "/fragment@31/__overlay__/rfctl7";
		gpio_124 = "/fragment@31/__overlay__/keyin0";
		gpio_175 = "/fragment@31/__overlay__/bt_rfctl2";
	};

	__fixups__ {
		aon_apb_regs = "/fragment/__overlay__/cpwcn-btwf:sprd,syscon-ap-apb:0", "/fragment/__overlay__/cpwcn-gnss:sprd,syscon-ap-apb:0", "/fragment@6/__overlay__:sprd,syscon-aon-apb:0";
		pmu_apb_regs = "/fragment/__overlay__/cpwcn-btwf:sprd,syscon-ap-pmu:0", "/fragment/__overlay__/cpwcn-gnss:sprd,syscon-ap-pmu:0";
		wcncp_aon_apb_regs = "/fragment/__overlay__/cpwcn-btwf:sprd,syscon-wcn-aon-apb:0", "/fragment/__overlay__/cpwcn-gnss:sprd,syscon-wcn-aon-apb:0";
		wcncp_aon_ahb_regs = "/fragment/__overlay__/cpwcn-btwf:sprd,syscon-wcn-aon-ahb:0", "/fragment/__overlay__/cpwcn-gnss:sprd,syscon-wcn-aon-ahb:0";
		pub_apb_regs = "/fragment/__overlay__/cpwcn-btwf:sprd,syscon-ap-pub-apb:0", "/fragment/__overlay__/cpwcn-gnss:sprd,syscon-ap-pub-apb:0";
		wcncp_btwf_ahb_regs = "/fragment/__overlay__/cpwcn-btwf:sprd,syscon-wcn-btwf-ahb:0";
		vddwcn = "/fragment/__overlay__/cpwcn-btwf:vddwcn-supply:0", "/fragment/__overlay__/cpwcn-gnss:vddwcn-supply:0";
		vddsim2 = "/fragment/__overlay__/cpwcn-btwf:dcxo1v8-supply:0", "/fragment/__overlay__/cpwcn-gnss:dcxo1v8-supply:0";
		vddwifipa = "/fragment/__overlay__/cpwcn-btwf:vddwifipa-supply:0";
		ap_gpio = "/fragment/__overlay__/cpwcn-btwf:merlion-chip-en-gpios:0", "/fragment/__overlay__/cpwcn-btwf:merlion-rst-gpios:0", "/fragment/__overlay__/cpwcn-btwf:xtal-26m-type-sel-gpios:0", "/fragment/__overlay__/cpwcn-gnss:merlion-chip-en-gpios:0", "/fragment/__overlay__/cpwcn-gnss:merlion-rst-gpios:0", "/fragment/__overlay__/gpio-keys/key-volumedown:gpios:0", "/fragment/__overlay__/audio-voice-trig:irq_gpio:0", "/fragment@0/__overlay__/omnivision_tcm@0:omnivision,irq-gpio:0", "/fragment@0/__overlay__/omnivision_tcm@0:omnivision,reset-gpio:0", "/fragment@0/__overlay__/omnivision_tcm@0:himax,irq-gpio:0", "/fragment@0/__overlay__/omnivision_tcm@0:himax,rst-gpio:0", "/fragment@0/__overlay__/omnivision_tcm@0:focaltech,reset-gpio:0", "/fragment@0/__overlay__/omnivision_tcm@0:focaltech,irq-gpio:0", "/fragment@0/__overlay__/omnivision_tcm@0:chipone,rst-gpio:0", "/fragment@0/__overlay__/omnivision_tcm@0:chipone,irq-gpio:0", "/fragment@0/__overlay__/omnivision_tcm@0:jadard,irq-gpio:0", "/fragment@0/__overlay__/omnivision_tcm@0:jadard,rst-gpio:0", "/fragment@3/__overlay__/charger@6b:irq-gpio:0", "/fragment@3/__overlay__/charger@65:irq-gpio:0", "/fragment@11/__overlay__/sensor-main@20:dvdd-gpios:0", "/fragment@11/__overlay__/sensor-main@20:reset-gpios:0", "/fragment@11/__overlay__/sensor-main@20:power-down-gpios:0", "/fragment@11/__overlay__/sensor-sub@5a:dvdd-gpios:0", "/fragment@11/__overlay__/sensor-sub@5a:reset-gpios:0", "/fragment@11/__overlay__/sensor-sub@5a:power-down-gpios:0", "/fragment@12/__overlay__/sensor-main2@20:avdd-gpios:0", "/fragment@12/__overlay__/sensor-main2@20:mot-gpios:0", "/fragment@12/__overlay__/sensor-main2@20:reset-gpios:0", "/fragment@12/__overlay__/sensor-main2@20:power-down-gpios:0", "/fragment@13/__overlay__/charger@1b:chg_pump_en_gpio:0", "/fragment@13/__overlay__/charger@61:rx,irq_gpio:0", "/fragment@13/__overlay__/charger@61:switch_chg_en_gpio:0", "/fragment@13/__overlay__/charger@61:switch_flag_en_gpio:0", "/fragment@13/__overlay__/flash-ic@63:flash-torch-en-gpios:0", "/fragment@13/__overlay__/flash-ic@63:flash-chip-en-gpios:0", "/fragment@13/__overlay__/flash-ic@63:flash-en-gpios:0", "/fragment@13/__overlay__/flash-ic@63:flash-sync-gpios:0", "/fragment@14/__overlay__/sensor-sub2@6e:avdd-gpios:0", "/fragment@14/__overlay__/sensor-sub2@6e:mot-gpios:0", "/fragment@14/__overlay__/sensor-sub2@6e:reset-gpios:0", "/fragment@19/__overlay__/sec-nfc@27:sec-nfc,ven-gpio:0", "/fragment@19/__overlay__/sec-nfc@27:sec-nfc,firm-gpio:0", "/fragment@19/__overlay__/sec-nfc@27:sec-nfc,irq-gpio:0", "/fragment@19/__overlay__/sec-nfc@27:sec-nfc,clk-req:0", "/fragment@19/__overlay__/ucp1301@58:reset-gpios:0", "/fragment@21/__overlay__/ucp1301@58:reset-gpios:0", "/fragment@21/__overlay__/vl53l0@52:interrupt-parent:0", "/fragment@23/__overlay__:mic-gpios:0", "/fragment@23/__overlay__:lr-gpios:0", "/fragment@28/__overlay__:avdd-gpio:0", "/fragment@28/__overlay__:avee-gpio:0", "/fragment@28/__overlay__:reset-gpio:0";
		wcn_alpha = "/fragment/__overlay__/cpwcn-btwf:nvmem-cells:0", "/fragment/__overlay__/cpwcn-gnss:nvmem-cells:0";
		wcncp_gnss_ahb_regs = "/fragment/__overlay__/cpwcn-gnss:sprd,syscon-wcn-gnss-ahb:0";
		pwms = "/fragment/__overlay__/sprd_backlight:pwms:0";
		bd_thmzone = "/fragment/__overlay__/skin-sensor:thmzone-cells:0";
		eic_async = "/fragment/__overlay__/fingerprint@0:fpint-gpios:0";
		pmic_eic = "/fragment/__overlay__/gpio-keys/key-volumeup:gpios:0", "/fragment/__overlay__/gpio-keys/key-power:gpios:0";
		uid_start = "/fragment/__overlay__/sprd-uid:nvmem-cells:0";
		uid_end = "/fragment/__overlay__/sprd-uid:nvmem-cells:4";
		spi3 = "/fragment@0:target:0";
		bat = "/fragment@1:target:0", "/fragment@2/__overlay__:monitored-battery-0:0", "/fragment@3/__overlay__/charger@6b:monitored-battery-0:0", "/fragment@4/__overlay__:monitored-battery-0:0";
		cm = "/fragment@2:target:0";
		hsphy = "/fragment@2/__overlay__:phys:0", "/fragment@4/__overlay__:phys:0", "/fragment@13/__overlay__/charger@61:phys:0", "/fragment@15:target:0";
		pmic_typec = "/fragment@2/__overlay__:extcon:0", "/fragment@4/__overlay__:extcon:0", "/fragment@15/__overlay__:extcon:0", "/fragment@16/__overlay__:extcon:0", "/fragment@16/__overlay__:extcon:4", "/fragment@17:target:0", "/fragment@23/__overlay__:extcon:0";
		pmic_pd = "/fragment@2/__overlay__:extcon:4", "/fragment@6:target:0";
		i2c5 = "/fragment@3:target:0", "/fragment@13:target:0";
		pmic_fgu = "/fragment@4:target:0";
		pmic_fchg = "/fragment@5:target:0";
		reserved_memory = "/fragment@7:target:0";
		sipc = "/fragment@8:target:0";
		mailbox = "/fragment@8/__overlay__/core@3:mboxes:0", "/fragment@8/__overlay__/core@4:mboxes:0";
		chosen = "/fragment@9:target:0";
		skin_thmzone = "/fragment@10:target:0";
		i2c0 = "/fragment@11:target:0";
		mm_clk = "/fragment@11/__overlay__/sensor-main@20:clocks:0", "/fragment@11/__overlay__/sensor-sub@5a:clocks:0", "/fragment@12/__overlay__/sensor-main2@20:clocks:0", "/fragment@14/__overlay__/sensor-sub2@6e:clocks:0";
		mm_gate = "/fragment@11/__overlay__/sensor-main@20:clocks:8", "/fragment@11/__overlay__/sensor-sub@5a:clocks:8", "/fragment@12/__overlay__/sensor-main2@20:clocks:8", "/fragment@14/__overlay__/sensor-sub2@6e:clocks:8";
		pll1 = "/fragment@11/__overlay__/sensor-main@20:clocks:16", "/fragment@11/__overlay__/sensor-main@20:clocks:24", "/fragment@11/__overlay__/sensor-main@20:clocks:32", "/fragment@11/__overlay__/sensor-sub@5a:clocks:16", "/fragment@11/__overlay__/sensor-sub@5a:clocks:24", "/fragment@11/__overlay__/sensor-sub@5a:clocks:32", "/fragment@12/__overlay__/sensor-main2@20:clocks:16", "/fragment@12/__overlay__/sensor-main2@20:clocks:24", "/fragment@12/__overlay__/sensor-main2@20:clocks:32", "/fragment@14/__overlay__/sensor-sub2@6e:clocks:16", "/fragment@14/__overlay__/sensor-sub2@6e:clocks:24", "/fragment@14/__overlay__/sensor-sub2@6e:clocks:32";
		ext_26m = "/fragment@11/__overlay__/sensor-main@20:clocks:40", "/fragment@11/__overlay__/sensor-sub@5a:clocks:40", "/fragment@12/__overlay__/sensor-main2@20:clocks:40", "/fragment@14/__overlay__/sensor-sub2@6e:clocks:40", "/fragment@19/__overlay__/sec-nfc@27:clocks:8";
		vddcamio = "/fragment@11/__overlay__/sensor-main@20:vddio-supply:0", "/fragment@11/__overlay__/sensor-sub@5a:vddio-supply:0", "/fragment@12/__overlay__/sensor-main2@20:vddio-supply:0", "/fragment@14/__overlay__/sensor-sub2@6e:vddio-supply:0";
		vddcama0 = "/fragment@11/__overlay__/sensor-main@20:vddcama-supply:0", "/fragment@11/__overlay__/sensor-sub@5a:vddcama-supply:0";
		vddcammot = "/fragment@11/__overlay__/sensor-main@20:vddcammot-supply:0", "/fragment@11/__overlay__/sensor-sub@5a:vddcammot-supply:0", "/fragment@12/__overlay__/sensor-main2@20:vddcammot-supply:0", "/fragment@14/__overlay__/sensor-sub2@6e:vddcammot-supply:0";
		csi0 = "/fragment@11/__overlay__/sensor-main@20:csi:0", "/fragment@11/__overlay__/sensor-sub@5a:csi:0";
		mm_domain = "/fragment@11/__overlay__/sensor-main@20:power-domains:0", "/fragment@11/__overlay__/sensor-sub@5a:power-domains:0", "/fragment@12/__overlay__/sensor-main2@20:power-domains:0";
		i2c1 = "/fragment@12:target:0";
		vddcama1 = "/fragment@12/__overlay__/sensor-main2@20:vddcama-supply:0";
		vddcamd0 = "/fragment@12/__overlay__/sensor-main2@20:vddcamd-supply:0";
		csi1 = "/fragment@12/__overlay__/sensor-main2@20:csi:0";
		i2c6 = "/fragment@14:target:0";
		vddcamd1 = "/fragment@14/__overlay__/sensor-sub2@6e:vddcamd-supply:0";
		csi2 = "/fragment@14/__overlay__/sensor-sub2@6e:csi:0";
		vddusb33 = "/fragment@15/__overlay__:vdd-supply:0";
		usb = "/fragment@16:target:0";
		extcon_gpio = "/fragment@17/__overlay__:extcon:0";
		sdio0 = "/fragment@18:target:0";
		eic_sync = "/fragment@18/__overlay__:cd-gpios:0";
		i2c2 = "/fragment@19:target:0";
		aon_clk = "/fragment@19/__overlay__/sec-nfc@27:clocks:0";
		aonapb_gate = "/fragment@19/__overlay__/sec-nfc@27:clocks:12";
		i2c3 = "/fragment@20:target:0";
		i2c4 = "/fragment@21:target:0";
		aon_i2c0 = "/fragment@22:target:0";
		sprd_headset = "/fragment@23:target:0";
		pdm_dmic = "/fragment@24:target:0", "/fragment@26/__overlay__/sprd-audio-card,dai-link@81/codec:sound-dai:0";
		agdsp_domain = "/fragment@25:target:0";
		sound_vbc_v4_sprd_codec = "/fragment@26:target:0";
		sprd_route_pcm = "/fragment@26/__overlay__/sprd-audio-card,dai-link@53/plat:sound-dai:0", "/fragment@26/__overlay__/sprd-audio-card,dai-link@55/plat:sound-dai:0", "/fragment@26/__overlay__/sprd-audio-card,dai-link@81/plat:sound-dai:0";
		vbc_v4 = "/fragment@26/__overlay__/sprd-audio-card,dai-link@53/cpu:sound-dai:0", "/fragment@26/__overlay__/sprd-audio-card,dai-link@55/cpu:sound-dai:0", "/fragment@26/__overlay__/sprd-audio-card,dai-link@81/cpu:sound-dai:0";
		vddldo0 = "/fragment@27:target:0";
		panel = "/fragment@28:target:0";
		dpu = "/fragment@29:target:0";
		logo_reserved = "/fragment@29/__overlay__:sprd,logo-memory:0";
		ddr_dfs = "/fragment@30:target:0";
		pin_controller = "/fragment@31:target:0";
		dmabuf = "/fragment@32:target:0";
		adi_bus = "/fragment@33:target:0";
	};

	__local_fixups__ {

		fragment {

			__overlay__ {

				lcds {

					lcd_g40396_truly_mipi_fhd {

						display-timings {
							native-mode = <0x00>;
						};
					};

					lcd_nt36672e_truly_mipi_fhd_nodsc {

						display-timings {
							native-mode = <0x00>;
						};
					};

					lcd_ft8725_boe_mipi_fhd_nodsc {

						display-timings {
							native-mode = <0x00>;
						};
					};

					lcd_dummy_mipi_hd {

						display-timings {
							native-mode = <0x00>;
						};
					};

					lcd_td4160_cw_mipi_hd {

						display-timings {
							native-mode = <0x00>;
						};
					};

					lcd_td4160_cw_new_mipi_hd {

						display-timings {
							native-mode = <0x00>;
						};
					};

					lcd_td4160_cw_old_mipi_hd {

						display-timings {
							native-mode = <0x00>;
						};
					};

					lcd_td4160b_cw_boe_mipi_hd {

						display-timings {
							native-mode = <0x00>;
						};
					};

					lcd_hx83108a_lce_mipi_hd {

						display-timings {
							native-mode = <0x00>;
						};
					};

					lcd_hx83108a_boe_mipi_hd {

						display-timings {
							native-mode = <0x00>;
						};
					};

					lcd_ft8057_ld_mipi_hd {

						display-timings {
							native-mode = <0x00>;
						};
					};

					lcd_icnl9916c_hjc_cd_mipi_hd {

						display-timings {
							native-mode = <0x00>;
						};
					};

					lcd_icnl9916c_ld_hjc_mipi_hd {

						display-timings {
							native-mode = <0x00>;
						};
					};

					lcd_icnl9916c_inx_mipi_hd {

						display-timings {
							native-mode = <0x00>;
						};
					};

					lcd_ft8057p_ld_mipi_hd {

						display-timings {
							native-mode = <0x00>;
						};
					};
				};
			};
		};

		fragment@0 {

			__overlay__ {

				omnivision_tcm@0 {
					panel = <0x00 0x04 0x08 0x0c 0x10 0x14 0x18 0x1c 0x20 0x24 0x28>;
				};
			};
		};

		fragment@6 {

			__overlay__ {
				vbus-supply = <0x00>;
			};
		};

		fragment@10 {

			__overlay__ {
				thermal-sensors = <0x00>;
			};
		};

		fragment@16 {

			__overlay__ {
				vbus-supply = <0x00>;
			};
		};

		fragment@26 {

			__overlay__ {

				sprd-audio-card,dai-link@53 {

					codec {
						sound-dai = <0x00>;
					};
				};

				sprd-audio-card,dai-link@55 {

					codec {
						sound-dai = <0x00>;
					};
				};
			};
		};

		fragment@28 {

			__overlay__ {
				sprd,backlight = <0x00>;
			};
		};

		fragment@29 {

			__overlay__ {
				sprd,backlight = <0x00>;
			};
		};

		fragment@31 {

			__overlay__ {
				pinctrl-0 = <0x00>;
				pinctrl-1 = <0x00>;
				pinctrl-2 = <0x00>;
				pinctrl-3 = <0x00>;
				pinctrl-4 = <0x00>;
				pinctrl-5 = <0x00>;
				pinctrl-6 = <0x00>;
			};
		};

		fragment@32 {

			__overlay__ {

				secured-reserved {
					memory-region = <0x00>;
				};

				fd-reserved {
					memory-region = <0x00>;
				};

				protected-reserved {
					memory-region = <0x00>;
				};
			};
		};
	};
};
